VERSION ""

NS_ :

BS_:

BU_: HCM IPMA_ADAS PSCM GWM _delete SCCM PDM DDM GENERIC TSTR

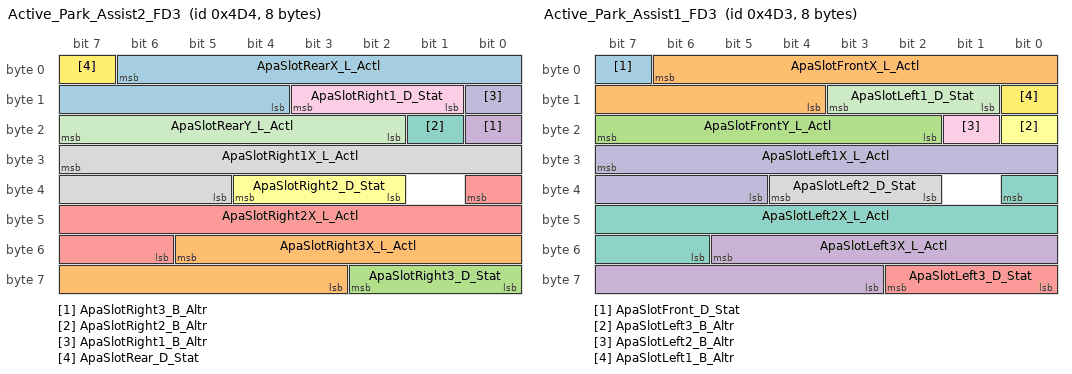
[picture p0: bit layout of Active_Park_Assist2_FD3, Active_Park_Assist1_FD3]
BO_ 1236 Active_Park_Assist2_FD3: 8 IPMA_ADAS
 SG_ ApaSlotRearX_L_Actl : 6|11@0+ (0.02,-20.96) [-20.96|19.98] "meter" Vector__XXX
 SG_ ApaSlotRight3X_L_Actl : 53|11@0+ (0.02,-20.96) [-20.96|19.98] "meter"  GWM
 SG_ ApaSlotRight3_D_Stat : 58|3@0+ (1,0) [0|7] "SED"  GWM
 SG_ ApaSlotRight3_B_Altr : 16|1@0+ (1,0) [0|1] "SED"  GWM
 SG_ ApaSlotRight2X_L_Actl : 32|11@0+ (0.02,-20.96) [-20.96|19.98] "meter"  GWM
 SG_ ApaSlotRight2_D_Stat : 36|3@0+ (1,0) [0|7] "SED"  GWM
 SG_ ApaSlotRight2_B_Altr : 17|1@0+ (1,0) [0|1] "SED"  GWM
 SG_ ApaSlotRight1X_L_Actl : 31|11@0+ (0.02,-20.96) [-20.96|19.98] "meter"  GWM
 SG_ ApaSlotRight1_D_Stat : 11|3@0+ (1,0) [0|7] "SED"  GWM
 SG_ ApaSlotRight1_B_Altr : 8|1@0+ (1,0) [0|1] "SED"  GWM
 SG_ ApaSlotRearY_L_Actl : 23|6@0+ (0.2,-6.4) [-6.4|6.2] "meter" Vector__XXX
 SG_ ApaSlotRear_D_Stat : 7|1@0+ (1,0) [0|1] "SED" Vector__XXX

BO_ 1235 Active_Park_Assist1_FD3: 8 IPMA_ADAS
 SG_ ApaSlotFront_D_Stat : 7|1@0+ (1,0) [0|1] "SED" Vector__XXX
 SG_ ApaSlotFrontX_L_Actl : 6|11@0+ (0.02,-20.96) [-20.96|19.98] "meter" Vector__XXX
 SG_ ApaSlotFrontY_L_Actl : 23|6@0+ (0.2,-6.4) [-6.4|6.2] "meter" Vector__XXX
 SG_ ApaSlotLeft3X_L_Actl : 53|11@0+ (0.02,-20.96) [-20.96|19.98] "meter"  GWM
 SG_ ApaSlotLeft3_D_Stat : 58|3@0+ (1,0) [0|7] "SED"  GWM
 SG_ ApaSlotLeft3_B_Altr : 16|1@0+ (1,0) [0|1] "SED"  GWM
 SG_ ApaSlotLeft2X_L_Actl : 32|11@0+ (0.02,-20.96) [-20.96|19.98] "meter"  GWM
 SG_ ApaSlotLeft2_D_Stat : 36|3@0+ (1,0) [0|7] "SED"  GWM
 SG_ ApaSlotLeft2_B_Altr : 17|1@0+ (1,0) [0|1] "SED"  GWM
 SG_ ApaSlotLeft1X_L_Actl : 31|11@0+ (0.02,-20.96) [-20.96|19.98] "meter"  GWM
 SG_ ApaSlotLeft1_D_Stat : 11|3@0+ (1,0) [0|7] "SED"  GWM
 SG_ ApaSlotLeft1_B_Altr : 8|1@0+ (1,0) [0|1] "SED"  GWM

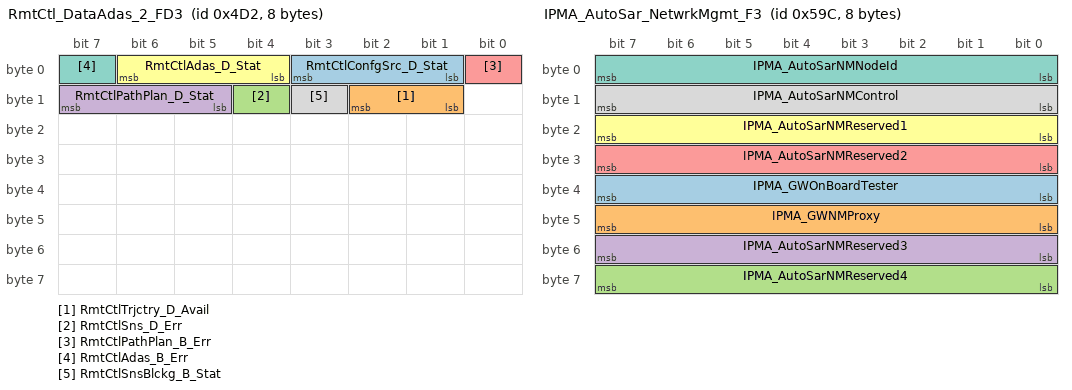
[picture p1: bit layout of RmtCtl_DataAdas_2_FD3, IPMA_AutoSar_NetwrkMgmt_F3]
BO_ 1234 RmtCtl_DataAdas_2_FD3: 8 IPMA_ADAS
 SG_ RmtCtlConfgSrc_D_Stat : 3|3@0+ (1,0) [0|7] "SED"  GWM
 SG_ RmtCtlTrjctry_D_Avail : 10|2@0+ (1,0) [0|3] "SED"  GWM
 SG_ RmtCtlSns_D_Err : 12|1@0+ (1,0) [0|1] "SED"  GWM
 SG_ RmtCtlPathPlan_D_Stat : 15|3@0+ (1,0) [0|7] "SED"  GWM
 SG_ RmtCtlPathPlan_B_Err : 0|1@0+ (1,0) [0|1] "SED"  GWM
 SG_ RmtCtlAdas_D_Stat : 6|3@0+ (1,0) [0|7] "SED"  GWM
 SG_ RmtCtlAdas_B_Err : 7|1@0+ (1,0) [0|1] "SED"  GWM
 SG_ RmtCtlSnsBlckg_B_Stat : 11|1@0+ (1,0) [0|1] "SED"  GWM

BO_ 1436 IPMA_AutoSar_NetwrkMgmt_F3: 8 IPMA_ADAS
 SG_ IPMA_GWOnBoardTester : 39|8@0+ (1,0) [0|255] "unitless"  GENERIC
 SG_ IPMA_GWNMProxy : 47|8@0+ (1,0) [0|255] "unitless"  GENERIC
 SG_ IPMA_AutoSarNMReserved4 : 63|8@0+ (1,0) [0|255] "unitless"  GENERIC
 SG_ IPMA_AutoSarNMReserved3 : 55|8@0+ (1,0) [0|255] "unitless"  GENERIC
 SG_ IPMA_AutoSarNMReserved2 : 31|8@0+ (1,0) [0|255] "unitless"  GENERIC
 SG_ IPMA_AutoSarNMReserved1 : 23|8@0+ (1,0) [0|255] "unitless"  GENERIC
 SG_ IPMA_AutoSarNMNodeId : 7|8@0+ (1,0) [0|255] "unitless"  GENERIC
 SG_ IPMA_AutoSarNMControl : 15|8@0+ (1,0) [0|255] "unitless"  GENERIC

BO_ 1233 RmtCtl_DataAdas_1_FD3: 8 IPMA_ADAS
 SG_ FreeDrvRear_D_Avail : 27|2@0+ (1,0) [0|3] "SED"  GWM
 SG_ FreeDrvFwd_D_Avail : 7|2@0+ (1,0) [0|3] "SED"  GWM
 SG_ RmtCtlTrgDist_D_Stat : 63|8@0+ (0.1,0) [0|25.5] "meter"  GWM
 SG_ RmtCtlSnsRrCrnr_D_Stat : 55|2@0+ (1,0) [0|3] "SED"  GWM
 SG_ RmtCtlSnsRlCrnr_D_Stat : 49|2@0+ (1,0) [0|3] "SED"  GWM
 SG_ RmtCtlSnsRear_D_Stat : 51|2@0+ (1,0) [0|3] "SED"  GWM
 SG_ RmtCtlSnsFront_D_Stat : 53|2@0+ (1,0) [0|3] "SED"  GWM
 SG_ RmtCtlSnsFrCrnr_D_Stat : 41|2@0+ (1,0) [0|3] "SED"  GWM
 SG_ RmtCtlSnsFlCrnr_D_Stat : 43|2@0+ (1,0) [0|3] "SED"  GWM
 SG_ RmtCtlSideSnsR4_D_Stat : 45|2@0+ (1,0) [0|3] "SED"  GWM
 SG_ RmtCtlSideSnsR3_D_Stat : 47|2@0+ (1,0) [0|3] "SED"  GWM
 SG_ RmtCtlSideSnsR2_D_Stat : 33|2@0+ (1,0) [0|3] "SED"  GWM
 SG_ RmtCtlSideSnsR1_D_Stat : 35|2@0+ (1,0) [0|3] "SED"  GWM
 SG_ RmtCtlSideSnsL4_D_Stat : 37|2@0+ (1,0) [0|3] "SED"  GWM
 SG_ RmtCtlSideSnsL3_D_Stat : 39|2@0+ (1,0) [0|3] "SED"  GWM
 SG_ RmtCtlSideSnsL2_D_Stat : 25|2@0+ (1,0) [0|3] "SED"  GWM
 SG_ RmtCtlSideSnsL1_D_Stat : 17|2@0+ (1,0) [0|3] "SED"  GWM
 SG_ RmtCtlRightOrnt_D_Avail : 20|3@0+ (1,0) [0|7] "SED"  GWM
 SG_ RmtCtlRight_D_Avail : 31|2@0+ (1,0) [0|3] "SED"  GWM
 SG_ RmtCtlRear_D_Avail : 29|2@0+ (1,0) [0|3] "SED"  GWM
 SG_ RmtCtlPrkMde_D_Stat : 9|2@0+ (1,0) [0|3] "SED"  GWM
 SG_ RmtCtlPrkInSlot_D_Stat : 23|3@0+ (1,0) [0|7] "SED"  GWM
 SG_ RmtCtlObstcl_B_Stat : 10|1@0+ (1,0) [0|1] "SED"  GWM
 SG_ RmtCtlNxtMoveDir_D_Stat : 12|2@0+ (1,0) [0|3] "SED"  GWM
 SG_ RmtCtlMoveDir_D_Stat : 1|2@0+ (1,0) [0|3] "SED"  GWM
 SG_ RmtCtlLeftOrnt_D_Avail : 15|3@0+ (1,0) [0|7] "SED"  GWM
 SG_ RmtCtlLeft_D_Avail : 3|2@0+ (1,0) [0|3] "SED"  GWM
 SG_ RmtCtlFront_D_Avail : 5|2@0+ (1,0) [0|3] "SED"  GWM

BO_ 817 Locking_Systems_2_FD3: 16 GWM
 SG_ ChildLckMde_B_Stat : 56|1@0+ (1,0) [0|1] "SED"  GENERIC
 SG_ VehLckInd_D_Rq : 58|2@0+ (1,0) [0|3] "SED"  PDM,DDM
 SG_ DrTgateOpen_B_Rq : 59|1@0+ (1,0) [0|1] "SED"  GENERIC
 SG_ DrTgateExtSwMde_B_Stat : 32|1@0+ (1,0) [0|1] "SED"  GENERIC
 SG_ Remote_Device_Feedback : 50|3@0+ (1,0) [0|7] "SED"  GENERIC
 SG_ Veh_Lock_Requestor : 55|5@0+ (1,0) [0|31] "SED"  PDM,DDM
 SG_ R_Pwr_Sliding_Dr_Rqst : 36|1@0+ (1,0) [0|1] "SED"  GENERIC
 SG_ Power_Liftgate_Rqst : 0|1@0+ (1,0) [0|1] "SED"  GENERIC
 SG_ Veh_Lock_EvNum : 47|8@0+ (1,0) [0|255] "unitless"  PDM,DDM
 SG_ Power_Decklid_Rqst : 1|1@0+ (1,0) [0|1] "SED"  GENERIC
 SG_ L_Pwr_Sliding_Dr_Rqst : 3|1@0+ (1,0) [0|1] "SED"  GENERIC
 SG_ Keyfob_Pad_Msg_Count : 15|8@0+ (1,0) [0|255] "Counts"  GENERIC
 SG_ Veh_Lock_Sub_Id : 63|4@0+ (1,0) [0|15] "SED"  PDM,DDM
 SG_ Veh_Lock_Status : 34|2@0+ (1,0) [0|3] "SED"  PDM,DDM,IPMA_ADAS
 SG_ WindowLockout_B_Stat : 35|1@0+ (1,0) [0|1] "SED"  DDM
 SG_ RollCodeUnlock : 23|16@0+ (1,0) [0|65535] "unitless"  PDM,DDM
 SG_ Lockmsgtxt_D_Rq : 39|3@0+ (1,0) [0|7] "SED"  GENERIC
 SG_ FobComm_D_Stat : 5|2@0+ (1,0) [0|3] "SED"  GENERIC
 SG_ LockInhibit : 2|1@0+ (1,0) [0|1] "SED"  GENERIC

BO_ 2612194520 PARSEDPushFcGWM_ECGtoCMR: 8 GWM
 SG_ PARSEDPushFcGWM_ECGtoCMR : 7|29@0+ (1,0) [0|536870911] "unitless" Vector__XXX

BO_ 2611145944 PARSEDPhyGWM_ECGtoCMR: 64 GWM
 SG_ PARSEDPhysGWM_ECGtoCMR : 7|29@0+ (1,0) [0|536870911] "unitless" Vector__XXX

BO_ 954 Body_Info_10_FD3: 16 GWM
 SG_ CrtsyLghtRear_D_Stat : 63|2@0+ (1,0) [0|3] "SED"  _delete
 SG_ LoadShedRelayMde_D_Stat : 53|2@0+ (1,0) [0|3] "SED"  _delete
 SG_ CargoLght_D_Stat : 55|2@0+ (1,0) [0|3] "SED"  _delete
 SG_ KeylessIdl_B_Stat : 41|1@0+ (1,0) [0|1] "SED"  _delete
 SG_ TlghtTestLght_D_Stat : 44|3@0+ (1,0) [0|7] "SED"  _delete
 SG_ TlghtTestPrecnd_D_Stat : 47|3@0+ (1,0) [0|7] "SED"  _delete
 SG_ TlghtTest_D_Stat : 33|2@0+ (1,0) [0|3] "SED"  _delete
 SG_ LghtAmbDrvMde_B_Stat : 34|1@0+ (1,0) [0|1] "SED"  _delete
 SG_ TrukBedLght_B_Stat : 24|1@0+ (1,0) [0|1] "SED"  _delete
 SG_ TrlrHitchLamp_D_Stat : 25|1@0+ (1,0) [0|1] "SED"  _delete
 SG_ LicPlateLght_B_Stat : 26|1@0+ (1,0) [0|1] "SED"  _delete
 SG_ ExtLghtRight_D_Stat : 21|2@0+ (1,0) [0|3] "SED"  _delete
 SG_ ExtLghtRear_D_Stat : 23|2@0+ (1,0) [0|3] "SED"  _delete
 SG_ ExtLghtLeft_D_Stat : 9|2@0+ (1,0) [0|3] "SED"  _delete
 SG_ ExtLghtFront_D_Stat : 11|2@0+ (1,0) [0|3] "SED"  _delete
 SG_ ExtLghtAlrt_B_Rq : 12|1@0+ (1,0) [0|1] "SED"  _delete
 SG_ ExtLght_D_Falt : 1|2@0+ (1,0) [0|3] "SED"  _delete
 SG_ TrlrHitchLamp_D2_Stat : 57|2@0+ (1,0) [0|3] "SED" Vector__XXX
 SG_ ChildLckMaint_D_Stat : 59|2@0+ (1,0) [0|3] "SED"  IPMA_ADAS
 SG_ ExtLghtFront_D_RqBody : 61|2@0+ (1,0) [0|3] "SED"  HCM
 SG_ LoadShedRelay_B_Rq : 40|1@0+ (1,0) [0|1] "SED" Vector__XXX
 SG_ VehWlcmFrwlMde_D_Stat : 29|3@0+ (1,0) [0|7] "SED"  PDM,DDM,HCM
 SG_ PwRnngBoardPoll_D_Stat : 36|2@0+ (1,0) [0|3] "SED"  PDM
 SG_ GenericSwtch3_No_Actl : 15|3@0+ (1,0) [0|7] "unitless"  HCM
 SG_ GenericSwtch2_No_Actl : 4|3@0+ (1,0) [0|7] "unitless"  HCM
 SG_ GenericSwtch1_No_Actl : 7|3@0+ (1,0) [0|7] "unitless"  HCM
 SG_ PudSptLghtRight_D_Rq : 17|2@0+ (1,0) [0|3] "SED"  PDM,DDM
 SG_ PudSptLghtLeft_D_Rq : 19|2@0+ (1,0) [0|3] "SED"  PDM,DDM
 SG_ PoliceDmngLvl_D_Stat : 39|3@0+ (1,0) [0|7] "SED"  PDM,DDM
 SG_ VehWlcmFrwl_D_Stat : 31|2@0+ (1,0) [0|3] "SED"  PDM,DDM,HCM
 SG_ PosLghtFr_D_Stat : 49|2@0+ (1,0) [0|3] "SED"  HCM
 SG_ PosLghtFl_D_Stat : 51|2@0+ (1,0) [0|3] "SED"  HCM

BO_ 1844 TesterPhysicalReqHCM: 64 TSTR
 SG_ TesterPhysicalReqHCM : 7|64@0+ (1,0) [0|1.84467E+019] "unitless"  HCM

BO_ 1852 TesterPhysicalResHCM: 64 HCM
 SG_ TesterPhysicalResHCM : 7|64@0+ (1,0) [0|1.84467E+019] "unitless"  TSTR

BO_ 989 Personality_HCM_Data: 8 HCM
 SG_ FeatNoHcm_No_Actl : 23|16@0+ (1,0) [0|65535] "Number"  GWM
 SG_ FeatConfigHcmActl : 7|16@0+ (1,0) [0|65535] "Undefined"  GWM

BO_ 820 Adaptive_Headlamp_Stat: 16 HCM
 SG_ AhbStatGfhbFdbk_D_Actl : 53|2@0+ (1,0) [0|3] "SED"  SCCM,GWM,IPMA_ADAS
 SG_ TurnLampFrOut_B_Stat : 5|1@0+ (1,0) [0|1] "SED"  GWM
 SG_ TurnLampFlOut_B_Stat : 6|1@0+ (1,0) [0|1] "SED"  GWM
 SG_ HeadLghtDrvSide_B_Stat : 33|1@0+ (1,0) [0|1] "SED"  GWM,IPMA_ADAS
 SG_ HeadLghtHiOn_B_StatHcm : 0|1@0+ (1,0) [0|1] "SED"  GWM
 SG_ Adaptive_Hdlmp_Fault : 7|1@0+ (1,0) [0|1] "SED"  GWM

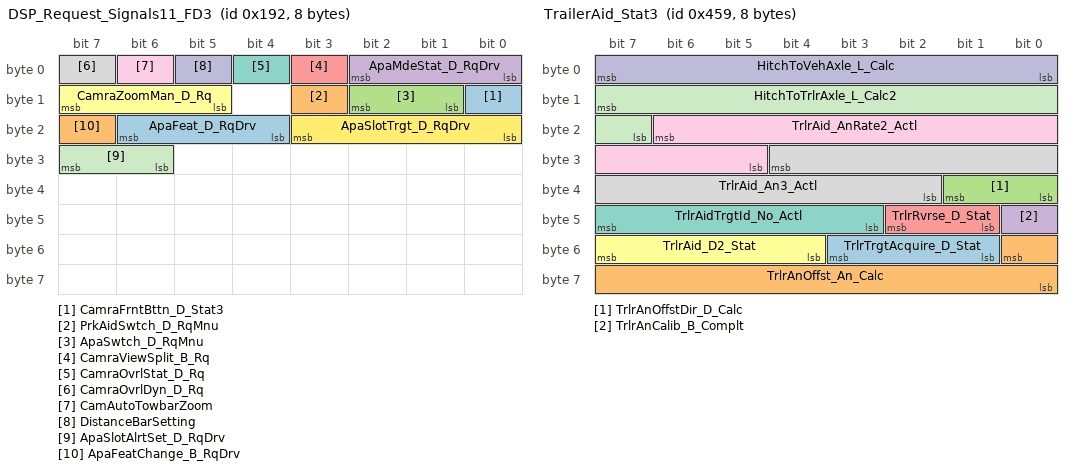
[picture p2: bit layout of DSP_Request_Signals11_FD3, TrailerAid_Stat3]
BO_ 402 DSP_Request_Signals11_FD3: 8 GWM
 SG_ CamraFrntBttn_D_Stat3 : 8|1@0+ (1,0) [0|1] "SED"  IPMA_ADAS
 SG_ PrkAidSwtch_D_RqMnu : 11|1@0+ (1,0) [0|1] "SED"  IPMA_ADAS
 SG_ ApaSwtch_D_RqMnu : 10|2@0+ (1,0) [0|3] "SED"  IPMA_ADAS
 SG_ ApaMdeStat_D_RqDrv : 2|3@0+ (1,0) [0|7] "SED"  IPMA_ADAS
 SG_ CamraViewSplit_B_Rq : 3|1@0+ (1,0) [0|1] "SED" Vector__XXX
 SG_ CamraZoomMan_D_Rq : 15|3@0+ (1,0) [0|7] "SED" Vector__XXX
 SG_ CamraOvrlStat_D_Rq : 4|1@0+ (1,0) [0|1] "SED" Vector__XXX
 SG_ CamraOvrlDyn_D_Rq : 7|1@0+ (1,0) [0|1] "SED" Vector__XXX
 SG_ CamAutoTowbarZoom : 6|1@0+ (1,0) [0|1] "SED" Vector__XXX
 SG_ DistanceBarSetting : 5|1@0+ (1,0) [0|1] "SED" Vector__XXX
 SG_ ApaSlotAlrtSet_D_RqDrv : 31|2@0+ (1,0) [0|3] "SED"  IPMA_ADAS
 SG_ ApaSlotTrgt_D_RqDrv : 19|4@0+ (1,0) [0|15] "SED"  IPMA_ADAS
 SG_ ApaFeat_D_RqDrv : 22|3@0+ (1,0) [0|7] "SED"  IPMA_ADAS
 SG_ ApaFeatChange_B_RqDrv : 23|1@0+ (1,0) [0|1] "SED"  IPMA_ADAS

BO_ 2612170968 PARSEDPushFcGWM_ECGtoPDM: 8 GWM
 SG_ PARSEDPushFcGWM_ECGtoPDM : 7|29@0+ (1,0) [0|536870911] "unitless"  PDM

BO_ 2612166872 PARSEDPushFcGWM_ECGtoDDM: 8 GWM
 SG_ PARSEDPushFcGWM_ECGtoDDM : 7|29@0+ (1,0) [0|536870911] "unitless"  DDM

BO_ 2611122392 PARSEDPhysGWM_ECGtoPDM: 64 GWM
 SG_ PARSEDPhysGWM_ECGtoPDM : 7|29@0+ (1,0) [0|536870911] "unitless"  PDM

BO_ 2611118296 PARSEDPhysGWM_ECGtoDDM: 64 GWM
 SG_ PARSEDPhysGWM_ECGtoDDM : 7|29@0+ (1,0) [0|536870911] "unitless"  DDM

BO_ 2612224164 PARSEDPushPDMtoGWM_ECG: 8 PDM
 SG_ PARSEDPushPDMtoGWM_ECG : 7|29@0+ (1,0) [0|536870911] "unitless"  GWM

BO_ 2612224160 PARSEDPushDDMtoGWM_ECG: 8 DDM
 SG_ PARSEDPushDDMtoGWM_ECG : 7|29@0+ (1,0) [0|536870911] "unitless"  GWM

BO_ 2611175588 PARSEDPhysPDMtoGWM_ECG: 64 PDM
 SG_ PARSEDPhysPDMtoGWM_ECG : 7|29@0+ (1,0) [0|536870911] "unitless"  GWM

BO_ 2611175584 PARSEDPhysDDMtoGWM_ECG: 64 DDM
 SG_ PARSEDPhysDDMtoGWM_ECG : 7|29@0+ (1,0) [0|536870911] "unitless"  GWM

BO_ 2610073816 OTAPhysGWM_ECGtoPDM: 64 GWM
 SG_ OTAPhysGWM_ECGtoPDM : 7|29@0+ (1,0) [0|536870911] "unitless"  PDM

BO_ 2610069720 OTAPhysGWM_ECGtoDDM: 64 GWM
 SG_ OTAPhysGWM_ECGtoDDM : 7|29@0+ (1,0) [0|536870911] "unitless"  DDM

BO_ 2610127012 OTAPhysPDMtoGWM_ECG: 64 PDM
 SG_ OTAPhysPDMtoGWM_ECG : 7|29@0+ (1,0) [0|536870911] "unitless"  GWM

BO_ 2610127008 OTAPhysDDMtoGWM_ECG: 64 DDM
 SG_ OTAPhysDDMtoGWM_ECG : 7|29@0+ (1,0) [0|536870911] "unitless"  GWM

BO_ 1814 TesterPhysicalReqGWM_FD3: 64 TSTR
 SG_ TesterPhysicalReqGWM_F3 : 7|64@0+ (1,0) [0|1.84467E+019] "unitless"  GWM

BO_ 1113 TrailerAid_Stat3: 8 IPMA_ADAS
 SG_ TrlrTrgtAcquire_D_Stat : 51|3@0+ (1,0) [0|7] "SED"  PSCM,GWM
 SG_ TrlrAnOffst_An_Calc : 48|9@0+ (0.1,0) [0|51.1] "degrees"  PSCM,GWM
 SG_ TrlrAnOffstDir_D_Calc : 33|2@0+ (1,0) [0|3] "SED"  PSCM,GWM
 SG_ TrlrAnCalib_B_Complt : 40|1@0+ (1,0) [0|1] "SED"  GWM
 SG_ TrlrRvrse_D_Stat : 42|2@0+ (1,0) [0|3] "SED"  PSCM,GWM
 SG_ TrlrAid_D2_Stat : 55|4@0+ (1,0) [0|15] "SED"  PSCM,GWM
 SG_ TrlrAidTrgtId_No_Actl : 47|5@0+ (1,0) [0|31] "unitless"  PSCM,GWM
 SG_ TrlrAid_An3_Actl : 28|11@0+ (0.125,-90) [-90|165.75] "degrees"  PSCM,GWM
 SG_ TrlrAid_AnRate2_Actl : 22|10@0+ (0.125,-50) [-50|77.75] "degrees/sec"  PSCM,GWM
 SG_ HitchToVehAxle_L_Calc : 7|8@0+ (0.0127,-0.508) [-0.508|2.7178] "meter"  PSCM,GWM
 SG_ HitchToTrlrAxle_L_Calc2 : 15|9@0+ (0.0254,0) [0|12.9794] "meter"  GWM

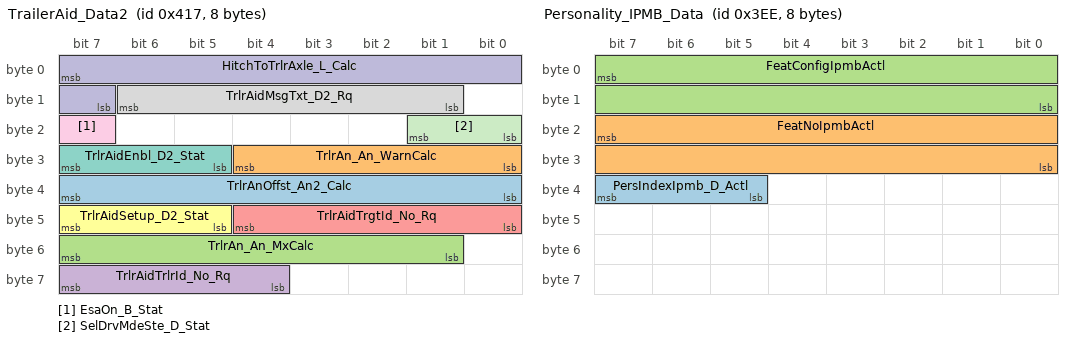
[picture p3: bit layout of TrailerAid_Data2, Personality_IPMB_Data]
BO_ 1047 TrailerAid_Data2: 8 PSCM
 SG_ TrlrAnOffst_An2_Calc : 39|8@0+ (0.5,-64) [-64|63.5] "degrees"  IPMA_ADAS,GWM
 SG_ TrlrAn_An_WarnCalc : 28|5@0+ (1,0) [0|31] "degrees"  IPMA_ADAS,GWM
 SG_ TrlrAn_An_MxCalc : 55|7@0+ (1,0) [0|127] "degrees"  IPMA_ADAS,GWM
 SG_ TrlrAidTrlrId_No_Rq : 63|4@0+ (1,0) [0|15] "unitless"  GWM
 SG_ TrlrAidTrgtId_No_Rq : 44|5@0+ (1,0) [0|31] "unitless"  IPMA_ADAS,GWM
 SG_ TrlrAidSetup_D2_Stat : 47|3@0+ (1,0) [0|7] "SED"  IPMA_ADAS,GWM
 SG_ TrlrAidEnbl_D2_Stat : 31|3@0+ (1,0) [0|7] "SED"  IPMA_ADAS,GWM
 SG_ TrlrAidMsgTxt_D2_Rq : 14|6@0+ (1,0) [0|63] "SED"  IPMA_ADAS,GWM
 SG_ EsaOn_B_Stat : 23|1@0+ (1,0) [0|1] "SED"  GWM
 SG_ HitchToTrlrAxle_L_Calc : 7|9@0+ (0.0254,0) [0|12.9794] "meter"  IPMA_ADAS,GWM
 SG_ SelDrvMdeSte_D_Stat : 17|2@0+ (1,0) [0|3] "SED"  GWM

BO_ 1006 Personality_IPMB_Data: 8 IPMA_ADAS
 SG_ PersIndexIpmb_D_Actl : 39|3@0+ (1,0) [0|7] "SED"  GWM
 SG_ FeatNoIpmbActl : 23|16@0+ (1,0) [0|65535] "Number"  GWM
 SG_ FeatConfigIpmbActl : 7|16@0+ (1,0) [0|65535] "Undefined"  GWM

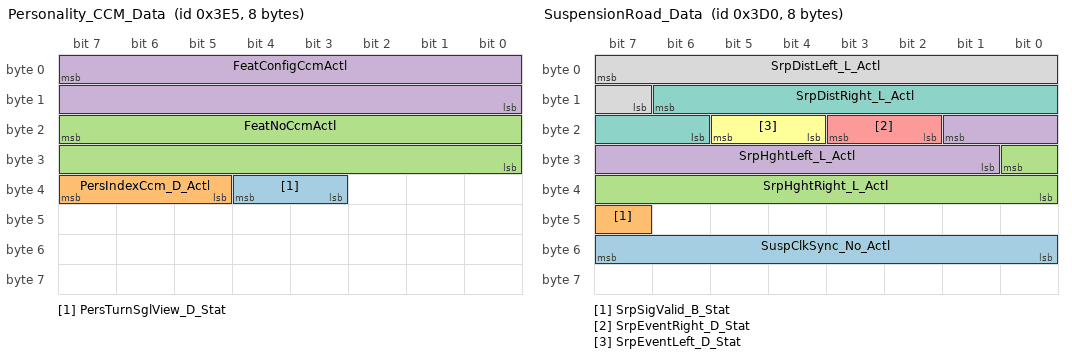
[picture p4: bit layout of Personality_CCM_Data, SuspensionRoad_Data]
BO_ 997 Personality_CCM_Data: 8 IPMA_ADAS
 SG_ PersTurnSglView_D_Stat : 36|2@0+ (1,0) [0|3] "SED"  GWM
 SG_ PersIndexCcm_D_Actl : 39|3@0+ (1,0) [0|7] "SED"  GWM
 SG_ FeatNoCcmActl : 23|16@0+ (1,0) [0|65535] "Number"  GWM
 SG_ FeatConfigCcmActl : 7|16@0+ (1,0) [0|65535] "Undefined"  GWM

BO_ 973 Traffic_RecognitnData: 8 IPMA_ADAS
 SG_ PersCtaSplitView_D_Stat : 12|2@0+ (1,0) [0|3] "SED"  GWM
 SG_ LaSysOffStat_D_Dsply : 58|2@0+ (1,0) [0|3] "SED"  GWM
 SG_ TsrVl2PrmntMsgTxt_D_Rq : 60|2@0+ (1,0) [0|3] "SED"  GWM
 SG_ TsrVl1PrmntMsgTxt_D_Rq : 41|2@0+ (1,0) [0|3] "SED"  GWM
 SG_ TsrVl2RstrcMsgTxt2_D_Rq : 63|3@0+ (1,0) [0|7] "SED"  GWM
 SG_ TsrVl1RstrcMsgTxt2_D_Rq : 51|3@0+ (1,0) [0|7] "SED"  GWM
 SG_ TsrOvtkMsgTxt2_D_Rq : 55|4@0+ (1,0) [0|15] "SED"  GWM
 SG_ WwaWarn_B_Rq : 48|1@0+ (1,0) [0|1] "SED"  GWM
 SG_ TsrVlUnitMsgTxt_D_Rq : 43|2@0+ (1,0) [0|3] "SED"  GWM
 SG_ TsrVLim2MsgTxt_D_Rq : 39|8@0+ (1,0) [0|255] "SED"  GWM
 SG_ TsrVLim1MsgTxt_D_Rq : 31|8@0+ (1,0) [0|255] "SED"  GWM
 SG_ TsrVl2StatMsgTxt_D_Rq : 47|2@0+ (1,0) [0|3] "SED"  GWM
 SG_ TsrVl2RstrcMsgTxt_D_Rq : 17|2@0+ (1,0) [0|3] "SED"  GWM
 SG_ TsrVl1StatMsgTxt_D_Rq : 21|2@0+ (1,0) [0|3] "SED"  GWM
 SG_ TsrVl1RstrcMsgTxt_D_Rq : 23|2@0+ (1,0) [0|3] "SED"  GWM
 SG_ TsrStatMsgTxt_D_Rq : 10|3@0+ (1,0) [0|7] "SED"  GWM
 SG_ TsrOvtkStatMsgTxt_D_Rq : 1|2@0+ (1,0) [0|3] "SED"  GWM
 SG_ TsrOvtkMsgTxt_D_Rq : 15|3@0+ (1,0) [0|7] "SED"  GWM
 SG_ TsrOswWarnMsgTxt_D_Rq : 3|2@0+ (1,0) [0|3] "SED"  GWM
 SG_ TsrMsgTxt_D_Rq : 7|4@0+ (1,0) [0|15] "SED"  GWM
 SG_ RoadSignRgltry_D_Dsply : 19|2@0+ (1,0) [0|3] "SED"  GWM

BO_ 976 SuspensionRoad_Data: 8 IPMA_ADAS
 SG_ SuspClkSync_No_Actl : 55|8@0+ (1,0) [0|253] "unitless"  GWM
 SG_ SrpSigValid_B_Stat : 47|1@0+ (1,0) [0|1] "SED"  GWM
 SG_ SrpHghtRight_L_Actl : 24|9@0+ (0.000625,-0.16) [-0.16|0.158125] "meter"  GWM
 SG_ SrpHghtLeft_L_Actl : 17|9@0+ (0.000625,-0.16) [-0.16|0.158125] "meter"  GWM
 SG_ SrpEventRight_D_Stat : 19|2@0+ (1,0) [0|3] "SED"  GWM
 SG_ SrpEventLeft_D_Stat : 21|2@0+ (1,0) [0|3] "SED"  GWM
 SG_ SrpDistRight_L_Actl : 14|9@0+ (0.02,0) [0|10.18] "meter"  GWM
 SG_ SrpDistLeft_L_Actl : 7|9@0+ (0.02,0) [0|10.18] "meter"  GWM

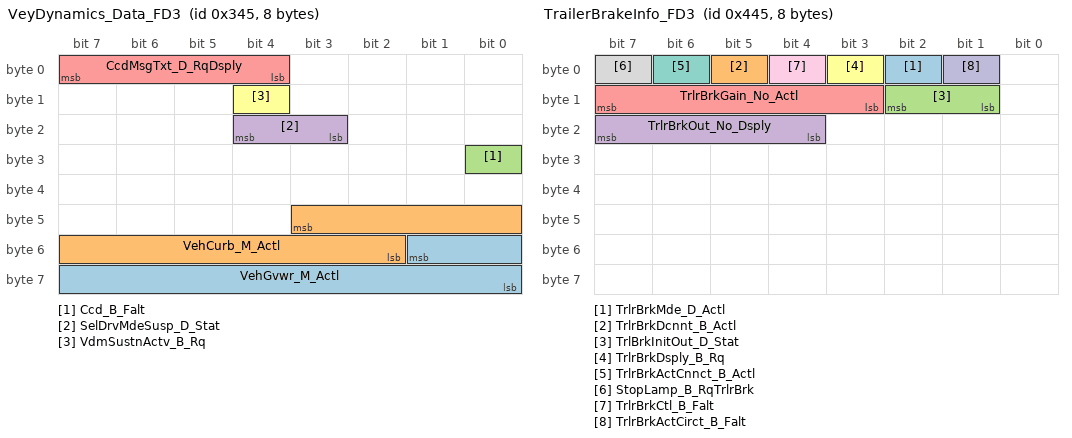
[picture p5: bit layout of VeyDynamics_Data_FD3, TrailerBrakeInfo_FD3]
BO_ 837 VeyDynamics_Data_FD3: 8 GWM
 SG_ VehGvwr_M_Actl : 49|10@0+ (10,0) [0|10210] "kilogram"  _delete
 SG_ VehCurb_M_Actl : 43|10@0+ (5,0) [0|5105] "kilogram"  _delete
 SG_ Ccd_B_Falt : 24|1@0+ (1,0) [0|1] "SED"  _delete
 SG_ SelDrvMdeSusp_D_Stat : 20|2@0+ (1,0) [0|3] "SED"  _delete
 SG_ CcdMsgTxt_D_RqDsply : 7|4@0+ (1,0) [0|15] "SED"  _delete
 SG_ VdmSustnActv_B_Rq : 12|1@0+ (1,0) [0|1] "SED" Vector__XXX

BO_ 982 LateralMotionControl2: 16 IPMA_ADAS
 SG_ LatCtlPathOffst_L_Actl : 33|10@0+ (0.01,-5.12) [-5.12|5.11] "meter"  PSCM,GWM
 SG_ LatCtlPath_An_Actl : 28|11@0+ (0.0005,-0.5) [-0.5|0.5235] "radians"  PSCM,GWM
 SG_ LatCtlCurv_No_Actl : 23|11@0+ (2E-005,-0.02) [-0.02|0.02094] "1/meter"  PSCM,GWM
 SG_ LatCtlRampType_D_Rq : 1|2@0+ (1,0) [0|3] "SED"  PSCM,GWM
 SG_ LatCtlPrecision_D_Rq : 3|2@0+ (1,0) [0|3] "SED"  PSCM,GWM
 SG_ HandsOffCnfm_B_Rq : 7|1@0+ (1,0) [0|1] "SED"  PSCM,GWM
 SG_ LatCtlCrv_NoRate2_Actl : 55|11@0+ (1E-006,-0.001024) [-0.001024|0.001023] "meter^2"  PSCM,GWM
 SG_ LatCtlPath_No_Cnt : 60|4@0+ (1,0) [0|15] "unitless"  PSCM,GWM
 SG_ LatCtlPath_No_Cs : 15|8@0+ (1,0) [0|255] "unitless"  PSCM,GWM
 SG_ LatCtl_D2_Rq : 6|3@0+ (1,0) [0|7] "SED"  PSCM,GWM

BO_ 2611070168 PARSEDPhysGWM_ECGtoHCM: 64 GWM
 SG_ PARSEDPhysGWM_ECGtoHCM : 7|29@0+ (1,0) [0|536870911] "unitless"  HCM

BO_ 2611175537 PARSEDPhysHCMtoGWM_ECG: 64 HCM
 SG_ PARSEDPhysHCMtoGWM_ECG : 7|29@0+ (1,0) [0|536870911] "unitless"  GWM

BO_ 2610021592 OTAPhysGWM_ECGtoHCM: 64 GWM
 SG_ OTAPhysGWM_ECGtoHCM : 7|29@0+ (1,0) [0|536870911] "unitless"  HCM

BO_ 2610126961 OTAPhysHCMtoGWM_ECG: 64 HCM
 SG_ OTAPhysHCMtoGWM_ECG : 7|29@0+ (1,0) [0|536870911] "unitless"  GWM

BO_ 2610975960 PARSEDPhysGWM_ECGtoCCM: 64 GWM
 SG_ PARSEDPhysGWM_ECGtoCCM : 7|29@0+ (1,0) [0|536870911] "unitless"  IPMA_ADAS

BO_ 2611175445 PARSEDPhysCCMtoGWM_ECG: 64 IPMA_ADAS
 SG_ PARSEDPhysCCMtoGWM_ECG : 7|29@0+ (1,0) [0|536870911] "unitless"  GWM

BO_ 2612224021 PARSEDPushCCMtoGWM_ECG: 8 IPMA_ADAS
 SG_ PARSEDPushCCMtoGWM_ECG : 7|29@0+ (1,0) [0|536870911] "unitless"  GWM

BO_ 2611025112 PARSEDPhysGWM_ECGtoSODCMC: 64 GWM
 SG_ PARSEDPhysGWM_ECGtoSODCMC : 7|29@0+ (1,0) [0|536870911] "unitless"  IPMA_ADAS

BO_ 2611175493 PARSEDPhysSODCMCtoGWM_ECG: 64 IPMA_ADAS
 SG_ PARSEDPhysSODCMCtoGWM_ECG : 7|29@0+ (1,0) [0|536870911] "unitless"  GWM

BO_ 2612024536 PARSEDPushFcGWM_ECGtoCCM: 8 GWM
 SG_ PARSEDPushFcGWM_ECGtoCCM : 7|29@0+ (1,0) [0|536870911] "unitless"  IPMA_ADAS

BO_ 1200 ABS_BrkBst_Data_FD3: 16 GWM
 SG_ BrkRearPCorrltn_B_Stat : 35|1@0+ (1,0) [0|1] "SED" Vector__XXX
 SG_ BrkBstrVac_P_Actl : 7|7@0+ (8,0) [0|1008] "millibar" Vector__XXX
 SG_ YawStabilityIndex : 0|9@0+ (1,-256) [-256|255] "%"  IPMA_ADAS,PSCM
 SG_ BrkTot_Tq_RqDrv : 47|13@0+ (4,0) [0|32760] "Nm"  IPMA_ADAS,PSCM
 SG_ BrkTotTqRqDrv_No_Cnt : 39|4@0+ (1,0) [0|15] "unitless" Vector__XXX
 SG_ BrkTotTqRqDrv_No_Cs : 63|8@0+ (1,0) [0|255] "unitless" Vector__XXX
 SG_ BrkHold_D_Stat : 34|3@0+ (1,0) [0|7] "SED"  IPMA_ADAS

BO_ 1093 TrailerBrakeInfo_FD3: 8 GWM
 SG_ TrlrBrkMde_D_Actl : 2|1@0+ (1,0) [0|1] "SED"  _delete
 SG_ TrlrBrkDcnnt_B_Actl : 5|1@0+ (1,0) [0|1] "SED"  _delete
 SG_ TrlBrkInitOut_D_Stat : 10|2@0+ (1,0) [0|3] "SED" Vector__XXX
 SG_ TrlrBrkOut_No_Dsply : 23|4@0+ (1,0) [0|15] "unitless" Vector__XXX
 SG_ TrlrBrkGain_No_Actl : 15|5@0+ (0.5,0) [0|15.5] "unitless" Vector__XXX
 SG_ TrlrBrkDsply_B_Rq : 3|1@0+ (1,0) [0|1] "SED" Vector__XXX
 SG_ TrlrBrkActCnnct_B_Actl : 6|1@0+ (1,0) [0|1] "SED"  PSCM,IPMA_ADAS
 SG_ StopLamp_B_RqTrlrBrk : 7|1@0+ (1,0) [0|1] "SED" Vector__XXX
 SG_ TrlrBrkCtl_B_Falt : 4|1@0+ (1,0) [0|1] "SED"  IPMA_ADAS
 SG_ TrlrBrkActCirct_B_Falt : 1|1@0+ (1,0) [0|1] "SED"  IPMA_ADAS

BO_ 1787 TesterPhysicalResSODCMD: 64 IPMA_ADAS
 SG_ TesterPhysicalResSODCMD : 7|64@0+ (1,0) [0|1.84467E+019] "unitless"  TSTR

BO_ 1779 TesterPhysicalReqSODCMD: 64 TSTR
 SG_ TesterPhysicalReqSODCMD : 7|64@0+ (1,0) [0|1.84467E+019] "unitless"  IPMA_ADAS

BO_ 1786 TesterPhysicalResSODCMC: 64 IPMA_ADAS
 SG_ TesterPhysicalResSODCMC : 7|64@0+ (1,0) [0|1.84467E+019] "unitless"  TSTR

BO_ 935 Side_Detect_R_Stat: 16 IPMA_ADAS
 SG_ CtaAlrtRight2_D_Stat : 30|3@0+ (1,0) [0|7] "SED"  GWM
 SG_ BttRight_D_Stat : 45|3@0+ (1,0) [0|7] "SED"  GWM
 SG_ BttRight_D_RqDrv : 47|2@0+ (1,0) [0|3] "SED"  GWM
 SG_ CtaBrkRightMsgTxt_B_Rq : 42|1@0+ (1,0) [0|1] "SED"  GWM
 SG_ CtaRightBrkEnbl_B_Rq : 31|1@0+ (1,0) [0|1] "SED"  GWM
 SG_ CtaRightBrkDecel_B_Rq : 7|1@0+ (1,0) [0|1] "SED"  GWM
 SG_ Side_Detect_R_Illum : 39|8@0+ (1,0) [0|255] "Percent"  PDM,DDM,GWM
 SG_ CtaSnsRight_D_Stat : 25|2@0+ (1,0) [0|3] "SED"  GWM
 SG_ CtaAlrtRight_D_Stat : 8|1@0+ (1,0) [0|1] "SED"  PDM,DDM,GWM
 SG_ CtaRight_D_Stat : 18|3@0+ (1,0) [0|7] "SED"  GWM
 SG_ SodRight_D_Stat : 15|3@0+ (1,0) [0|7] "SED"  GWM
 SG_ SodSnsRight_D_Stat : 12|2@0+ (1,0) [0|3] "SED"  PDM,DDM,GWM
 SG_ SodAlrtRight_D_Stat : 10|2@0+ (1,0) [0|3] "SED"  PDM,DDM,GWM
 SG_ SodDetctRight_D_Stat : 23|3@0+ (1,0) [0|7] "SED"  GWM
 SG_ SodWarnRight_Prd_Rq : 6|7@0+ (1,0) [0|127] "millisecond"  PDM,DDM,GWM

BO_ 1087 Powertrain_Data_5_FD3: 16 GWM
 SG_ TrlrRngeDsply_B_Stat : 16|1@0+ (1,0) [0|1] "SED" Vector__XXX
 SG_ StopStrtImccTxt_D_Dspl : 63|4@0+ (1,0) [0|15] "SED" Vector__XXX
 SG_ StopStrtImccActv_D_St : 52|3@0+ (1,0) [0|7] "SED" Vector__XXX
 SG_ StopStrtImccTxt_D_Rq : 55|3@0+ (1,0) [0|7] "SED" Vector__XXX
 SG_ EngIdlShutDownT_D_Stat : 47|8@0+ (1,0) [0|255] "SED" Vector__XXX
 SG_ DcacFaltMsgTxt_D2_Rq : 39|6@0+ (1,0) [0|63] "SED" Vector__XXX
 SG_ ClimtCool_D_RqPt : 19|2@0+ (1,0) [0|3] "SED" Vector__XXX
 SG_ StrtInGearMsgTxt_D_Rq : 23|4@0+ (1,0) [0|15] "SED" Vector__XXX
 SG_ IgnOffInhbt_B_Stat : 9|1@0+ (1,0) [0|1] "SED" Vector__XXX
 SG_ BtsiShifInhbt_B_RqPt : 8|1@0+ (1,0) [0|1] "SED" Vector__XXX
 SG_ FapLcInhbt_B_Rq : 1|1@0+ (1,0) [0|1] "SED"  IPMA_ADAS
 SG_ FapLcStopHold_B_Rq : 2|1@0+ (1,0) [0|1] "SED" Vector__XXX
 SG_ FapLcPrchgBrk_B_Rq : 3|1@0+ (1,0) [0|1] "SED" Vector__XXX
 SG_ FapLcObstcl_B_Stat : 4|1@0+ (1,0) [0|1] "SED"  IPMA_ADAS
 SG_ FapLcMaxGrdInhbt_B_Stat : 5|1@0+ (1,0) [0|1] "SED"  IPMA_ADAS
 SG_ FapLcMaxGrdAbrt_B_Stat : 6|1@0+ (1,0) [0|1] "SED"  IPMA_ADAS
 SG_ FapLcActv_B_Stat : 7|1@0+ (1,0) [0|1] "SED"  IPMA_ADAS
 SG_ AdasLcObtclAbrt_B_Stat : 0|1@0+ (1,0) [0|1] "SED"  IPMA_ADAS

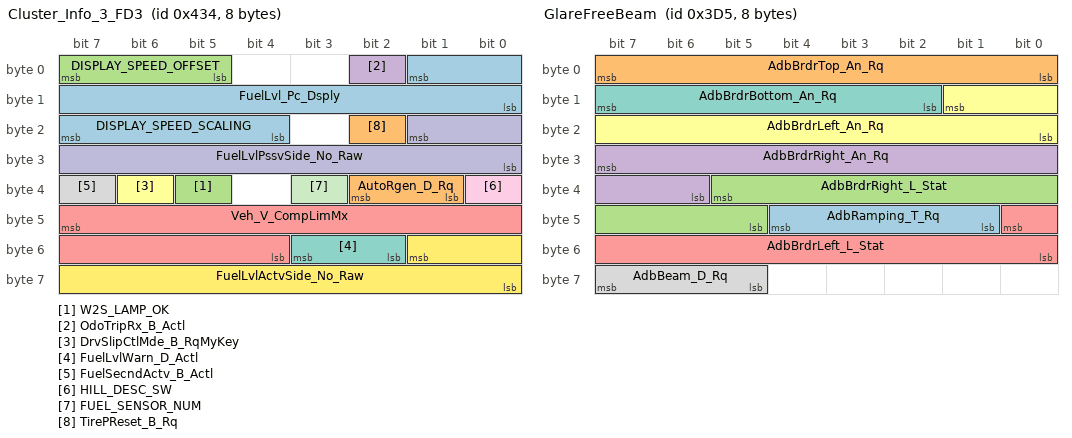
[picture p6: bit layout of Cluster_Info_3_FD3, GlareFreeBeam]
BO_ 1076 Cluster_Info_3_FD3: 8 GWM
 SG_ FuelLvl_Pc_Dsply : 1|10@0+ (0.108696,-5.217408) [-5.217408|105.9786] "Percent"  _delete
 SG_ AutoRgen_D_Rq : 34|2@0+ (1,0) [0|3] "SED" Vector__XXX
 SG_ W2S_LAMP_OK : 37|1@0+ (1,0) [0|1] "SED" Vector__XXX
 SG_ OdoTripRx_B_Actl : 2|1@0+ (1,0) [0|1] "SED" Vector__XXX
 SG_ Veh_V_CompLimMx : 47|12@0+ (0.1,0) [0|409.5] "km/h" Vector__XXX
 SG_ DrvSlipCtlMde_B_RqMyKey : 38|1@0+ (1,0) [0|1] "SED" Vector__XXX
 SG_ FuelLvlWarn_D_Actl : 51|2@0+ (1,0) [0|3] "SED" Vector__XXX
 SG_ FuelSecndActv_B_Actl : 39|1@0+ (1,0) [0|1] "SED" Vector__XXX
 SG_ HILL_DESC_SW : 32|1@0+ (1,0) [0|1] "SED" Vector__XXX
 SG_ FuelLvlPssvSide_No_Raw : 17|10@0+ (1,0) [0|1023] "unitless" Vector__XXX
 SG_ FUEL_SENSOR_NUM : 35|1@0+ (1,0) [0|1] "SED" Vector__XXX
 SG_ FuelLvlActvSide_No_Raw : 49|10@0+ (1,0) [0|1023] "unitless" Vector__XXX
 SG_ DISPLAY_SPEED_SCALING : 23|4@0+ (0.5,100) [100|107.5] "%"  IPMA_ADAS
 SG_ TirePReset_B_Rq : 18|1@0+ (1,0) [0|1] "SED" Vector__XXX
 SG_ DISPLAY_SPEED_OFFSET : 7|3@0+ (0.5,0) [0|3.5] "kph"  IPMA_ADAS

BO_ 2611026136 PARSEDPhysGWM_ECGtoSODCMD: 64 GWM
 SG_ PARSEDPhysGWM_ECGtoSODCMD : 7|29@0+ (1,0) [0|536870911] "unitless"  IPMA_ADAS

BO_ 2611175494 PARSEDPhysSODCMDtoGWM_ECG: 64 IPMA_ADAS
 SG_ PARSEDPhysSODCMDtoGWM_ECG : 7|29@0+ (1,0) [0|536870911] "unitless"  GWM

BO_ 2611054808 PARSEDPhysGWM_ECGtoSODL: 64 GWM
 SG_ PARSEDPhysGWM_ECGtoSODL : 7|29@0+ (1,0) [0|536870911] "unitless"  IPMA_ADAS

BO_ 2611175523 PARSEDPhysSODRtoGWM_ECG: 64 IPMA_ADAS
 SG_ PARSEDPhysSODRtoGWM_ECG : 7|29@0+ (1,0) [0|536870911] "unitless"  GWM

BO_ 2611055832 PARSEDPhysGWM_ECGtoSODR: 64 GWM
 SG_ PARSEDPhysGWM_ECGtoSODR : 7|29@0+ (1,0) [0|536870911] "unitless"  IPMA_ADAS

BO_ 2611175522 PARSEDPhysSODLtoGWM_ECG: 64 IPMA_ADAS
 SG_ PARSEDPhysSODLtoGWM_ECG : 7|29@0+ (1,0) [0|536870911] "unitless"  GWM

BO_ 2609927384 OTAPhysGWM_ECGtoCCM: 64 GWM
 SG_ OTAPhysGWM_ECGtoCCM : 7|29@0+ (1,0) [0|536870911] "unitless"  IPMA_ADAS

BO_ 2610126869 OTAPhysCCMtoGWM_ECG: 64 IPMA_ADAS
 SG_ OTAPhysCCMtoGWM_ECG : 7|29@0+ (1,0) [0|536870911] "unitless"  GWM

BO_ 2609976536 OTAPhysGWM_ECGtoSODCMC: 64 GWM
 SG_ OTAPhysGWM_ECGtoSODCMC : 7|29@0+ (1,0) [0|536870911] "unitless"  IPMA_ADAS

BO_ 2610126917 OTAPhysSODCMCtoGWM_ECG: 64 IPMA_ADAS
 SG_ OTAPhysSODCMCtoGWM_ECG : 7|29@0+ (1,0) [0|536870911] "unitless"  GWM

BO_ 2609977560 OTAPhysGWM_ECGtoSODCMD: 64 GWM
 SG_ OTAPhysGWM_ECGtoSODCMD : 7|29@0+ (1,0) [0|536870911] "unitless"  IPMA_ADAS

BO_ 2610126918 OTAPhysSODCMDtoGWM_ECG: 64 IPMA_ADAS
 SG_ OTAPhysSODCMDtoGWM_ECG : 7|29@0+ (1,0) [0|536870911] "unitless"  GWM

BO_ 2610007256 OTAPhysGWM_ECGtoSODR: 64 GWM
 SG_ OTAPhysGWM_ECGtoSODR : 7|29@0+ (1,0) [0|536870911] "unitless"  IPMA_ADAS

BO_ 2610126947 OTAPhysSODRtoGWM_ECG: 64 IPMA_ADAS
 SG_ OTAPhysSODRtoGWM_ECG : 7|29@0+ (1,0) [0|536870911] "unitless"  GWM

BO_ 1238 IPMA_Data5: 16 IPMA_ADAS
 SG_ TjaCanclMsgTxt_D_Dsply : 31|4@0+ (1,0) [0|15] "SED"  GWM
 SG_ GfhbMnu_D_Rq : 19|2@0+ (1,0) [0|3] "SED"  GWM
 SG_ AhbcMnu_D_Rq : 21|2@0+ (1,0) [0|3] "SED"  GWM
 SG_ TjaLaneBias_D_Stat : 10|3@0+ (1,0) [0|7] "SED"  GWM
 SG_ TjaLaneBiasEnbl_D_Stat : 23|2@0+ (1,0) [0|3] "SED"  GWM
 SG_ IaccVAdjReas_D_Dsply : 15|5@0+ (1,0) [0|31] "SED"  GWM
 SG_ IaccVAdjLim_No_Actl : 7|8@0+ (1,0) [0|255] "unitless"  GWM

BO_ 2612073688 PARSEDPushFcGWMtoSODCMC: 8 GWM
 SG_ PARSEDPushFcECGtoSODCMC : 7|29@0+ (1,0) [0|536870911] "unitless"  IPMA_ADAS

BO_ 1072 Cluster_Info1_FD3: 8 GWM
 SG_ DrvSlipCtlMde_D_Rq : 33|2@0+ (1,0) [0|3] "SED" Vector__XXX
 SG_ EngIdlShutDown_B_RqDrv : 3|1@0+ (1,0) [0|1] "SED" Vector__XXX
 SG_ HsaMde_D_Rq : 54|2@0+ (1,0) [0|3] "SED" Vector__XXX
 SG_ NtrlTowMdeEnbl_B_RqDrv : 1|1@0+ (1,0) [0|1] "SED" Vector__XXX
 SG_ LscmbbStat_B_Actl : 2|1@0+ (1,0) [0|1] "SED" Vector__XXX
 SG_ BulbChkActv_B_Stat : 55|1@0+ (1,0) [0|1] "SED" Vector__XXX
 SG_ ParkDetect_Stat : 52|1@0+ (1,0) [0|1] "SED" Vector__XXX
 SG_ ReducedGuard_D_Rq : 51|2@0+ (1,0) [0|3] "SED" Vector__XXX
 SG_ TrlrBrkMde_D_Rq : 57|1@0+ (1,0) [0|1] "SED" Vector__XXX
 SG_ TRLR_SWAY_CONFIG_CMD : 56|1@0+ (1,0) [0|1] "SED" Vector__XXX
 SG_ TRAILER_BRAKE_CONFIG : 37|1@0+ (1,0) [0|1] "SED" Vector__XXX
 SG_ Power_Liftgate_Mode_Cmd : 39|1@0+ (1,0) [0|1] "SED" Vector__XXX
 SG_ AccEnbl_B_RqDrv : 35|1@0+ (1,0) [0|1] "SED"  IPMA_ADAS
 SG_ OdometerMasterValue : 15|24@0+ (1,0) [0|16777214] "km"  PSCM,IPMA_ADAS
 SG_ EngOilLife_B_RqReset : 43|1@0+ (1,0) [0|1] "SED" Vector__XXX
 SG_ MetricActvTe_B_Actl : 38|1@0+ (1,0) [0|1] "SED" Vector__XXX
 SG_ AccDeny_B_RqIpc : 7|1@0+ (1,0) [0|1] "SED"  IPMA_ADAS
 SG_ ePRNDL_MODE : 0|1@0+ (1,0) [0|1] "SED" Vector__XXX
 SG_ HaDsplyCpblty_B_Stat : 42|1@0+ (1,0) [0|1] "SED"  IPMA_ADAS
 SG_ DrvSlipCtlMde_B_Rq2 : 34|1@0+ (1,0) [0|1] "SED" Vector__XXX
 SG_ MetricActv_B_Actl : 6|1@0+ (1,0) [0|1] "SED"  IPMA_ADAS
 SG_ KeyTypeChngMykey_D_Rq : 41|2@0+ (1,0) [0|3] "SED" Vector__XXX
 SG_ ManRgen_D_Rq : 5|2@0+ (1,0) [0|3] "SED" Vector__XXX

BO_ 981 GlareFreeBeam: 8 IPMA_ADAS
 SG_ AdbRamping_T_Rq : 44|4@0+ (200,0) [0|3000] "millisecond"  GWM
 SG_ AdbBrdrTop_An_Rq : 7|8@0+ (0.04,-9.54) [-9.54|0.58] "degrees"  GWM
 SG_ AdbBrdrRight_L_Stat : 37|9@0+ (2,0) [0|1018] "meter"  GWM
 SG_ AdbBrdrRight_An_Rq : 31|10@0+ (0.04,-20.4) [-20.4|20.44] "degrees"  GWM
 SG_ AdbBrdrLeft_L_Stat : 40|9@0+ (2,0) [0|1018] "meter"  GWM
 SG_ AdbBrdrLeft_An_Rq : 9|10@0+ (0.04,-20.4) [-20.4|20.44] "degrees"  GWM
 SG_ AdbBrdrBottom_An_Rq : 15|6@0+ (0.04,-1.86) [-1.86|0.58] "degrees"  GWM
 SG_ AdbBeam_D_Rq : 63|3@0+ (1,0) [0|7] "SED"  GWM

BO_ 2610126946 OTAPhysSODLtoGWM_ECG: 64 IPMA_ADAS
 SG_ OTAPhysSODLtoGWM_ECG : 7|29@0+ (1,0) [0|536870911] "unitless"  GWM

BO_ 2610006232 OTAPhysGWM_ECGtoSODL: 64 GWM
 SG_ OTAPhysGWM_ECGtoSODL : 7|29@0+ (1,0) [0|536870911] "unitless"  IPMA_ADAS

BO_ 1985 TesterPhysicalReqCMR_DSMC: 64 TSTR
 SG_ TesterPhysicalReqCMR_DSMC : 7|64@0+ (1,0) [0|1.84467E+019] "unitless" Vector__XXX

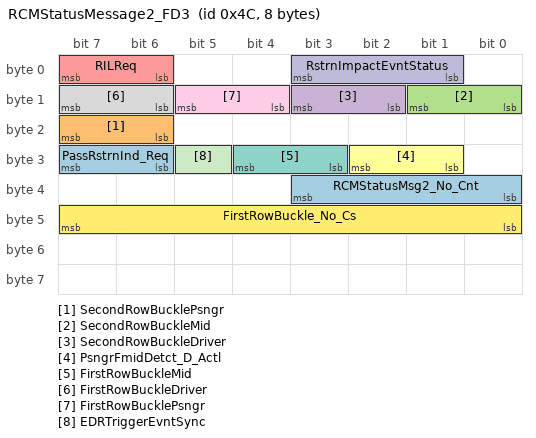
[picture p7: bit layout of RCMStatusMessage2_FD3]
BO_ 76 RCMStatusMessage2_FD3: 8 GWM
 SG_ PassRstrnInd_Req : 31|2@0+ (1,0) [0|3] "SED"  _delete
 SG_ SecondRowBucklePsngr : 23|2@0+ (1,0) [0|3] "SED"  _delete
 SG_ SecondRowBuckleMid : 9|2@0+ (1,0) [0|3] "SED"  _delete
 SG_ SecondRowBuckleDriver : 11|2@0+ (1,0) [0|3] "SED"  _delete
 SG_ RILReq : 7|2@0+ (1,0) [0|3] "SED"  _delete
 SG_ PsngrFmidDetct_D_Actl : 26|2@0+ (1,0) [0|3] "SED" Vector__XXX
 SG_ FirstRowBuckleMid : 28|2@0+ (1,0) [0|3] "SED"  IPMA_ADAS
 SG_ FirstRowBuckleDriver : 15|2@0+ (1,0) [0|3] "SED"  IPMA_ADAS
 SG_ FirstRowBucklePsngr : 13|2@0+ (1,0) [0|3] "SED"  IPMA_ADAS
 SG_ RstrnImpactEvntStatus : 3|3@0+ (1,0) [0|7] "SED"  SCCM,IPMA_ADAS
 SG_ EDRTriggerEvntSync : 29|1@0+ (1,0) [0|1] "SED"  IPMA_ADAS
 SG_ FirstRowBuckle_No_Cs : 47|8@0+ (1,0) [0|255] "unitless"  IPMA_ADAS
 SG_ RCMStatusMsg2_No_Cnt : 35|4@0+ (1,0) [0|15] "unitless"  IPMA_ADAS

BO_ 2609955032 OTAPhysGWM_ECGtoPSCM: 64 GWM
 SG_ OTAPhysGWM_ECGtoPSCM : 7|29@0+ (1,0) [0|536870911] "unitless" Vector__XXX

BO_ 2610126896 OTAPhysPSCMtoGWM_ECG: 64 Vector__XXX
 SG_ OTAPhysPSCMtoGWM_ECG : 7|29@0+ (1,0) [0|536870911] "unitless"  GWM

BO_ 2611003608 PARSEDPhysGWM_ECGtoPSCM: 64 GWM
 SG_ PARSEDPhysGWM_ECGtoPSCM : 7|29@0+ (1,0) [0|536870911] "unitless"  PSCM

BO_ 2611175472 PARSEDPhysPSCMtoGWM_ECG: 64 PSCM
 SG_ PARSEDPhysPSCMtoGWM_ECG : 7|29@0+ (1,0) [0|536870911] "unitless"  GWM

BO_ 2609939672 OTAPhysGWM_ECGtoIPMA: 64 GWM
 SG_ OTAPhysGWM_ECGtoIPMA : 7|29@0+ (1,0) [0|536870911] "unitless"  IPMA_ADAS

BO_ 2610126881 OTAPhysIPMAtoGWM_ECG: 64 IPMA_ADAS
 SG_ OTAPhysIPMAtoGWM_ECG : 7|29@0+ (1,0) [0|536870911] "unitless"  GWM

BO_ 1056 SelectDriveModeData_FD3: 16 GWM
 SG_ SelDrvMdeHmi03_D_Rq : 12|5@0+ (1,0) [0|31] "SED" Vector__XXX
 SG_ AutoEpbButtnOn_B_Stat : 48|1@0+ (1,0) [0|1] "SED" Vector__XXX
 SG_ AutoEpbMsgTxt_D_Rq : 58|3@0+ (1,0) [0|7] "SED" Vector__XXX
 SG_ SelDrvMdePos12_B_Avail : 54|1@0+ (1,0) [0|1] "SED" Vector__XXX
 SG_ SelDrvMdePos11_B_Avail : 55|1@0+ (1,0) [0|1] "SED" Vector__XXX
 SG_ SelDrvMdePos10_B_Avail : 40|1@0+ (1,0) [0|1] "SED" Vector__XXX
 SG_ SelDrvMdePos09_B_Avail : 41|1@0+ (1,0) [0|1] "SED" Vector__XXX
 SG_ SelDrvMdePos08_B_Avail : 42|1@0+ (1,0) [0|1] "SED" Vector__XXX
 SG_ SelDrvMdePos07_B_Avail : 43|1@0+ (1,0) [0|1] "SED" Vector__XXX
 SG_ SelDrvMdePos06_B_Avail : 44|1@0+ (1,0) [0|1] "SED" Vector__XXX
 SG_ SelDrvMdePos05_B_Avail : 45|1@0+ (1,0) [0|1] "SED" Vector__XXX
 SG_ SelDrvMdePos04_B_Avail : 46|1@0+ (1,0) [0|1] "SED" Vector__XXX
 SG_ SelDrvMdePos03_B_Avail : 47|1@0+ (1,0) [0|1] "SED" Vector__XXX
 SG_ SelDrvMdePos02_B_Avail : 32|1@0+ (1,0) [0|1] "SED" Vector__XXX
 SG_ SelDrvMdePos01_B_Avail : 24|1@0+ (1,0) [0|1] "SED" Vector__XXX
 SG_ ActvDrvMde_D2_Stat : 53|5@0+ (1,0) [0|31] "SED"  IPMA_ADAS
 SG_ SelDrvMde_D2_Rq : 63|5@0+ (1,0) [0|31] "SED" Vector__XXX
 SG_ SelDrvMdePt_D_Rq : 31|5@0+ (1,0) [0|31] "SED" Vector__XXX
 SG_ SelDrvMdeMsgTxt_D_Rq : 19|4@0+ (1,0) [0|15] "SED" Vector__XXX
 SG_ SelDrvMde_D_Stat : 26|2@0+ (1,0) [0|3] "SED" Vector__XXX
 SG_ AwdMde_D_RqBrk : 35|3@0+ (1,0) [0|7] "SED" Vector__XXX
 SG_ AutoEpbDsply_D_Stat : 37|2@0+ (1,0) [0|3] "SED" Vector__XXX

BO_ 1150 LocationServices_Data1_FD3: 8 GWM
 SG_ LocationServices_1 : 7|64@0+ (1,0) [0|1.84467440737096E+019] "unitless"  IPMA_ADAS

CM_ SG_ 954 GenericSwtch2_No_Actl "U625 Police Wig Wag feature";
CM_ BO_ 402 "FCDIM,APIM Tx";
CM_ SG_ 982 LatCtlPath_No_Cnt "Signal not transmitted on gas variants.";
CM_ SG_ 982 LatCtlPath_No_Cs "Signal not transmitted on gas variants.";
CM_ SG_ 1200 BrkTot_Tq_RqDrv "DCR 1836 to update Tx from GWM to EP100ms rejected due MPS6 TCM requires BrkTot_Tq_RqDrv at 20ms (bshu1).";
CM_ SG_ 1093 StopLamp_B_RqTrlrBrk "Signal not transmitted on all variants.";
CM_ SG_ 935 Side_Detect_R_Illum "DDMGenSigTimeoutTime=2000";
CM_ SG_ 935 SodRight_D_Stat "IPCGenSigTimeoutTime=1600";
CM_ SG_ 935 SodSnsRight_D_Stat "IPCGenSigTimeoutTime=1600";
CM_ SG_ 935 SodAlrtRight_D_Stat "DDMGenSigTimeoutTime=2000";
CM_ SG_ 1072 MetricActv_B_Actl "0 =Inactive(English), 1=Active(Metric)";
CM_ SG_ 1150 LocationServices_1 "Tx by HS3 APIM";
BA_DEF_ BO_  "VFrameFormat" ENUM  "StandardCAN","ExtendedCAN","reserved","reserved","reserved","reserved","reserved","reserved","reserved","reserved","reserved","reserved","reserved","reserved","StandardCAN_FD","ExtendedCAN_FD";
BA_DEF_ BO_  "FrameRouting" STRING ;
BA_DEF_ BO_  "NetworkInitialization" ENUM  "No","Yes";
BA_DEF_ BO_  "GenMsgStartDelayTime" INT 0 10000;
BA_DEF_ BO_  "GenMsgNrOfRepetition" INT 0 100;
BA_DEF_ BO_  "GenMsgDelayTime" INT 0 1000;
BA_DEF_ BO_  "GenMsgCycleTime" INT 0 100000;
BA_DEF_ BO_  "GenMsgSendType" ENUM  "FixedPeriodic","Event","EnabledPeriodic","NotUsed","NotUsed","EventPeriodic","NotUsed","NotUsed","NoMsgSendType";
BA_DEF_ SG_  "U_P702_MY2024_Tx" ENUM  "No","Yes";
BA_DEF_ SG_  "U_V710_MY2023_Tx" ENUM  "No","Yes";
BA_DEF_ SG_  "U_CDX74X_MY2024_Tx" ENUM  "No","Yes";
BA_DEF_ SG_  "U_P708_MY2023_Tx" ENUM  "No","Yes";
BA_DEF_ SG_  "U_V713AV_MY2022_Tx" ENUM  "No","Yes";
BA_DEF_ SG_  "U_V713N_MY2022_Tx" ENUM  "No","Yes";
BA_DEF_ SG_  "ECGUsedTxSignal" ENUM  "No","Yes";
BA_DEF_ SG_  "U_P702_MY2024_Rx" ENUM  "No","Yes";
BA_DEF_ SG_  "U_V710_MY2023_Rx" ENUM  "No","Yes";
BA_DEF_ SG_  "U_CDX74X_MY2024_Rx" ENUM  "No","Yes";
BA_DEF_ SG_  "U_CDX707_MY2023_Rx" ENUM  "No","Yes";
BA_DEF_ SG_  "U_P708_MY2023_Rx" ENUM  "No","Yes";
BA_DEF_ SG_  "U_V713N_MY2022_Rx" ENUM  "No","Yes";
BA_DEF_ SG_  "ECGUsedRxSignal" ENUM  "No","Yes";
BA_DEF_ SG_  "UsedOnPgmDBC" ENUM  "No","Yes";
BA_DEF_ SG_  "ContentDependant" ENUM  "No","Yes";
BA_DEF_ SG_  "GenSigStartValue" HEX 0 268435455;
BA_DEF_ SG_  "MetaData" ENUM  "No","Yes";
BA_DEF_ SG_  "WakeupSignal" ENUM  "No","Yes";
BA_DEF_ SG_  "GenSigInactiveValue" INT 0 100000;
BA_DEF_ SG_  "GenSigSendType" ENUM  "Cyclic","OnWrite","vector_leerstring","OnChange","vector_leerstring","IfActive","vector_leerstring","NoSigSendType";
BA_DEF_ BO_  "TpTxIndex" INT 0 536870911;
BA_DEF_ BO_  "OvtpPushApplication" ENUM  "FALSE","TRUE";
BA_DEF_ BO_  "SCP_FreshnessValueLength" INT 0 512;
BA_DEF_ BO_  "SCP_DataId" INT 0 17663;
BA_DEF_ BO_  "SCP_FreshnessValueTxLength" INT 0 512;
BA_DEF_ BO_  "SCP_AuthInfoTxLength" INT 0 512;
BA_DEF_ BO_  "SC_Message" ENUM  "No","Yes";
BA_DEF_ BO_  "GenMsgRoutingTimeoutTime" INT 0 5000;
BA_DEF_ BO_  "MessageGateway" ENUM  "No","Yes";
BA_DEF_ BO_  "NmAsrMessage" ENUM  "No","Yes";
BA_DEF_ BO_  "DiagState" ENUM  "No","Yes";
BA_DEF_ BO_  "DiagRequest" ENUM  "No","Yes";
BA_DEF_ BO_  "DiagResponse" ENUM  "No","Yes";
BA_DEF_ BO_  "GenMsgILSupport" ENUM  "No","Yes";
BA_DEF_REL_ BU_SG_REL_  "SC_Verification" ENUM  "No","Yes";
BA_DEF_DEF_  "VFrameFormat" "ExtendedCAN_FD";
BA_DEF_DEF_  "FrameRouting" "";
BA_DEF_DEF_  "NetworkInitialization" "Yes";
BA_DEF_DEF_  "GenMsgStartDelayTime" 0;
BA_DEF_DEF_  "GenMsgNrOfRepetition" 1;
BA_DEF_DEF_  "GenMsgDelayTime" 20;
BA_DEF_DEF_  "GenMsgCycleTime" 0;
BA_DEF_DEF_  "GenMsgSendType" "NoMsgSendType";
BA_DEF_DEF_  "U_P702_MY2024_Tx" "No";
BA_DEF_DEF_  "U_V710_MY2023_Tx" "No";
BA_DEF_DEF_  "U_CDX74X_MY2024_Tx" "No";
BA_DEF_DEF_  "U_P708_MY2023_Tx" "No";
BA_DEF_DEF_  "U_V713AV_MY2022_Tx" "No";
BA_DEF_DEF_  "U_V713N_MY2022_Tx" "No";
BA_DEF_DEF_  "ECGUsedTxSignal" "No";
BA_DEF_DEF_  "U_P702_MY2024_Rx" "No";
BA_DEF_DEF_  "U_V710_MY2023_Rx" "No";
BA_DEF_DEF_  "U_CDX74X_MY2024_Rx" "No";
BA_DEF_DEF_  "U_CDX707_MY2023_Rx" "No";
BA_DEF_DEF_  "U_P708_MY2023_Rx" "No";
BA_DEF_DEF_  "U_V713N_MY2022_Rx" "No";
BA_DEF_DEF_  "ECGUsedRxSignal" "No";
BA_DEF_DEF_  "UsedOnPgmDBC" "Yes";
BA_DEF_DEF_  "ContentDependant" "No";
BA_DEF_DEF_  "GenSigStartValue" 0;
BA_DEF_DEF_  "MetaData" "No";
BA_DEF_DEF_  "WakeupSignal" "No";
BA_DEF_DEF_  "GenSigInactiveValue" 0;
BA_DEF_DEF_  "GenSigSendType" "NoSigSendType";
BA_DEF_DEF_  "TpTxIndex" 0;
BA_DEF_DEF_  "OvtpPushApplication" "FALSE";
BA_DEF_DEF_  "SCP_FreshnessValueLength" 64;
BA_DEF_DEF_  "SCP_DataId" 0;
BA_DEF_DEF_  "SCP_FreshnessValueTxLength" 11;
BA_DEF_DEF_  "SCP_AuthInfoTxLength" 53;
BA_DEF_DEF_  "SC_Message" "No";
BA_DEF_DEF_  "GenMsgRoutingTimeoutTime" 0;
BA_DEF_DEF_  "MessageGateway" "No";
BA_DEF_DEF_  "NmAsrMessage" "No";
BA_DEF_DEF_  "DiagState" "No";
BA_DEF_DEF_  "DiagRequest" "No";
BA_DEF_DEF_  "DiagResponse" "No";
BA_DEF_DEF_  "GenMsgILSupport" "Yes";
BA_DEF_DEF_REL_ "SC_Verification" "No";
BA_ "GenMsgSendType" BO_ 1236 5;
BA_ "GenMsgCycleTime" BO_ 1236 1000;
BA_ "VFrameFormat" BO_ 1236 14;
BA_ "GenMsgSendType" BO_ 1235 5;
BA_ "GenMsgCycleTime" BO_ 1235 1000;
BA_ "VFrameFormat" BO_ 1235 14;
BA_ "GenMsgSendType" BO_ 1234 5;
BA_ "GenMsgCycleTime" BO_ 1234 200;
BA_ "VFrameFormat" BO_ 1234 14;
BA_ "GenMsgILSupport" BO_ 1436 0;
BA_ "NmAsrMessage" BO_ 1436 1;
BA_ "GenMsgSendType" BO_ 1436 0;
BA_ "GenMsgCycleTime" BO_ 1436 1000;
BA_ "NetworkInitialization" BO_ 1436 0;
BA_ "VFrameFormat" BO_ 1436 14;
BA_ "GenMsgSendType" BO_ 1233 5;
BA_ "GenMsgCycleTime" BO_ 1233 200;
BA_ "VFrameFormat" BO_ 1233 14;
BA_ "FrameRouting" BO_ 817 "FD1_CAN,0x331;";
BA_ "SCP_DataId" BO_ 817 9009;
BA_ "SC_Message" BO_ 817 1;
BA_ "VFrameFormat" BO_ 817 14;
BA_ "OvtpPushApplication" BO_ 2612194520 1;
BA_ "TpTxIndex" BO_ 2612194520 464710872;
BA_ "GenMsgSendType" BO_ 2612194520 1;
BA_ "GenMsgDelayTime" BO_ 2612194520 0;
BA_ "NetworkInitialization" BO_ 2612194520 0;
BA_ "TpTxIndex" BO_ 2611145944 463662296;
BA_ "GenMsgSendType" BO_ 2611145944 1;
BA_ "GenMsgDelayTime" BO_ 2611145944 0;
BA_ "NetworkInitialization" BO_ 2611145944 0;
BA_ "FrameRouting" BO_ 954 "FD1_CAN,0x3BA;";
BA_ "SCP_DataId" BO_ 954 17338;
BA_ "SC_Message" BO_ 954 1;
BA_ "VFrameFormat" BO_ 954 14;
BA_ "GenMsgILSupport" BO_ 1844 0;
BA_ "DiagRequest" BO_ 1844 1;
BA_ "GenMsgSendType" BO_ 1844 1;
BA_ "GenMsgDelayTime" BO_ 1844 0;
BA_ "NetworkInitialization" BO_ 1844 0;
BA_ "VFrameFormat" BO_ 1844 14;
BA_ "GenMsgILSupport" BO_ 1852 0;
BA_ "DiagResponse" BO_ 1852 1;
BA_ "GenMsgSendType" BO_ 1852 1;
BA_ "GenMsgDelayTime" BO_ 1852 0;
BA_ "NetworkInitialization" BO_ 1852 0;
BA_ "VFrameFormat" BO_ 1852 14;
BA_ "GenMsgSendType" BO_ 989 5;
BA_ "GenMsgCycleTime" BO_ 989 1000;
BA_ "VFrameFormat" BO_ 989 14;
BA_ "GenMsgSendType" BO_ 820 5;
BA_ "GenMsgCycleTime" BO_ 820 1000;
BA_ "SCP_DataId" BO_ 820 13108;
BA_ "SC_Message" BO_ 820 1;
BA_ "VFrameFormat" BO_ 820 14;
BA_ "FrameRouting" BO_ 402 "HS3_CAN,0x192;";
BA_ "VFrameFormat" BO_ 402 14;
BA_ "OvtpPushApplication" BO_ 2612170968 1;
BA_ "TpTxIndex" BO_ 2612170968 464687320;
BA_ "GenMsgSendType" BO_ 2612170968 1;
BA_ "GenMsgDelayTime" BO_ 2612170968 0;
BA_ "NetworkInitialization" BO_ 2612170968 0;
BA_ "OvtpPushApplication" BO_ 2612166872 1;
BA_ "TpTxIndex" BO_ 2612166872 464683224;
BA_ "GenMsgSendType" BO_ 2612166872 1;
BA_ "GenMsgDelayTime" BO_ 2612166872 0;
BA_ "NetworkInitialization" BO_ 2612166872 0;
BA_ "TpTxIndex" BO_ 2611122392 463638744;
BA_ "GenMsgSendType" BO_ 2611122392 1;
BA_ "GenMsgDelayTime" BO_ 2611122392 0;
BA_ "NetworkInitialization" BO_ 2611122392 0;
BA_ "TpTxIndex" BO_ 2611118296 463634648;
BA_ "GenMsgSendType" BO_ 2611118296 1;
BA_ "GenMsgDelayTime" BO_ 2611118296 0;
BA_ "NetworkInitialization" BO_ 2611118296 0;
BA_ "OvtpPushApplication" BO_ 2612224164 1;
BA_ "TpTxIndex" BO_ 2612224164 464687320;
BA_ "GenMsgSendType" BO_ 2612224164 1;
BA_ "GenMsgDelayTime" BO_ 2612224164 0;
BA_ "NetworkInitialization" BO_ 2612224164 0;
BA_ "OvtpPushApplication" BO_ 2612224160 1;
BA_ "TpTxIndex" BO_ 2612224160 464683224;
BA_ "GenMsgSendType" BO_ 2612224160 1;
BA_ "GenMsgDelayTime" BO_ 2612224160 0;
BA_ "NetworkInitialization" BO_ 2612224160 0;
BA_ "TpTxIndex" BO_ 2611175588 463638744;
BA_ "GenMsgSendType" BO_ 2611175588 1;
BA_ "GenMsgDelayTime" BO_ 2611175588 0;
BA_ "NetworkInitialization" BO_ 2611175588 0;
BA_ "TpTxIndex" BO_ 2611175584 463634648;
BA_ "GenMsgSendType" BO_ 2611175584 1;
BA_ "GenMsgDelayTime" BO_ 2611175584 0;
BA_ "NetworkInitialization" BO_ 2611175584 0;
BA_ "TpTxIndex" BO_ 2610073816 462590168;
BA_ "GenMsgSendType" BO_ 2610073816 1;
BA_ "GenMsgDelayTime" BO_ 2610073816 0;
BA_ "NetworkInitialization" BO_ 2610073816 0;
BA_ "TpTxIndex" BO_ 2610069720 462586072;
BA_ "GenMsgSendType" BO_ 2610069720 1;
BA_ "GenMsgDelayTime" BO_ 2610069720 0;
BA_ "NetworkInitialization" BO_ 2610069720 0;
BA_ "TpTxIndex" BO_ 2610127012 462590168;
BA_ "GenMsgSendType" BO_ 2610127012 1;
BA_ "GenMsgDelayTime" BO_ 2610127012 0;
BA_ "NetworkInitialization" BO_ 2610127012 0;
BA_ "TpTxIndex" BO_ 2610127008 462586072;
BA_ "GenMsgSendType" BO_ 2610127008 1;
BA_ "GenMsgDelayTime" BO_ 2610127008 0;
BA_ "NetworkInitialization" BO_ 2610127008 0;
BA_ "GenMsgILSupport" BO_ 1814 0;
BA_ "DiagRequest" BO_ 1814 1;
BA_ "GenMsgSendType" BO_ 1814 1;
BA_ "GenMsgDelayTime" BO_ 1814 0;
BA_ "NetworkInitialization" BO_ 1814 0;
BA_ "VFrameFormat" BO_ 1814 14;
BA_ "GenMsgSendType" BO_ 1113 0;
BA_ "GenMsgCycleTime" BO_ 1113 50;
BA_ "VFrameFormat" BO_ 1113 14;
BA_ "GenMsgSendType" BO_ 1047 5;
BA_ "GenMsgCycleTime" BO_ 1047 1000;
BA_ "VFrameFormat" BO_ 1047 14;
BA_ "GenMsgSendType" BO_ 1006 5;
BA_ "GenMsgCycleTime" BO_ 1006 1000;
BA_ "VFrameFormat" BO_ 1006 14;
BA_ "GenMsgSendType" BO_ 997 5;
BA_ "GenMsgCycleTime" BO_ 997 1000;
BA_ "VFrameFormat" BO_ 997 14;
BA_ "GenMsgSendType" BO_ 973 5;
BA_ "GenMsgCycleTime" BO_ 973 1000;
BA_ "VFrameFormat" BO_ 973 14;
BA_ "GenMsgSendType" BO_ 976 0;
BA_ "GenMsgCycleTime" BO_ 976 20;
BA_ "GenMsgDelayTime" BO_ 976 10;
BA_ "VFrameFormat" BO_ 976 14;
BA_ "FrameRouting" BO_ 837 "FD1_CAN,0x345;";
BA_ "VFrameFormat" BO_ 837 14;
BA_ "GenMsgSendType" BO_ 982 0;
BA_ "GenMsgCycleTime" BO_ 982 50;
BA_ "SCP_DataId" BO_ 982 5078;
BA_ "SC_Message" BO_ 982 1;
BA_ "VFrameFormat" BO_ 982 14;
BA_ "TpTxIndex" BO_ 2611070168 463586520;
BA_ "GenMsgSendType" BO_ 2611070168 1;
BA_ "GenMsgDelayTime" BO_ 2611070168 0;
BA_ "NetworkInitialization" BO_ 2611070168 0;
BA_ "TpTxIndex" BO_ 2611175537 463586520;
BA_ "GenMsgSendType" BO_ 2611175537 1;
BA_ "GenMsgDelayTime" BO_ 2611175537 0;
BA_ "NetworkInitialization" BO_ 2611175537 0;
BA_ "TpTxIndex" BO_ 2610021592 462537944;
BA_ "GenMsgSendType" BO_ 2610021592 1;
BA_ "GenMsgDelayTime" BO_ 2610021592 0;
BA_ "NetworkInitialization" BO_ 2610021592 0;
BA_ "TpTxIndex" BO_ 2610126961 462537944;
BA_ "GenMsgSendType" BO_ 2610126961 1;
BA_ "GenMsgDelayTime" BO_ 2610126961 0;
BA_ "NetworkInitialization" BO_ 2610126961 0;
BA_ "TpTxIndex" BO_ 2610975960 463492312;
BA_ "GenMsgSendType" BO_ 2610975960 1;
BA_ "GenMsgDelayTime" BO_ 2610975960 0;
BA_ "NetworkInitialization" BO_ 2610975960 0;
BA_ "TpTxIndex" BO_ 2611175445 463492312;
BA_ "GenMsgSendType" BO_ 2611175445 1;
BA_ "GenMsgDelayTime" BO_ 2611175445 0;
BA_ "NetworkInitialization" BO_ 2611175445 0;
BA_ "OvtpPushApplication" BO_ 2612224021 1;
BA_ "TpTxIndex" BO_ 2612224021 464540888;
BA_ "GenMsgSendType" BO_ 2612224021 1;
BA_ "GenMsgDelayTime" BO_ 2612224021 0;
BA_ "NetworkInitialization" BO_ 2612224021 0;
BA_ "TpTxIndex" BO_ 2611025112 463541464;
BA_ "GenMsgSendType" BO_ 2611025112 1;
BA_ "GenMsgDelayTime" BO_ 2611025112 0;
BA_ "NetworkInitialization" BO_ 2611025112 0;
BA_ "TpTxIndex" BO_ 2611175493 463541464;
BA_ "GenMsgSendType" BO_ 2611175493 1;
BA_ "GenMsgDelayTime" BO_ 2611175493 0;
BA_ "NetworkInitialization" BO_ 2611175493 0;
BA_ "OvtpPushApplication" BO_ 2612024536 1;
BA_ "TpTxIndex" BO_ 2612024536 464540888;
BA_ "GenMsgSendType" BO_ 2612024536 1;
BA_ "GenMsgDelayTime" BO_ 2612024536 0;
BA_ "NetworkInitialization" BO_ 2612024536 0;
BA_ "GenMsgDelayTime" BO_ 1200 10;
BA_ "FrameRouting" BO_ 1200 "FD1_CAN,0x4B0;";
BA_ "SCP_DataId" BO_ 1200 5296;
BA_ "SC_Message" BO_ 1200 1;
BA_ "VFrameFormat" BO_ 1200 14;
BA_ "FrameRouting" BO_ 1093 "HS3_CAN,0x445;";
BA_ "VFrameFormat" BO_ 1093 14;
BA_ "GenMsgILSupport" BO_ 1787 0;
BA_ "DiagResponse" BO_ 1787 1;
BA_ "GenMsgSendType" BO_ 1787 1;
BA_ "GenMsgDelayTime" BO_ 1787 0;
BA_ "NetworkInitialization" BO_ 1787 0;
BA_ "VFrameFormat" BO_ 1787 14;
BA_ "GenMsgILSupport" BO_ 1779 0;
BA_ "DiagRequest" BO_ 1779 1;
BA_ "GenMsgSendType" BO_ 1779 1;
BA_ "GenMsgDelayTime" BO_ 1779 0;
BA_ "NetworkInitialization" BO_ 1779 0;
BA_ "VFrameFormat" BO_ 1779 14;
BA_ "GenMsgILSupport" BO_ 1786 0;
BA_ "DiagResponse" BO_ 1786 1;
BA_ "GenMsgSendType" BO_ 1786 1;
BA_ "GenMsgDelayTime" BO_ 1786 0;
BA_ "NetworkInitialization" BO_ 1786 0;
BA_ "VFrameFormat" BO_ 1786 14;
BA_ "GenMsgSendType" BO_ 935 5;
BA_ "GenMsgCycleTime" BO_ 935 200;
BA_ "SCP_DataId" BO_ 935 5031;
BA_ "SC_Message" BO_ 935 1;
BA_ "VFrameFormat" BO_ 935 14;
BA_ "FrameRouting" BO_ 1087 "FD1_CAN,0x43F;";
BA_ "SCP_DataId" BO_ 1087 5183;
BA_ "SC_Message" BO_ 1087 1;
BA_ "VFrameFormat" BO_ 1087 14;
BA_ "FrameRouting" BO_ 1076 "HS3_CAN,0x434;";
BA_ "VFrameFormat" BO_ 1076 14;
BA_ "TpTxIndex" BO_ 2611026136 463542488;
BA_ "GenMsgSendType" BO_ 2611026136 1;
BA_ "GenMsgDelayTime" BO_ 2611026136 0;
BA_ "NetworkInitialization" BO_ 2611026136 0;
BA_ "TpTxIndex" BO_ 2611175494 463542488;
BA_ "GenMsgSendType" BO_ 2611175494 1;
BA_ "GenMsgDelayTime" BO_ 2611175494 0;
BA_ "NetworkInitialization" BO_ 2611175494 0;
BA_ "TpTxIndex" BO_ 2611054808 463571160;
BA_ "GenMsgSendType" BO_ 2611054808 1;
BA_ "GenMsgDelayTime" BO_ 2611054808 0;
BA_ "NetworkInitialization" BO_ 2611054808 0;
BA_ "TpTxIndex" BO_ 2611175523 463572184;
BA_ "GenMsgSendType" BO_ 2611175523 1;
BA_ "GenMsgDelayTime" BO_ 2611175523 0;
BA_ "NetworkInitialization" BO_ 2611175523 0;
BA_ "TpTxIndex" BO_ 2611055832 463572184;
BA_ "GenMsgSendType" BO_ 2611055832 1;
BA_ "GenMsgDelayTime" BO_ 2611055832 0;
BA_ "NetworkInitialization" BO_ 2611055832 0;
BA_ "TpTxIndex" BO_ 2611175522 463571160;
BA_ "GenMsgSendType" BO_ 2611175522 1;
BA_ "GenMsgDelayTime" BO_ 2611175522 0;
BA_ "NetworkInitialization" BO_ 2611175522 0;
BA_ "TpTxIndex" BO_ 2609927384 462443736;
BA_ "GenMsgSendType" BO_ 2609927384 1;
BA_ "GenMsgDelayTime" BO_ 2609927384 0;
BA_ "NetworkInitialization" BO_ 2609927384 0;
BA_ "TpTxIndex" BO_ 2610126869 462443736;
BA_ "GenMsgSendType" BO_ 2610126869 1;
BA_ "GenMsgDelayTime" BO_ 2610126869 0;
BA_ "NetworkInitialization" BO_ 2610126869 0;
BA_ "TpTxIndex" BO_ 2609976536 462492888;
BA_ "GenMsgSendType" BO_ 2609976536 1;
BA_ "GenMsgDelayTime" BO_ 2609976536 0;
BA_ "NetworkInitialization" BO_ 2609976536 0;
BA_ "TpTxIndex" BO_ 2610126917 462492888;
BA_ "GenMsgSendType" BO_ 2610126917 1;
BA_ "GenMsgDelayTime" BO_ 2610126917 0;
BA_ "NetworkInitialization" BO_ 2610126917 0;
BA_ "TpTxIndex" BO_ 2609977560 462493912;
BA_ "GenMsgSendType" BO_ 2609977560 1;
BA_ "GenMsgDelayTime" BO_ 2609977560 0;
BA_ "NetworkInitialization" BO_ 2609977560 0;
BA_ "TpTxIndex" BO_ 2610126918 462493912;
BA_ "GenMsgSendType" BO_ 2610126918 1;
BA_ "GenMsgDelayTime" BO_ 2610126918 0;
BA_ "NetworkInitialization" BO_ 2610126918 0;
BA_ "TpTxIndex" BO_ 2610007256 462523608;
BA_ "GenMsgSendType" BO_ 2610007256 1;
BA_ "GenMsgDelayTime" BO_ 2610007256 0;
BA_ "NetworkInitialization" BO_ 2610007256 0;
BA_ "TpTxIndex" BO_ 2610126947 462523608;
BA_ "GenMsgSendType" BO_ 2610126947 1;
BA_ "GenMsgDelayTime" BO_ 2610126947 0;
BA_ "NetworkInitialization" BO_ 2610126947 0;
BA_ "GenMsgSendType" BO_ 1238 5;
BA_ "GenMsgCycleTime" BO_ 1238 1000;
BA_ "SCP_DataId" BO_ 1238 13526;
BA_ "SC_Message" BO_ 1238 1;
BA_ "VFrameFormat" BO_ 1238 14;
BA_ "OvtpPushApplication" BO_ 2612073688 1;
BA_ "TpTxIndex" BO_ 2612073688 464590040;
BA_ "GenMsgSendType" BO_ 2612073688 1;
BA_ "GenMsgDelayTime" BO_ 2612073688 0;
BA_ "NetworkInitialization" BO_ 2612073688 0;
BA_ "FrameRouting" BO_ 1072 "HS3_CAN,0x430;";
BA_ "VFrameFormat" BO_ 1072 14;
BA_ "GenMsgSendType" BO_ 981 0;
BA_ "GenMsgCycleTime" BO_ 981 20;
BA_ "GenMsgDelayTime" BO_ 981 10;
BA_ "VFrameFormat" BO_ 981 14;
BA_ "TpTxIndex" BO_ 2610126946 462522584;
BA_ "GenMsgSendType" BO_ 2610126946 1;
BA_ "GenMsgDelayTime" BO_ 2610126946 0;
BA_ "NetworkInitialization" BO_ 2610126946 0;
BA_ "TpTxIndex" BO_ 2610006232 462522584;
BA_ "GenMsgSendType" BO_ 2610006232 1;
BA_ "GenMsgDelayTime" BO_ 2610006232 0;
BA_ "NetworkInitialization" BO_ 2610006232 0;
BA_ "GenMsgILSupport" BO_ 1985 0;
BA_ "DiagRequest" BO_ 1985 1;
BA_ "GenMsgSendType" BO_ 1985 1;
BA_ "GenMsgDelayTime" BO_ 1985 0;
BA_ "NetworkInitialization" BO_ 1985 0;
BA_ "VFrameFormat" BO_ 1985 14;
BA_ "FrameRouting" BO_ 76 "HS2_CAN,0x4C;";
BA_ "VFrameFormat" BO_ 76 14;
BA_ "TpTxIndex" BO_ 2609955032 462471384;
BA_ "GenMsgSendType" BO_ 2609955032 1;
BA_ "GenMsgDelayTime" BO_ 2609955032 0;
BA_ "NetworkInitialization" BO_ 2609955032 0;
BA_ "TpTxIndex" BO_ 2610126896 462471384;
BA_ "GenMsgSendType" BO_ 2610126896 1;
BA_ "GenMsgDelayTime" BO_ 2610126896 0;
BA_ "NetworkInitialization" BO_ 2610126896 0;
BA_ "TpTxIndex" BO_ 2611003608 463519960;
BA_ "GenMsgSendType" BO_ 2611003608 1;
BA_ "GenMsgDelayTime" BO_ 2611003608 0;
BA_ "NetworkInitialization" BO_ 2611003608 0;
BA_ "TpTxIndex" BO_ 2611175472 463519960;
BA_ "GenMsgSendType" BO_ 2611175472 1;
BA_ "GenMsgDelayTime" BO_ 2611175472 0;
BA_ "NetworkInitialization" BO_ 2611175472 0;
BA_ "TpTxIndex" BO_ 2609939672 462456024;
BA_ "GenMsgSendType" BO_ 2609939672 1;
BA_ "GenMsgDelayTime" BO_ 2609939672 0;
BA_ "NetworkInitialization" BO_ 2609939672 0;
BA_ "TpTxIndex" BO_ 2610126881 462456024;
BA_ "GenMsgSendType" BO_ 2610126881 1;
BA_ "GenMsgDelayTime" BO_ 2610126881 0;
BA_ "NetworkInitialization" BO_ 2610126881 0;
BA_ "FrameRouting" BO_ 1056 "FD1_CAN,0x420;";
BA_ "SCP_DataId" BO_ 1056 5152;
BA_ "SC_Message" BO_ 1056 1;
BA_ "VFrameFormat" BO_ 1056 14;
BA_ "FrameRouting" BO_ 1150 "HS3_CAN,0x45E;";
BA_ "VFrameFormat" BO_ 1150 14;
BA_ "U_P708_MY2023_Tx" SG_ 1236 ApaSlotRearX_L_Actl 1;
BA_ "U_V710_MY2023_Tx" SG_ 1236 ApaSlotRearX_L_Actl 1;
BA_ "U_P702_MY2024_Tx" SG_ 1236 ApaSlotRearX_L_Actl 1;
BA_ "GenSigSendType" SG_ 1236 ApaSlotRight3X_L_Actl 3;
BA_ "U_P708_MY2023_Tx" SG_ 1236 ApaSlotRight3X_L_Actl 1;
BA_ "U_V710_MY2023_Tx" SG_ 1236 ApaSlotRight3X_L_Actl 1;
BA_ "U_P702_MY2024_Tx" SG_ 1236 ApaSlotRight3X_L_Actl 1;
BA_ "GenSigSendType" SG_ 1236 ApaSlotRight3_D_Stat 3;
BA_ "U_P708_MY2023_Tx" SG_ 1236 ApaSlotRight3_D_Stat 1;
BA_ "U_V710_MY2023_Tx" SG_ 1236 ApaSlotRight3_D_Stat 1;
BA_ "U_P702_MY2024_Tx" SG_ 1236 ApaSlotRight3_D_Stat 1;
BA_ "GenSigSendType" SG_ 1236 ApaSlotRight3_B_Altr 3;
BA_ "U_P708_MY2023_Tx" SG_ 1236 ApaSlotRight3_B_Altr 1;
BA_ "U_V710_MY2023_Tx" SG_ 1236 ApaSlotRight3_B_Altr 1;
BA_ "U_P702_MY2024_Tx" SG_ 1236 ApaSlotRight3_B_Altr 1;
BA_ "GenSigSendType" SG_ 1236 ApaSlotRight2X_L_Actl 3;
BA_ "U_P708_MY2023_Tx" SG_ 1236 ApaSlotRight2X_L_Actl 1;
BA_ "U_V710_MY2023_Tx" SG_ 1236 ApaSlotRight2X_L_Actl 1;
BA_ "U_P702_MY2024_Tx" SG_ 1236 ApaSlotRight2X_L_Actl 1;
BA_ "GenSigSendType" SG_ 1236 ApaSlotRight2_D_Stat 3;
BA_ "U_P708_MY2023_Tx" SG_ 1236 ApaSlotRight2_D_Stat 1;
BA_ "U_V710_MY2023_Tx" SG_ 1236 ApaSlotRight2_D_Stat 1;
BA_ "U_P702_MY2024_Tx" SG_ 1236 ApaSlotRight2_D_Stat 1;
BA_ "GenSigSendType" SG_ 1236 ApaSlotRight2_B_Altr 3;
BA_ "U_P708_MY2023_Tx" SG_ 1236 ApaSlotRight2_B_Altr 1;
BA_ "U_V710_MY2023_Tx" SG_ 1236 ApaSlotRight2_B_Altr 1;
BA_ "U_P702_MY2024_Tx" SG_ 1236 ApaSlotRight2_B_Altr 1;
BA_ "GenSigSendType" SG_ 1236 ApaSlotRight1X_L_Actl 3;
BA_ "U_P708_MY2023_Tx" SG_ 1236 ApaSlotRight1X_L_Actl 1;
BA_ "U_V710_MY2023_Tx" SG_ 1236 ApaSlotRight1X_L_Actl 1;
BA_ "U_P702_MY2024_Tx" SG_ 1236 ApaSlotRight1X_L_Actl 1;
BA_ "GenSigSendType" SG_ 1236 ApaSlotRight1_D_Stat 3;
BA_ "U_P708_MY2023_Tx" SG_ 1236 ApaSlotRight1_D_Stat 1;
BA_ "U_V710_MY2023_Tx" SG_ 1236 ApaSlotRight1_D_Stat 1;
BA_ "U_P702_MY2024_Tx" SG_ 1236 ApaSlotRight1_D_Stat 1;
BA_ "GenSigSendType" SG_ 1236 ApaSlotRight1_B_Altr 3;
BA_ "U_P708_MY2023_Tx" SG_ 1236 ApaSlotRight1_B_Altr 1;
BA_ "U_V710_MY2023_Tx" SG_ 1236 ApaSlotRight1_B_Altr 1;
BA_ "U_P702_MY2024_Tx" SG_ 1236 ApaSlotRight1_B_Altr 1;
BA_ "GenSigStartValue" SG_ 1236 ApaSlotRearY_L_Actl 32;
BA_ "U_P708_MY2023_Tx" SG_ 1236 ApaSlotRearY_L_Actl 1;
BA_ "U_V710_MY2023_Tx" SG_ 1236 ApaSlotRearY_L_Actl 1;
BA_ "U_P702_MY2024_Tx" SG_ 1236 ApaSlotRearY_L_Actl 1;
BA_ "U_P708_MY2023_Tx" SG_ 1236 ApaSlotRear_D_Stat 1;
BA_ "U_V710_MY2023_Tx" SG_ 1236 ApaSlotRear_D_Stat 1;
BA_ "U_P702_MY2024_Tx" SG_ 1236 ApaSlotRear_D_Stat 1;
BA_ "GenSigSendType" SG_ 1235 ApaSlotFront_D_Stat 3;
BA_ "U_P708_MY2023_Tx" SG_ 1235 ApaSlotFront_D_Stat 1;
BA_ "U_V710_MY2023_Tx" SG_ 1235 ApaSlotFront_D_Stat 1;
BA_ "U_P702_MY2024_Tx" SG_ 1235 ApaSlotFront_D_Stat 1;
BA_ "U_P708_MY2023_Tx" SG_ 1235 ApaSlotFrontX_L_Actl 1;
BA_ "U_V710_MY2023_Tx" SG_ 1235 ApaSlotFrontX_L_Actl 1;
BA_ "U_P702_MY2024_Tx" SG_ 1235 ApaSlotFrontX_L_Actl 1;
BA_ "GenSigStartValue" SG_ 1235 ApaSlotFrontY_L_Actl 32;
BA_ "U_P708_MY2023_Tx" SG_ 1235 ApaSlotFrontY_L_Actl 1;
BA_ "U_V710_MY2023_Tx" SG_ 1235 ApaSlotFrontY_L_Actl 1;
BA_ "U_P702_MY2024_Tx" SG_ 1235 ApaSlotFrontY_L_Actl 1;
BA_ "GenSigSendType" SG_ 1235 ApaSlotLeft3X_L_Actl 3;
BA_ "U_P708_MY2023_Tx" SG_ 1235 ApaSlotLeft3X_L_Actl 1;
BA_ "U_V710_MY2023_Tx" SG_ 1235 ApaSlotLeft3X_L_Actl 1;
BA_ "U_P702_MY2024_Tx" SG_ 1235 ApaSlotLeft3X_L_Actl 1;
BA_ "GenSigSendType" SG_ 1235 ApaSlotLeft3_D_Stat 3;
BA_ "U_P708_MY2023_Tx" SG_ 1235 ApaSlotLeft3_D_Stat 1;
BA_ "U_V710_MY2023_Tx" SG_ 1235 ApaSlotLeft3_D_Stat 1;
BA_ "U_P702_MY2024_Tx" SG_ 1235 ApaSlotLeft3_D_Stat 1;
BA_ "GenSigSendType" SG_ 1235 ApaSlotLeft3_B_Altr 3;
BA_ "U_P708_MY2023_Tx" SG_ 1235 ApaSlotLeft3_B_Altr 1;
BA_ "U_V710_MY2023_Tx" SG_ 1235 ApaSlotLeft3_B_Altr 1;
BA_ "U_P702_MY2024_Tx" SG_ 1235 ApaSlotLeft3_B_Altr 1;
BA_ "GenSigSendType" SG_ 1235 ApaSlotLeft2X_L_Actl 3;
BA_ "U_P708_MY2023_Tx" SG_ 1235 ApaSlotLeft2X_L_Actl 1;
BA_ "U_V710_MY2023_Tx" SG_ 1235 ApaSlotLeft2X_L_Actl 1;
BA_ "U_P702_MY2024_Tx" SG_ 1235 ApaSlotLeft2X_L_Actl 1;
BA_ "GenSigSendType" SG_ 1235 ApaSlotLeft2_D_Stat 3;
BA_ "U_P708_MY2023_Tx" SG_ 1235 ApaSlotLeft2_D_Stat 1;
BA_ "U_V710_MY2023_Tx" SG_ 1235 ApaSlotLeft2_D_Stat 1;
BA_ "U_P702_MY2024_Tx" SG_ 1235 ApaSlotLeft2_D_Stat 1;
BA_ "GenSigSendType" SG_ 1235 ApaSlotLeft2_B_Altr 3;
BA_ "U_P708_MY2023_Tx" SG_ 1235 ApaSlotLeft2_B_Altr 1;
BA_ "U_V710_MY2023_Tx" SG_ 1235 ApaSlotLeft2_B_Altr 1;
BA_ "U_P702_MY2024_Tx" SG_ 1235 ApaSlotLeft2_B_Altr 1;
BA_ "GenSigSendType" SG_ 1235 ApaSlotLeft1X_L_Actl 3;
BA_ "U_P708_MY2023_Tx" SG_ 1235 ApaSlotLeft1X_L_Actl 1;
BA_ "U_V710_MY2023_Tx" SG_ 1235 ApaSlotLeft1X_L_Actl 1;
BA_ "U_P702_MY2024_Tx" SG_ 1235 ApaSlotLeft1X_L_Actl 1;
BA_ "GenSigSendType" SG_ 1235 ApaSlotLeft1_D_Stat 3;
BA_ "U_P708_MY2023_Tx" SG_ 1235 ApaSlotLeft1_D_Stat 1;
BA_ "U_V710_MY2023_Tx" SG_ 1235 ApaSlotLeft1_D_Stat 1;
BA_ "U_P702_MY2024_Tx" SG_ 1235 ApaSlotLeft1_D_Stat 1;
BA_ "GenSigSendType" SG_ 1235 ApaSlotLeft1_B_Altr 3;
BA_ "U_P708_MY2023_Tx" SG_ 1235 ApaSlotLeft1_B_Altr 1;
BA_ "U_V710_MY2023_Tx" SG_ 1235 ApaSlotLeft1_B_Altr 1;
BA_ "U_P702_MY2024_Tx" SG_ 1235 ApaSlotLeft1_B_Altr 1;
BA_ "GenSigStartValue" SG_ 1234 RmtCtlConfgSrc_D_Stat 1;
BA_ "GenSigSendType" SG_ 1234 RmtCtlConfgSrc_D_Stat 3;
BA_ "U_P708_MY2023_Tx" SG_ 1234 RmtCtlConfgSrc_D_Stat 1;
BA_ "U_V710_MY2023_Tx" SG_ 1234 RmtCtlConfgSrc_D_Stat 1;
BA_ "U_P702_MY2024_Tx" SG_ 1234 RmtCtlConfgSrc_D_Stat 1;
BA_ "GenSigSendType" SG_ 1234 RmtCtlTrjctry_D_Avail 3;
BA_ "U_P708_MY2023_Tx" SG_ 1234 RmtCtlTrjctry_D_Avail 1;
BA_ "U_V710_MY2023_Tx" SG_ 1234 RmtCtlTrjctry_D_Avail 1;
BA_ "U_P702_MY2024_Tx" SG_ 1234 RmtCtlTrjctry_D_Avail 1;
BA_ "GenSigSendType" SG_ 1234 RmtCtlSns_D_Err 3;
BA_ "U_P708_MY2023_Tx" SG_ 1234 RmtCtlSns_D_Err 1;
BA_ "U_V710_MY2023_Tx" SG_ 1234 RmtCtlSns_D_Err 1;
BA_ "U_P702_MY2024_Tx" SG_ 1234 RmtCtlSns_D_Err 1;
BA_ "GenSigSendType" SG_ 1234 RmtCtlPathPlan_D_Stat 3;
BA_ "U_P708_MY2023_Tx" SG_ 1234 RmtCtlPathPlan_D_Stat 1;
BA_ "U_V710_MY2023_Tx" SG_ 1234 RmtCtlPathPlan_D_Stat 1;
BA_ "U_P702_MY2024_Tx" SG_ 1234 RmtCtlPathPlan_D_Stat 1;
BA_ "GenSigSendType" SG_ 1234 RmtCtlPathPlan_B_Err 3;
BA_ "U_P708_MY2023_Tx" SG_ 1234 RmtCtlPathPlan_B_Err 1;
BA_ "U_V710_MY2023_Tx" SG_ 1234 RmtCtlPathPlan_B_Err 1;
BA_ "U_P702_MY2024_Tx" SG_ 1234 RmtCtlPathPlan_B_Err 1;
BA_ "GenSigSendType" SG_ 1234 RmtCtlAdas_D_Stat 3;
BA_ "U_P708_MY2023_Tx" SG_ 1234 RmtCtlAdas_D_Stat 1;
BA_ "U_V710_MY2023_Tx" SG_ 1234 RmtCtlAdas_D_Stat 1;
BA_ "U_P702_MY2024_Tx" SG_ 1234 RmtCtlAdas_D_Stat 1;
BA_ "GenSigSendType" SG_ 1234 RmtCtlAdas_B_Err 3;
BA_ "U_P708_MY2023_Tx" SG_ 1234 RmtCtlAdas_B_Err 1;
BA_ "U_V710_MY2023_Tx" SG_ 1234 RmtCtlAdas_B_Err 1;
BA_ "U_P702_MY2024_Tx" SG_ 1234 RmtCtlAdas_B_Err 1;
BA_ "GenSigSendType" SG_ 1234 RmtCtlSnsBlckg_B_Stat 3;
BA_ "U_P708_MY2023_Tx" SG_ 1234 RmtCtlSnsBlckg_B_Stat 1;
BA_ "U_V710_MY2023_Tx" SG_ 1234 RmtCtlSnsBlckg_B_Stat 1;
BA_ "U_P702_MY2024_Tx" SG_ 1234 RmtCtlSnsBlckg_B_Stat 1;
BA_ "GenSigStartValue" SG_ 1436 IPMA_GWOnBoardTester 255;
BA_ "U_P708_MY2023_Tx" SG_ 1436 IPMA_GWOnBoardTester 1;
BA_ "U_V710_MY2023_Tx" SG_ 1436 IPMA_GWOnBoardTester 1;
BA_ "U_P702_MY2024_Tx" SG_ 1436 IPMA_GWOnBoardTester 1;
BA_ "GenSigStartValue" SG_ 1436 IPMA_GWNMProxy 255;
BA_ "U_P708_MY2023_Tx" SG_ 1436 IPMA_GWNMProxy 1;
BA_ "U_V710_MY2023_Tx" SG_ 1436 IPMA_GWNMProxy 1;
BA_ "U_P702_MY2024_Tx" SG_ 1436 IPMA_GWNMProxy 1;
BA_ "GenSigStartValue" SG_ 1436 IPMA_AutoSarNMReserved4 255;
BA_ "U_P708_MY2023_Tx" SG_ 1436 IPMA_AutoSarNMReserved4 1;
BA_ "U_V710_MY2023_Tx" SG_ 1436 IPMA_AutoSarNMReserved4 1;
BA_ "U_P702_MY2024_Tx" SG_ 1436 IPMA_AutoSarNMReserved4 1;
BA_ "GenSigStartValue" SG_ 1436 IPMA_AutoSarNMReserved3 255;
BA_ "U_P708_MY2023_Tx" SG_ 1436 IPMA_AutoSarNMReserved3 1;
BA_ "U_V710_MY2023_Tx" SG_ 1436 IPMA_AutoSarNMReserved3 1;
BA_ "U_P702_MY2024_Tx" SG_ 1436 IPMA_AutoSarNMReserved3 1;
BA_ "GenSigStartValue" SG_ 1436 IPMA_AutoSarNMReserved2 255;
BA_ "U_P708_MY2023_Tx" SG_ 1436 IPMA_AutoSarNMReserved2 1;
BA_ "U_V710_MY2023_Tx" SG_ 1436 IPMA_AutoSarNMReserved2 1;
BA_ "U_P702_MY2024_Tx" SG_ 1436 IPMA_AutoSarNMReserved2 1;
BA_ "GenSigStartValue" SG_ 1436 IPMA_AutoSarNMReserved1 255;
BA_ "U_P708_MY2023_Tx" SG_ 1436 IPMA_AutoSarNMReserved1 1;
BA_ "U_V710_MY2023_Tx" SG_ 1436 IPMA_AutoSarNMReserved1 1;
BA_ "U_P702_MY2024_Tx" SG_ 1436 IPMA_AutoSarNMReserved1 1;
BA_ "GenSigStartValue" SG_ 1436 IPMA_AutoSarNMNodeId 156;
BA_ "U_P708_MY2023_Tx" SG_ 1436 IPMA_AutoSarNMNodeId 1;
BA_ "U_V710_MY2023_Tx" SG_ 1436 IPMA_AutoSarNMNodeId 1;
BA_ "U_P702_MY2024_Tx" SG_ 1436 IPMA_AutoSarNMNodeId 1;
BA_ "U_P708_MY2023_Tx" SG_ 1436 IPMA_AutoSarNMControl 1;
BA_ "U_V710_MY2023_Tx" SG_ 1436 IPMA_AutoSarNMControl 1;
BA_ "U_P702_MY2024_Tx" SG_ 1436 IPMA_AutoSarNMControl 1;
BA_ "GenSigSendType" SG_ 1233 FreeDrvRear_D_Avail 3;
BA_ "U_P708_MY2023_Tx" SG_ 1233 FreeDrvRear_D_Avail 1;
BA_ "U_V710_MY2023_Tx" SG_ 1233 FreeDrvRear_D_Avail 1;
BA_ "U_P702_MY2024_Tx" SG_ 1233 FreeDrvRear_D_Avail 1;
BA_ "GenSigSendType" SG_ 1233 FreeDrvFwd_D_Avail 3;
BA_ "U_P708_MY2023_Tx" SG_ 1233 FreeDrvFwd_D_Avail 1;
BA_ "U_V710_MY2023_Tx" SG_ 1233 FreeDrvFwd_D_Avail 1;
BA_ "U_P702_MY2024_Tx" SG_ 1233 FreeDrvFwd_D_Avail 1;
BA_ "GenSigSendType" SG_ 1233 RmtCtlTrgDist_D_Stat 3;
BA_ "U_P708_MY2023_Tx" SG_ 1233 RmtCtlTrgDist_D_Stat 1;
BA_ "U_V710_MY2023_Tx" SG_ 1233 RmtCtlTrgDist_D_Stat 1;
BA_ "U_P702_MY2024_Tx" SG_ 1233 RmtCtlTrgDist_D_Stat 1;
BA_ "GenSigSendType" SG_ 1233 RmtCtlSnsRrCrnr_D_Stat 3;
BA_ "U_P708_MY2023_Tx" SG_ 1233 RmtCtlSnsRrCrnr_D_Stat 1;
BA_ "U_V710_MY2023_Tx" SG_ 1233 RmtCtlSnsRrCrnr_D_Stat 1;
BA_ "U_P702_MY2024_Tx" SG_ 1233 RmtCtlSnsRrCrnr_D_Stat 1;
BA_ "GenSigSendType" SG_ 1233 RmtCtlSnsRlCrnr_D_Stat 3;
BA_ "U_P708_MY2023_Tx" SG_ 1233 RmtCtlSnsRlCrnr_D_Stat 1;
BA_ "U_V710_MY2023_Tx" SG_ 1233 RmtCtlSnsRlCrnr_D_Stat 1;
BA_ "U_P702_MY2024_Tx" SG_ 1233 RmtCtlSnsRlCrnr_D_Stat 1;
BA_ "GenSigSendType" SG_ 1233 RmtCtlSnsRear_D_Stat 3;
BA_ "U_P708_MY2023_Tx" SG_ 1233 RmtCtlSnsRear_D_Stat 1;
BA_ "U_V710_MY2023_Tx" SG_ 1233 RmtCtlSnsRear_D_Stat 1;
BA_ "U_P702_MY2024_Tx" SG_ 1233 RmtCtlSnsRear_D_Stat 1;
BA_ "GenSigSendType" SG_ 1233 RmtCtlSnsFront_D_Stat 3;
BA_ "U_P708_MY2023_Tx" SG_ 1233 RmtCtlSnsFront_D_Stat 1;
BA_ "U_V710_MY2023_Tx" SG_ 1233 RmtCtlSnsFront_D_Stat 1;
BA_ "U_P702_MY2024_Tx" SG_ 1233 RmtCtlSnsFront_D_Stat 1;
BA_ "GenSigSendType" SG_ 1233 RmtCtlSnsFrCrnr_D_Stat 3;
BA_ "U_P708_MY2023_Tx" SG_ 1233 RmtCtlSnsFrCrnr_D_Stat 1;
BA_ "U_V710_MY2023_Tx" SG_ 1233 RmtCtlSnsFrCrnr_D_Stat 1;
BA_ "U_P702_MY2024_Tx" SG_ 1233 RmtCtlSnsFrCrnr_D_Stat 1;
BA_ "GenSigSendType" SG_ 1233 RmtCtlSnsFlCrnr_D_Stat 3;
BA_ "U_P708_MY2023_Tx" SG_ 1233 RmtCtlSnsFlCrnr_D_Stat 1;
BA_ "U_V710_MY2023_Tx" SG_ 1233 RmtCtlSnsFlCrnr_D_Stat 1;
BA_ "U_P702_MY2024_Tx" SG_ 1233 RmtCtlSnsFlCrnr_D_Stat 1;
BA_ "GenSigSendType" SG_ 1233 RmtCtlSideSnsR4_D_Stat 3;
BA_ "U_P708_MY2023_Tx" SG_ 1233 RmtCtlSideSnsR4_D_Stat 1;
BA_ "U_V710_MY2023_Tx" SG_ 1233 RmtCtlSideSnsR4_D_Stat 1;
BA_ "U_P702_MY2024_Tx" SG_ 1233 RmtCtlSideSnsR4_D_Stat 1;
BA_ "GenSigSendType" SG_ 1233 RmtCtlSideSnsR3_D_Stat 3;
BA_ "U_P708_MY2023_Tx" SG_ 1233 RmtCtlSideSnsR3_D_Stat 1;
BA_ "U_V710_MY2023_Tx" SG_ 1233 RmtCtlSideSnsR3_D_Stat 1;
BA_ "U_P702_MY2024_Tx" SG_ 1233 RmtCtlSideSnsR3_D_Stat 1;
BA_ "GenSigSendType" SG_ 1233 RmtCtlSideSnsR2_D_Stat 3;
BA_ "U_P708_MY2023_Tx" SG_ 1233 RmtCtlSideSnsR2_D_Stat 1;
BA_ "U_V710_MY2023_Tx" SG_ 1233 RmtCtlSideSnsR2_D_Stat 1;
BA_ "U_P702_MY2024_Tx" SG_ 1233 RmtCtlSideSnsR2_D_Stat 1;
BA_ "GenSigSendType" SG_ 1233 RmtCtlSideSnsR1_D_Stat 3;
BA_ "U_P708_MY2023_Tx" SG_ 1233 RmtCtlSideSnsR1_D_Stat 1;
BA_ "U_V710_MY2023_Tx" SG_ 1233 RmtCtlSideSnsR1_D_Stat 1;
BA_ "U_P702_MY2024_Tx" SG_ 1233 RmtCtlSideSnsR1_D_Stat 1;
BA_ "GenSigSendType" SG_ 1233 RmtCtlSideSnsL4_D_Stat 3;
BA_ "U_P708_MY2023_Tx" SG_ 1233 RmtCtlSideSnsL4_D_Stat 1;
BA_ "U_V710_MY2023_Tx" SG_ 1233 RmtCtlSideSnsL4_D_Stat 1;
BA_ "U_P702_MY2024_Tx" SG_ 1233 RmtCtlSideSnsL4_D_Stat 1;
BA_ "GenSigSendType" SG_ 1233 RmtCtlSideSnsL3_D_Stat 3;
BA_ "U_P708_MY2023_Tx" SG_ 1233 RmtCtlSideSnsL3_D_Stat 1;
BA_ "U_V710_MY2023_Tx" SG_ 1233 RmtCtlSideSnsL3_D_Stat 1;
BA_ "U_P702_MY2024_Tx" SG_ 1233 RmtCtlSideSnsL3_D_Stat 1;
BA_ "GenSigSendType" SG_ 1233 RmtCtlSideSnsL2_D_Stat 3;
BA_ "U_P708_MY2023_Tx" SG_ 1233 RmtCtlSideSnsL2_D_Stat 1;
BA_ "U_V710_MY2023_Tx" SG_ 1233 RmtCtlSideSnsL2_D_Stat 1;
BA_ "U_P702_MY2024_Tx" SG_ 1233 RmtCtlSideSnsL2_D_Stat 1;
BA_ "GenSigSendType" SG_ 1233 RmtCtlSideSnsL1_D_Stat 3;
BA_ "U_P708_MY2023_Tx" SG_ 1233 RmtCtlSideSnsL1_D_Stat 1;
BA_ "U_V710_MY2023_Tx" SG_ 1233 RmtCtlSideSnsL1_D_Stat 1;
BA_ "U_P702_MY2024_Tx" SG_ 1233 RmtCtlSideSnsL1_D_Stat 1;
BA_ "GenSigSendType" SG_ 1233 RmtCtlRightOrnt_D_Avail 3;
BA_ "U_P708_MY2023_Tx" SG_ 1233 RmtCtlRightOrnt_D_Avail 1;
BA_ "U_V710_MY2023_Tx" SG_ 1233 RmtCtlRightOrnt_D_Avail 1;
BA_ "U_P702_MY2024_Tx" SG_ 1233 RmtCtlRightOrnt_D_Avail 1;
BA_ "GenSigSendType" SG_ 1233 RmtCtlRight_D_Avail 3;
BA_ "U_P708_MY2023_Tx" SG_ 1233 RmtCtlRight_D_Avail 1;
BA_ "U_V710_MY2023_Tx" SG_ 1233 RmtCtlRight_D_Avail 1;
BA_ "U_P702_MY2024_Tx" SG_ 1233 RmtCtlRight_D_Avail 1;
BA_ "GenSigSendType" SG_ 1233 RmtCtlRear_D_Avail 3;
BA_ "U_P708_MY2023_Tx" SG_ 1233 RmtCtlRear_D_Avail 1;
BA_ "U_V710_MY2023_Tx" SG_ 1233 RmtCtlRear_D_Avail 1;
BA_ "U_P702_MY2024_Tx" SG_ 1233 RmtCtlRear_D_Avail 1;
BA_ "GenSigSendType" SG_ 1233 RmtCtlPrkMde_D_Stat 3;
BA_ "U_P708_MY2023_Tx" SG_ 1233 RmtCtlPrkMde_D_Stat 1;
BA_ "U_V710_MY2023_Tx" SG_ 1233 RmtCtlPrkMde_D_Stat 1;
BA_ "U_P702_MY2024_Tx" SG_ 1233 RmtCtlPrkMde_D_Stat 1;
BA_ "GenSigSendType" SG_ 1233 RmtCtlPrkInSlot_D_Stat 3;
BA_ "U_P708_MY2023_Tx" SG_ 1233 RmtCtlPrkInSlot_D_Stat 1;
BA_ "U_V710_MY2023_Tx" SG_ 1233 RmtCtlPrkInSlot_D_Stat 1;
BA_ "U_P702_MY2024_Tx" SG_ 1233 RmtCtlPrkInSlot_D_Stat 1;
BA_ "GenSigSendType" SG_ 1233 RmtCtlObstcl_B_Stat 3;
BA_ "U_P708_MY2023_Tx" SG_ 1233 RmtCtlObstcl_B_Stat 1;
BA_ "U_V710_MY2023_Tx" SG_ 1233 RmtCtlObstcl_B_Stat 1;
BA_ "U_P702_MY2024_Tx" SG_ 1233 RmtCtlObstcl_B_Stat 1;
BA_ "GenSigSendType" SG_ 1233 RmtCtlNxtMoveDir_D_Stat 3;
BA_ "U_P708_MY2023_Tx" SG_ 1233 RmtCtlNxtMoveDir_D_Stat 1;
BA_ "U_V710_MY2023_Tx" SG_ 1233 RmtCtlNxtMoveDir_D_Stat 1;
BA_ "U_P702_MY2024_Tx" SG_ 1233 RmtCtlNxtMoveDir_D_Stat 1;
BA_ "GenSigSendType" SG_ 1233 RmtCtlMoveDir_D_Stat 3;
BA_ "U_P708_MY2023_Tx" SG_ 1233 RmtCtlMoveDir_D_Stat 1;
BA_ "U_V710_MY2023_Tx" SG_ 1233 RmtCtlMoveDir_D_Stat 1;
BA_ "U_P702_MY2024_Tx" SG_ 1233 RmtCtlMoveDir_D_Stat 1;
BA_ "GenSigSendType" SG_ 1233 RmtCtlLeftOrnt_D_Avail 3;
BA_ "U_P708_MY2023_Tx" SG_ 1233 RmtCtlLeftOrnt_D_Avail 1;
BA_ "U_V710_MY2023_Tx" SG_ 1233 RmtCtlLeftOrnt_D_Avail 1;
BA_ "U_P702_MY2024_Tx" SG_ 1233 RmtCtlLeftOrnt_D_Avail 1;
BA_ "GenSigSendType" SG_ 1233 RmtCtlLeft_D_Avail 3;
BA_ "U_P708_MY2023_Tx" SG_ 1233 RmtCtlLeft_D_Avail 1;
BA_ "U_V710_MY2023_Tx" SG_ 1233 RmtCtlLeft_D_Avail 1;
BA_ "U_P702_MY2024_Tx" SG_ 1233 RmtCtlLeft_D_Avail 1;
BA_ "GenSigSendType" SG_ 1233 RmtCtlFront_D_Avail 3;
BA_ "U_P708_MY2023_Tx" SG_ 1233 RmtCtlFront_D_Avail 1;
BA_ "U_V710_MY2023_Tx" SG_ 1233 RmtCtlFront_D_Avail 1;
BA_ "U_P702_MY2024_Tx" SG_ 1233 RmtCtlFront_D_Avail 1;
BA_ "U_P708_MY2023_Rx" SG_ 817 VehLckInd_D_Rq 1;
BA_ "U_P702_MY2024_Rx" SG_ 817 VehLckInd_D_Rq 1;
BA_ "WakeupSignal" SG_ 817 DrTgateOpen_B_Rq 1;
BA_ "WakeupSignal" SG_ 817 DrTgateExtSwMde_B_Stat 1;
BA_ "WakeupSignal" SG_ 817 Remote_Device_Feedback 1;
BA_ "WakeupSignal" SG_ 817 Veh_Lock_Requestor 1;
BA_ "U_P708_MY2023_Rx" SG_ 817 Veh_Lock_Requestor 1;
BA_ "U_P702_MY2024_Rx" SG_ 817 Veh_Lock_Requestor 1;
BA_ "WakeupSignal" SG_ 817 R_Pwr_Sliding_Dr_Rqst 1;
BA_ "WakeupSignal" SG_ 817 Power_Liftgate_Rqst 1;
BA_ "WakeupSignal" SG_ 817 Veh_Lock_EvNum 1;
BA_ "U_P708_MY2023_Rx" SG_ 817 Veh_Lock_EvNum 1;
BA_ "U_P702_MY2024_Rx" SG_ 817 Veh_Lock_EvNum 1;
BA_ "WakeupSignal" SG_ 817 Power_Decklid_Rqst 1;
BA_ "WakeupSignal" SG_ 817 L_Pwr_Sliding_Dr_Rqst 1;
BA_ "WakeupSignal" SG_ 817 Keyfob_Pad_Msg_Count 1;
BA_ "MetaData" SG_ 817 Keyfob_Pad_Msg_Count 1;
BA_ "U_P708_MY2023_Rx" SG_ 817 Veh_Lock_Sub_Id 1;
BA_ "U_P702_MY2024_Rx" SG_ 817 Veh_Lock_Sub_Id 1;
BA_ "WakeupSignal" SG_ 817 Veh_Lock_Status 1;
BA_ "GenSigStartValue" SG_ 817 Veh_Lock_Status 1;
BA_ "U_P708_MY2023_Rx" SG_ 817 Veh_Lock_Status 1;
BA_ "U_V710_MY2023_Rx" SG_ 817 Veh_Lock_Status 1;
BA_ "U_P702_MY2024_Rx" SG_ 817 Veh_Lock_Status 1;
BA_ "U_P708_MY2023_Rx" SG_ 817 WindowLockout_B_Stat 1;
BA_ "U_P702_MY2024_Rx" SG_ 817 WindowLockout_B_Stat 1;
BA_ "U_P708_MY2023_Rx" SG_ 817 RollCodeUnlock 1;
BA_ "U_P702_MY2024_Rx" SG_ 817 RollCodeUnlock 1;
BA_ "WakeupSignal" SG_ 817 Lockmsgtxt_D_Rq 1;
BA_ "WakeupSignal" SG_ 817 LockInhibit 1;
BA_ "GenSigSendType" SG_ 2612194520 PARSEDPushFcGWM_ECGtoCMR 3;
BA_ "ECGUsedTxSignal" SG_ 2612194520 PARSEDPushFcGWM_ECGtoCMR 1;
BA_ "U_P708_MY2023_Tx" SG_ 2612194520 PARSEDPushFcGWM_ECGtoCMR 1;
BA_ "U_CDX74X_MY2024_Tx" SG_ 2612194520 PARSEDPushFcGWM_ECGtoCMR 1;
BA_ "U_V710_MY2023_Tx" SG_ 2612194520 PARSEDPushFcGWM_ECGtoCMR 1;
BA_ "U_P702_MY2024_Tx" SG_ 2612194520 PARSEDPushFcGWM_ECGtoCMR 1;
BA_ "GenSigSendType" SG_ 2611145944 PARSEDPhysGWM_ECGtoCMR 3;
BA_ "ECGUsedTxSignal" SG_ 2611145944 PARSEDPhysGWM_ECGtoCMR 1;
BA_ "U_P708_MY2023_Tx" SG_ 2611145944 PARSEDPhysGWM_ECGtoCMR 1;
BA_ "U_CDX74X_MY2024_Tx" SG_ 2611145944 PARSEDPhysGWM_ECGtoCMR 1;
BA_ "U_P702_MY2024_Tx" SG_ 2611145944 PARSEDPhysGWM_ECGtoCMR 1;
BA_ "WakeupSignal" SG_ 954 LghtAmbDrvMde_B_Stat 1;
BA_ "WakeupSignal" SG_ 954 TrukBedLght_B_Stat 1;
BA_ "WakeupSignal" SG_ 954 TrlrHitchLamp_D_Stat 1;
BA_ "WakeupSignal" SG_ 954 ExtLghtRight_D_Stat 1;
BA_ "WakeupSignal" SG_ 954 ExtLghtRear_D_Stat 1;
BA_ "WakeupSignal" SG_ 954 ExtLghtLeft_D_Stat 1;
BA_ "WakeupSignal" SG_ 954 ExtLghtFront_D_Stat 1;
BA_ "WakeupSignal" SG_ 954 ExtLghtAlrt_B_Rq 1;
BA_ "WakeupSignal" SG_ 954 ExtLght_D_Falt 1;
BA_ "U_P708_MY2023_Rx" SG_ 954 ChildLckMaint_D_Stat 1;
BA_ "U_V710_MY2023_Rx" SG_ 954 ChildLckMaint_D_Stat 1;
BA_ "U_P702_MY2024_Rx" SG_ 954 ChildLckMaint_D_Stat 1;
BA_ "WakeupSignal" SG_ 954 ExtLghtFront_D_RqBody 1;
BA_ "GenSigStartValue" SG_ 954 ExtLghtFront_D_RqBody 1;
BA_ "U_P708_MY2023_Rx" SG_ 954 ExtLghtFront_D_RqBody 1;
BA_ "U_CDX74X_MY2024_Rx" SG_ 954 ExtLghtFront_D_RqBody 1;
BA_ "U_V710_MY2023_Rx" SG_ 954 ExtLghtFront_D_RqBody 1;
BA_ "U_P702_MY2024_Rx" SG_ 954 ExtLghtFront_D_RqBody 1;
BA_ "WakeupSignal" SG_ 954 VehWlcmFrwlMde_D_Stat 1;
BA_ "U_P708_MY2023_Rx" SG_ 954 VehWlcmFrwlMde_D_Stat 1;
BA_ "U_CDX74X_MY2024_Rx" SG_ 954 VehWlcmFrwlMde_D_Stat 1;
BA_ "U_V710_MY2023_Rx" SG_ 954 VehWlcmFrwlMde_D_Stat 1;
BA_ "U_P702_MY2024_Rx" SG_ 954 VehWlcmFrwlMde_D_Stat 1;
BA_ "WakeupSignal" SG_ 954 PwRnngBoardPoll_D_Stat 1;
BA_ "U_P708_MY2023_Rx" SG_ 954 PwRnngBoardPoll_D_Stat 1;
BA_ "U_P702_MY2024_Rx" SG_ 954 PwRnngBoardPoll_D_Stat 1;
BA_ "U_P708_MY2023_Rx" SG_ 954 GenericSwtch3_No_Actl 1;
BA_ "U_CDX74X_MY2024_Rx" SG_ 954 GenericSwtch3_No_Actl 1;
BA_ "U_V710_MY2023_Rx" SG_ 954 GenericSwtch3_No_Actl 1;
BA_ "U_P702_MY2024_Rx" SG_ 954 GenericSwtch3_No_Actl 1;
BA_ "U_P708_MY2023_Rx" SG_ 954 GenericSwtch2_No_Actl 1;
BA_ "U_CDX74X_MY2024_Rx" SG_ 954 GenericSwtch2_No_Actl 1;
BA_ "U_V710_MY2023_Rx" SG_ 954 GenericSwtch2_No_Actl 1;
BA_ "U_P702_MY2024_Rx" SG_ 954 GenericSwtch2_No_Actl 1;
BA_ "U_P708_MY2023_Rx" SG_ 954 GenericSwtch1_No_Actl 1;
BA_ "U_CDX74X_MY2024_Rx" SG_ 954 GenericSwtch1_No_Actl 1;
BA_ "U_V710_MY2023_Rx" SG_ 954 GenericSwtch1_No_Actl 1;
BA_ "U_P702_MY2024_Rx" SG_ 954 GenericSwtch1_No_Actl 1;
BA_ "WakeupSignal" SG_ 954 PudSptLghtRight_D_Rq 1;
BA_ "U_P708_MY2023_Rx" SG_ 954 PudSptLghtRight_D_Rq 1;
BA_ "U_P702_MY2024_Rx" SG_ 954 PudSptLghtRight_D_Rq 1;
BA_ "WakeupSignal" SG_ 954 PudSptLghtLeft_D_Rq 1;
BA_ "U_P708_MY2023_Rx" SG_ 954 PudSptLghtLeft_D_Rq 1;
BA_ "U_P702_MY2024_Rx" SG_ 954 PudSptLghtLeft_D_Rq 1;
BA_ "U_P708_MY2023_Rx" SG_ 954 PoliceDmngLvl_D_Stat 1;
BA_ "U_P702_MY2024_Rx" SG_ 954 PoliceDmngLvl_D_Stat 1;
BA_ "WakeupSignal" SG_ 954 VehWlcmFrwl_D_Stat 1;
BA_ "U_P708_MY2023_Rx" SG_ 954 VehWlcmFrwl_D_Stat 1;
BA_ "U_CDX74X_MY2024_Rx" SG_ 954 VehWlcmFrwl_D_Stat 1;
BA_ "U_V710_MY2023_Rx" SG_ 954 VehWlcmFrwl_D_Stat 1;
BA_ "U_P702_MY2024_Rx" SG_ 954 VehWlcmFrwl_D_Stat 1;
BA_ "U_P708_MY2023_Rx" SG_ 954 PosLghtFr_D_Stat 1;
BA_ "U_CDX74X_MY2024_Rx" SG_ 954 PosLghtFr_D_Stat 1;
BA_ "U_V710_MY2023_Rx" SG_ 954 PosLghtFr_D_Stat 1;
BA_ "U_P702_MY2024_Rx" SG_ 954 PosLghtFr_D_Stat 1;
BA_ "U_P708_MY2023_Rx" SG_ 954 PosLghtFl_D_Stat 1;
BA_ "U_CDX74X_MY2024_Rx" SG_ 954 PosLghtFl_D_Stat 1;
BA_ "U_V710_MY2023_Rx" SG_ 954 PosLghtFl_D_Stat 1;
BA_ "U_P702_MY2024_Rx" SG_ 954 PosLghtFl_D_Stat 1;
BA_ "GenSigSendType" SG_ 1844 TesterPhysicalReqHCM 3;
BA_ "U_P708_MY2023_Rx" SG_ 1844 TesterPhysicalReqHCM 1;
BA_ "U_CDX74X_MY2024_Rx" SG_ 1844 TesterPhysicalReqHCM 1;
BA_ "U_V710_MY2023_Rx" SG_ 1844 TesterPhysicalReqHCM 1;
BA_ "U_P702_MY2024_Rx" SG_ 1844 TesterPhysicalReqHCM 1;
BA_ "GenSigSendType" SG_ 1852 TesterPhysicalResHCM 3;
BA_ "U_P708_MY2023_Tx" SG_ 1852 TesterPhysicalResHCM 1;
BA_ "U_CDX74X_MY2024_Tx" SG_ 1852 TesterPhysicalResHCM 1;
BA_ "U_V710_MY2023_Tx" SG_ 1852 TesterPhysicalResHCM 1;
BA_ "U_P702_MY2024_Tx" SG_ 1852 TesterPhysicalResHCM 1;
BA_ "GenSigSendType" SG_ 989 FeatNoHcm_No_Actl 3;
BA_ "U_P708_MY2023_Tx" SG_ 989 FeatNoHcm_No_Actl 1;
BA_ "U_CDX74X_MY2024_Tx" SG_ 989 FeatNoHcm_No_Actl 1;
BA_ "U_V710_MY2023_Tx" SG_ 989 FeatNoHcm_No_Actl 1;
BA_ "U_P702_MY2024_Tx" SG_ 989 FeatNoHcm_No_Actl 1;
BA_ "GenSigSendType" SG_ 989 FeatConfigHcmActl 3;
BA_ "U_P708_MY2023_Tx" SG_ 989 FeatConfigHcmActl 1;
BA_ "U_CDX74X_MY2024_Tx" SG_ 989 FeatConfigHcmActl 1;
BA_ "U_V710_MY2023_Tx" SG_ 989 FeatConfigHcmActl 1;
BA_ "U_P702_MY2024_Tx" SG_ 989 FeatConfigHcmActl 1;
BA_ "GenSigSendType" SG_ 820 AhbStatGfhbFdbk_D_Actl 3;
BA_ "U_P708_MY2023_Rx" SG_ 820 AhbStatGfhbFdbk_D_Actl 1;
BA_ "U_V710_MY2023_Rx" SG_ 820 AhbStatGfhbFdbk_D_Actl 1;
BA_ "U_P702_MY2024_Rx" SG_ 820 AhbStatGfhbFdbk_D_Actl 1;
BA_ "U_P708_MY2023_Tx" SG_ 820 AhbStatGfhbFdbk_D_Actl 1;
BA_ "U_CDX74X_MY2024_Tx" SG_ 820 AhbStatGfhbFdbk_D_Actl 1;
BA_ "U_V710_MY2023_Tx" SG_ 820 AhbStatGfhbFdbk_D_Actl 1;
BA_ "U_P702_MY2024_Tx" SG_ 820 AhbStatGfhbFdbk_D_Actl 1;
BA_ "GenSigSendType" SG_ 820 TurnLampFrOut_B_Stat 3;
BA_ "U_P708_MY2023_Tx" SG_ 820 TurnLampFrOut_B_Stat 1;
BA_ "U_CDX74X_MY2024_Tx" SG_ 820 TurnLampFrOut_B_Stat 1;
BA_ "U_V710_MY2023_Tx" SG_ 820 TurnLampFrOut_B_Stat 1;
BA_ "U_P702_MY2024_Tx" SG_ 820 TurnLampFrOut_B_Stat 1;
BA_ "GenSigSendType" SG_ 820 TurnLampFlOut_B_Stat 3;
BA_ "U_P708_MY2023_Tx" SG_ 820 TurnLampFlOut_B_Stat 1;
BA_ "U_CDX74X_MY2024_Tx" SG_ 820 TurnLampFlOut_B_Stat 1;
BA_ "U_V710_MY2023_Tx" SG_ 820 TurnLampFlOut_B_Stat 1;
BA_ "U_P702_MY2024_Tx" SG_ 820 TurnLampFlOut_B_Stat 1;
BA_ "GenSigSendType" SG_ 820 HeadLghtDrvSide_B_Stat 3;
BA_ "U_P708_MY2023_Rx" SG_ 820 HeadLghtDrvSide_B_Stat 1;
BA_ "U_V710_MY2023_Rx" SG_ 820 HeadLghtDrvSide_B_Stat 1;
BA_ "U_P702_MY2024_Rx" SG_ 820 HeadLghtDrvSide_B_Stat 1;
BA_ "U_P708_MY2023_Tx" SG_ 820 HeadLghtDrvSide_B_Stat 1;
BA_ "U_CDX74X_MY2024_Tx" SG_ 820 HeadLghtDrvSide_B_Stat 1;
BA_ "U_V710_MY2023_Tx" SG_ 820 HeadLghtDrvSide_B_Stat 1;
BA_ "U_P702_MY2024_Tx" SG_ 820 HeadLghtDrvSide_B_Stat 1;
BA_ "GenSigSendType" SG_ 820 HeadLghtHiOn_B_StatHcm 3;
BA_ "U_P708_MY2023_Tx" SG_ 820 HeadLghtHiOn_B_StatHcm 1;
BA_ "U_CDX74X_MY2024_Tx" SG_ 820 HeadLghtHiOn_B_StatHcm 1;
BA_ "U_V710_MY2023_Tx" SG_ 820 HeadLghtHiOn_B_StatHcm 1;
BA_ "U_P702_MY2024_Tx" SG_ 820 HeadLghtHiOn_B_StatHcm 1;
BA_ "GenSigSendType" SG_ 820 Adaptive_Hdlmp_Fault 3;
BA_ "U_P708_MY2023_Tx" SG_ 820 Adaptive_Hdlmp_Fault 1;
BA_ "U_CDX74X_MY2024_Tx" SG_ 820 Adaptive_Hdlmp_Fault 1;
BA_ "U_V710_MY2023_Tx" SG_ 820 Adaptive_Hdlmp_Fault 1;
BA_ "U_P702_MY2024_Tx" SG_ 820 Adaptive_Hdlmp_Fault 1;
BA_ "U_P708_MY2023_Rx" SG_ 402 CamraFrntBttn_D_Stat3 1;
BA_ "U_V710_MY2023_Rx" SG_ 402 CamraFrntBttn_D_Stat3 1;
BA_ "U_P702_MY2024_Rx" SG_ 402 CamraFrntBttn_D_Stat3 1;
BA_ "U_P708_MY2023_Rx" SG_ 402 PrkAidSwtch_D_RqMnu 1;
BA_ "U_V710_MY2023_Rx" SG_ 402 PrkAidSwtch_D_RqMnu 1;
BA_ "U_P702_MY2024_Rx" SG_ 402 PrkAidSwtch_D_RqMnu 1;
BA_ "U_P708_MY2023_Rx" SG_ 402 ApaSwtch_D_RqMnu 1;
BA_ "U_V710_MY2023_Rx" SG_ 402 ApaSwtch_D_RqMnu 1;
BA_ "U_P702_MY2024_Rx" SG_ 402 ApaSwtch_D_RqMnu 1;
BA_ "U_P708_MY2023_Rx" SG_ 402 ApaMdeStat_D_RqDrv 1;
BA_ "U_V710_MY2023_Rx" SG_ 402 ApaMdeStat_D_RqDrv 1;
BA_ "U_P702_MY2024_Rx" SG_ 402 ApaMdeStat_D_RqDrv 1;
BA_ "U_P708_MY2023_Rx" SG_ 402 ApaSlotAlrtSet_D_RqDrv 1;
BA_ "U_V710_MY2023_Rx" SG_ 402 ApaSlotAlrtSet_D_RqDrv 1;
BA_ "U_P702_MY2024_Rx" SG_ 402 ApaSlotAlrtSet_D_RqDrv 1;
BA_ "U_P708_MY2023_Rx" SG_ 402 ApaSlotTrgt_D_RqDrv 1;
BA_ "U_V710_MY2023_Rx" SG_ 402 ApaSlotTrgt_D_RqDrv 1;
BA_ "U_P702_MY2024_Rx" SG_ 402 ApaSlotTrgt_D_RqDrv 1;
BA_ "U_P708_MY2023_Rx" SG_ 402 ApaFeat_D_RqDrv 1;
BA_ "U_V710_MY2023_Rx" SG_ 402 ApaFeat_D_RqDrv 1;
BA_ "U_P702_MY2024_Rx" SG_ 402 ApaFeat_D_RqDrv 1;
BA_ "U_P708_MY2023_Rx" SG_ 402 ApaFeatChange_B_RqDrv 1;
BA_ "U_V710_MY2023_Rx" SG_ 402 ApaFeatChange_B_RqDrv 1;
BA_ "U_P702_MY2024_Rx" SG_ 402 ApaFeatChange_B_RqDrv 1;
BA_ "GenSigSendType" SG_ 2612170968 PARSEDPushFcGWM_ECGtoPDM 3;
BA_ "U_P708_MY2023_Rx" SG_ 2612170968 PARSEDPushFcGWM_ECGtoPDM 1;
BA_ "U_P702_MY2024_Rx" SG_ 2612170968 PARSEDPushFcGWM_ECGtoPDM 1;
BA_ "ECGUsedTxSignal" SG_ 2612170968 PARSEDPushFcGWM_ECGtoPDM 1;
BA_ "U_P708_MY2023_Tx" SG_ 2612170968 PARSEDPushFcGWM_ECGtoPDM 1;
BA_ "U_P702_MY2024_Tx" SG_ 2612170968 PARSEDPushFcGWM_ECGtoPDM 1;
BA_ "GenSigSendType" SG_ 2612166872 PARSEDPushFcGWM_ECGtoDDM 3;
BA_ "U_P708_MY2023_Rx" SG_ 2612166872 PARSEDPushFcGWM_ECGtoDDM 1;
BA_ "U_P702_MY2024_Rx" SG_ 2612166872 PARSEDPushFcGWM_ECGtoDDM 1;
BA_ "ECGUsedTxSignal" SG_ 2612166872 PARSEDPushFcGWM_ECGtoDDM 1;
BA_ "U_P708_MY2023_Tx" SG_ 2612166872 PARSEDPushFcGWM_ECGtoDDM 1;
BA_ "U_P702_MY2024_Tx" SG_ 2612166872 PARSEDPushFcGWM_ECGtoDDM 1;
BA_ "GenSigSendType" SG_ 2611122392 PARSEDPhysGWM_ECGtoPDM 3;
BA_ "U_P708_MY2023_Rx" SG_ 2611122392 PARSEDPhysGWM_ECGtoPDM 1;
BA_ "U_P702_MY2024_Rx" SG_ 2611122392 PARSEDPhysGWM_ECGtoPDM 1;
BA_ "ECGUsedTxSignal" SG_ 2611122392 PARSEDPhysGWM_ECGtoPDM 1;
BA_ "U_P708_MY2023_Tx" SG_ 2611122392 PARSEDPhysGWM_ECGtoPDM 1;
BA_ "U_CDX74X_MY2024_Tx" SG_ 2611122392 PARSEDPhysGWM_ECGtoPDM 1;
BA_ "U_P702_MY2024_Tx" SG_ 2611122392 PARSEDPhysGWM_ECGtoPDM 1;
BA_ "GenSigSendType" SG_ 2611118296 PARSEDPhysGWM_ECGtoDDM 3;
BA_ "U_P708_MY2023_Rx" SG_ 2611118296 PARSEDPhysGWM_ECGtoDDM 1;
BA_ "U_P702_MY2024_Rx" SG_ 2611118296 PARSEDPhysGWM_ECGtoDDM 1;
BA_ "ECGUsedTxSignal" SG_ 2611118296 PARSEDPhysGWM_ECGtoDDM 1;
BA_ "U_P708_MY2023_Tx" SG_ 2611118296 PARSEDPhysGWM_ECGtoDDM 1;
BA_ "U_CDX74X_MY2024_Tx" SG_ 2611118296 PARSEDPhysGWM_ECGtoDDM 1;
BA_ "U_P702_MY2024_Tx" SG_ 2611118296 PARSEDPhysGWM_ECGtoDDM 1;
BA_ "GenSigSendType" SG_ 2612224164 PARSEDPushPDMtoGWM_ECG 3;
BA_ "ECGUsedRxSignal" SG_ 2612224164 PARSEDPushPDMtoGWM_ECG 1;
BA_ "U_P708_MY2023_Rx" SG_ 2612224164 PARSEDPushPDMtoGWM_ECG 1;
BA_ "U_P702_MY2024_Rx" SG_ 2612224164 PARSEDPushPDMtoGWM_ECG 1;
BA_ "U_P708_MY2023_Tx" SG_ 2612224164 PARSEDPushPDMtoGWM_ECG 1;
BA_ "U_V710_MY2023_Tx" SG_ 2612224164 PARSEDPushPDMtoGWM_ECG 1;
BA_ "U_P702_MY2024_Tx" SG_ 2612224164 PARSEDPushPDMtoGWM_ECG 1;
BA_ "GenSigSendType" SG_ 2612224160 PARSEDPushDDMtoGWM_ECG 3;
BA_ "ECGUsedRxSignal" SG_ 2612224160 PARSEDPushDDMtoGWM_ECG 1;
BA_ "U_P708_MY2023_Rx" SG_ 2612224160 PARSEDPushDDMtoGWM_ECG 1;
BA_ "U_P702_MY2024_Rx" SG_ 2612224160 PARSEDPushDDMtoGWM_ECG 1;
BA_ "U_P708_MY2023_Tx" SG_ 2612224160 PARSEDPushDDMtoGWM_ECG 1;
BA_ "U_P702_MY2024_Tx" SG_ 2612224160 PARSEDPushDDMtoGWM_ECG 1;
BA_ "GenSigSendType" SG_ 2611175588 PARSEDPhysPDMtoGWM_ECG 3;
BA_ "ECGUsedRxSignal" SG_ 2611175588 PARSEDPhysPDMtoGWM_ECG 1;
BA_ "U_P708_MY2023_Rx" SG_ 2611175588 PARSEDPhysPDMtoGWM_ECG 1;
BA_ "U_CDX74X_MY2024_Rx" SG_ 2611175588 PARSEDPhysPDMtoGWM_ECG 1;
BA_ "U_P702_MY2024_Rx" SG_ 2611175588 PARSEDPhysPDMtoGWM_ECG 1;
BA_ "U_P708_MY2023_Tx" SG_ 2611175588 PARSEDPhysPDMtoGWM_ECG 1;
BA_ "U_V710_MY2023_Tx" SG_ 2611175588 PARSEDPhysPDMtoGWM_ECG 1;
BA_ "U_P702_MY2024_Tx" SG_ 2611175588 PARSEDPhysPDMtoGWM_ECG 1;
BA_ "GenSigSendType" SG_ 2611175584 PARSEDPhysDDMtoGWM_ECG 3;
BA_ "ECGUsedRxSignal" SG_ 2611175584 PARSEDPhysDDMtoGWM_ECG 1;
BA_ "U_P708_MY2023_Rx" SG_ 2611175584 PARSEDPhysDDMtoGWM_ECG 1;
BA_ "U_P702_MY2024_Rx" SG_ 2611175584 PARSEDPhysDDMtoGWM_ECG 1;
BA_ "U_P708_MY2023_Tx" SG_ 2611175584 PARSEDPhysDDMtoGWM_ECG 1;
BA_ "U_P702_MY2024_Tx" SG_ 2611175584 PARSEDPhysDDMtoGWM_ECG 1;
BA_ "GenSigSendType" SG_ 2610073816 OTAPhysGWM_ECGtoPDM 3;
BA_ "U_P708_MY2023_Rx" SG_ 2610073816 OTAPhysGWM_ECGtoPDM 1;
BA_ "U_P702_MY2024_Rx" SG_ 2610073816 OTAPhysGWM_ECGtoPDM 1;
BA_ "ECGUsedTxSignal" SG_ 2610073816 OTAPhysGWM_ECGtoPDM 1;
BA_ "U_P708_MY2023_Tx" SG_ 2610073816 OTAPhysGWM_ECGtoPDM 1;
BA_ "U_P702_MY2024_Tx" SG_ 2610073816 OTAPhysGWM_ECGtoPDM 1;
BA_ "GenSigSendType" SG_ 2610069720 OTAPhysGWM_ECGtoDDM 3;
BA_ "U_P708_MY2023_Rx" SG_ 2610069720 OTAPhysGWM_ECGtoDDM 1;
BA_ "U_P702_MY2024_Rx" SG_ 2610069720 OTAPhysGWM_ECGtoDDM 1;
BA_ "ECGUsedTxSignal" SG_ 2610069720 OTAPhysGWM_ECGtoDDM 1;
BA_ "U_P708_MY2023_Tx" SG_ 2610069720 OTAPhysGWM_ECGtoDDM 1;
BA_ "U_P702_MY2024_Tx" SG_ 2610069720 OTAPhysGWM_ECGtoDDM 1;
BA_ "GenSigSendType" SG_ 2610127012 OTAPhysPDMtoGWM_ECG 3;
BA_ "ECGUsedRxSignal" SG_ 2610127012 OTAPhysPDMtoGWM_ECG 1;
BA_ "U_P708_MY2023_Rx" SG_ 2610127012 OTAPhysPDMtoGWM_ECG 1;
BA_ "U_CDX74X_MY2024_Rx" SG_ 2610127012 OTAPhysPDMtoGWM_ECG 1;
BA_ "U_P702_MY2024_Rx" SG_ 2610127012 OTAPhysPDMtoGWM_ECG 1;
BA_ "U_V713N_MY2022_Tx" SG_ 2610127012 OTAPhysPDMtoGWM_ECG 1;
BA_ "U_P708_MY2023_Tx" SG_ 2610127012 OTAPhysPDMtoGWM_ECG 1;
BA_ "U_V710_MY2023_Tx" SG_ 2610127012 OTAPhysPDMtoGWM_ECG 1;
BA_ "U_P702_MY2024_Tx" SG_ 2610127012 OTAPhysPDMtoGWM_ECG 1;
BA_ "GenSigSendType" SG_ 2610127008 OTAPhysDDMtoGWM_ECG 3;
BA_ "ECGUsedRxSignal" SG_ 2610127008 OTAPhysDDMtoGWM_ECG 1;
BA_ "U_P708_MY2023_Rx" SG_ 2610127008 OTAPhysDDMtoGWM_ECG 1;
BA_ "U_CDX74X_MY2024_Rx" SG_ 2610127008 OTAPhysDDMtoGWM_ECG 1;
BA_ "U_P702_MY2024_Rx" SG_ 2610127008 OTAPhysDDMtoGWM_ECG 1;
BA_ "U_V713N_MY2022_Tx" SG_ 2610127008 OTAPhysDDMtoGWM_ECG 1;
BA_ "U_V713AV_MY2022_Tx" SG_ 2610127008 OTAPhysDDMtoGWM_ECG 1;
BA_ "U_P708_MY2023_Tx" SG_ 2610127008 OTAPhysDDMtoGWM_ECG 1;
BA_ "U_P702_MY2024_Tx" SG_ 2610127008 OTAPhysDDMtoGWM_ECG 1;
BA_ "GenSigSendType" SG_ 1814 TesterPhysicalReqGWM_F3 3;
BA_ "ECGUsedRxSignal" SG_ 1814 TesterPhysicalReqGWM_F3 1;
BA_ "U_P708_MY2023_Rx" SG_ 1814 TesterPhysicalReqGWM_F3 1;
BA_ "U_CDX74X_MY2024_Rx" SG_ 1814 TesterPhysicalReqGWM_F3 1;
BA_ "U_V710_MY2023_Rx" SG_ 1814 TesterPhysicalReqGWM_F3 1;
BA_ "U_P702_MY2024_Rx" SG_ 1814 TesterPhysicalReqGWM_F3 1;
BA_ "U_P708_MY2023_Rx" SG_ 1113 TrlrTrgtAcquire_D_Stat 1;
BA_ "U_P702_MY2024_Rx" SG_ 1113 TrlrTrgtAcquire_D_Stat 1;
BA_ "U_P708_MY2023_Tx" SG_ 1113 TrlrTrgtAcquire_D_Stat 1;
BA_ "U_V710_MY2023_Tx" SG_ 1113 TrlrTrgtAcquire_D_Stat 1;
BA_ "U_P702_MY2024_Tx" SG_ 1113 TrlrTrgtAcquire_D_Stat 1;
BA_ "U_P708_MY2023_Rx" SG_ 1113 TrlrAnOffst_An_Calc 1;
BA_ "U_P708_MY2023_Tx" SG_ 1113 TrlrAnOffst_An_Calc 1;
BA_ "U_V710_MY2023_Tx" SG_ 1113 TrlrAnOffst_An_Calc 1;
BA_ "U_P702_MY2024_Tx" SG_ 1113 TrlrAnOffst_An_Calc 1;
BA_ "U_P708_MY2023_Rx" SG_ 1113 TrlrAnOffstDir_D_Calc 1;
BA_ "U_P708_MY2023_Tx" SG_ 1113 TrlrAnOffstDir_D_Calc 1;
BA_ "U_V710_MY2023_Tx" SG_ 1113 TrlrAnOffstDir_D_Calc 1;
BA_ "U_P702_MY2024_Tx" SG_ 1113 TrlrAnOffstDir_D_Calc 1;
BA_ "U_P708_MY2023_Tx" SG_ 1113 TrlrAnCalib_B_Complt 1;
BA_ "U_V710_MY2023_Tx" SG_ 1113 TrlrAnCalib_B_Complt 1;
BA_ "U_P702_MY2024_Tx" SG_ 1113 TrlrAnCalib_B_Complt 1;
BA_ "U_P708_MY2023_Rx" SG_ 1113 TrlrRvrse_D_Stat 1;
BA_ "U_P702_MY2024_Rx" SG_ 1113 TrlrRvrse_D_Stat 1;
BA_ "U_P708_MY2023_Tx" SG_ 1113 TrlrRvrse_D_Stat 1;
BA_ "U_V710_MY2023_Tx" SG_ 1113 TrlrRvrse_D_Stat 1;
BA_ "U_P702_MY2024_Tx" SG_ 1113 TrlrRvrse_D_Stat 1;
BA_ "U_P708_MY2023_Rx" SG_ 1113 TrlrAid_D2_Stat 1;
BA_ "U_P702_MY2024_Rx" SG_ 1113 TrlrAid_D2_Stat 1;
BA_ "U_P708_MY2023_Tx" SG_ 1113 TrlrAid_D2_Stat 1;
BA_ "U_V710_MY2023_Tx" SG_ 1113 TrlrAid_D2_Stat 1;
BA_ "U_P702_MY2024_Tx" SG_ 1113 TrlrAid_D2_Stat 1;
BA_ "U_P708_MY2023_Rx" SG_ 1113 TrlrAidTrgtId_No_Actl 1;
BA_ "U_P702_MY2024_Rx" SG_ 1113 TrlrAidTrgtId_No_Actl 1;
BA_ "U_P708_MY2023_Tx" SG_ 1113 TrlrAidTrgtId_No_Actl 1;
BA_ "U_V710_MY2023_Tx" SG_ 1113 TrlrAidTrgtId_No_Actl 1;
BA_ "U_P702_MY2024_Tx" SG_ 1113 TrlrAidTrgtId_No_Actl 1;
BA_ "U_P708_MY2023_Rx" SG_ 1113 TrlrAid_An3_Actl 1;
BA_ "U_P702_MY2024_Rx" SG_ 1113 TrlrAid_An3_Actl 1;
BA_ "U_P708_MY2023_Tx" SG_ 1113 TrlrAid_An3_Actl 1;
BA_ "U_V710_MY2023_Tx" SG_ 1113 TrlrAid_An3_Actl 1;
BA_ "U_P702_MY2024_Tx" SG_ 1113 TrlrAid_An3_Actl 1;
BA_ "U_P708_MY2023_Rx" SG_ 1113 TrlrAid_AnRate2_Actl 1;
BA_ "U_P702_MY2024_Rx" SG_ 1113 TrlrAid_AnRate2_Actl 1;
BA_ "U_P708_MY2023_Tx" SG_ 1113 TrlrAid_AnRate2_Actl 1;
BA_ "U_V710_MY2023_Tx" SG_ 1113 TrlrAid_AnRate2_Actl 1;
BA_ "U_P702_MY2024_Tx" SG_ 1113 TrlrAid_AnRate2_Actl 1;
BA_ "GenSigStartValue" SG_ 1113 HitchToVehAxle_L_Calc 255;
BA_ "U_P708_MY2023_Rx" SG_ 1113 HitchToVehAxle_L_Calc 1;
BA_ "U_P702_MY2024_Rx" SG_ 1113 HitchToVehAxle_L_Calc 1;
BA_ "U_P708_MY2023_Tx" SG_ 1113 HitchToVehAxle_L_Calc 1;
BA_ "U_V710_MY2023_Tx" SG_ 1113 HitchToVehAxle_L_Calc 1;
BA_ "U_P702_MY2024_Tx" SG_ 1113 HitchToVehAxle_L_Calc 1;
BA_ "U_P708_MY2023_Tx" SG_ 1113 HitchToTrlrAxle_L_Calc2 1;
BA_ "U_V710_MY2023_Tx" SG_ 1113 HitchToTrlrAxle_L_Calc2 1;
BA_ "U_P702_MY2024_Tx" SG_ 1113 HitchToTrlrAxle_L_Calc2 1;
BA_ "U_P708_MY2023_Rx" SG_ 1047 TrlrAnOffst_An2_Calc 1;
BA_ "U_V710_MY2023_Rx" SG_ 1047 TrlrAnOffst_An2_Calc 1;
BA_ "U_P702_MY2024_Rx" SG_ 1047 TrlrAnOffst_An2_Calc 1;
BA_ "U_V713N_MY2022_Tx" SG_ 1047 TrlrAnOffst_An2_Calc 1;
BA_ "U_P708_MY2023_Tx" SG_ 1047 TrlrAnOffst_An2_Calc 1;
BA_ "U_P702_MY2024_Tx" SG_ 1047 TrlrAnOffst_An2_Calc 1;
BA_ "U_P708_MY2023_Rx" SG_ 1047 TrlrAn_An_WarnCalc 1;
BA_ "U_V710_MY2023_Rx" SG_ 1047 TrlrAn_An_WarnCalc 1;
BA_ "U_P702_MY2024_Rx" SG_ 1047 TrlrAn_An_WarnCalc 1;
BA_ "U_V713N_MY2022_Tx" SG_ 1047 TrlrAn_An_WarnCalc 1;
BA_ "U_P708_MY2023_Tx" SG_ 1047 TrlrAn_An_WarnCalc 1;
BA_ "U_P702_MY2024_Tx" SG_ 1047 TrlrAn_An_WarnCalc 1;
BA_ "U_P708_MY2023_Rx" SG_ 1047 TrlrAn_An_MxCalc 1;
BA_ "U_V710_MY2023_Rx" SG_ 1047 TrlrAn_An_MxCalc 1;
BA_ "U_P702_MY2024_Rx" SG_ 1047 TrlrAn_An_MxCalc 1;
BA_ "U_V713N_MY2022_Tx" SG_ 1047 TrlrAn_An_MxCalc 1;
BA_ "U_P708_MY2023_Tx" SG_ 1047 TrlrAn_An_MxCalc 1;
BA_ "U_P702_MY2024_Tx" SG_ 1047 TrlrAn_An_MxCalc 1;
BA_ "U_V713N_MY2022_Tx" SG_ 1047 TrlrAidTrlrId_No_Rq 1;
BA_ "U_P708_MY2023_Tx" SG_ 1047 TrlrAidTrlrId_No_Rq 1;
BA_ "U_P702_MY2024_Tx" SG_ 1047 TrlrAidTrlrId_No_Rq 1;
BA_ "U_P708_MY2023_Rx" SG_ 1047 TrlrAidTrgtId_No_Rq 1;
BA_ "U_V710_MY2023_Rx" SG_ 1047 TrlrAidTrgtId_No_Rq 1;
BA_ "U_P702_MY2024_Rx" SG_ 1047 TrlrAidTrgtId_No_Rq 1;
BA_ "U_V713N_MY2022_Tx" SG_ 1047 TrlrAidTrgtId_No_Rq 1;
BA_ "U_P708_MY2023_Tx" SG_ 1047 TrlrAidTrgtId_No_Rq 1;
BA_ "U_P702_MY2024_Tx" SG_ 1047 TrlrAidTrgtId_No_Rq 1;
BA_ "U_P708_MY2023_Rx" SG_ 1047 TrlrAidSetup_D2_Stat 1;
BA_ "U_V710_MY2023_Rx" SG_ 1047 TrlrAidSetup_D2_Stat 1;
BA_ "U_P702_MY2024_Rx" SG_ 1047 TrlrAidSetup_D2_Stat 1;
BA_ "U_V713N_MY2022_Tx" SG_ 1047 TrlrAidSetup_D2_Stat 1;
BA_ "U_P708_MY2023_Tx" SG_ 1047 TrlrAidSetup_D2_Stat 1;
BA_ "U_P702_MY2024_Tx" SG_ 1047 TrlrAidSetup_D2_Stat 1;
BA_ "GenSigSendType" SG_ 1047 TrlrAidEnbl_D2_Stat 3;
BA_ "U_P708_MY2023_Rx" SG_ 1047 TrlrAidEnbl_D2_Stat 1;
BA_ "U_V710_MY2023_Rx" SG_ 1047 TrlrAidEnbl_D2_Stat 1;
BA_ "U_P702_MY2024_Rx" SG_ 1047 TrlrAidEnbl_D2_Stat 1;
BA_ "U_V713N_MY2022_Tx" SG_ 1047 TrlrAidEnbl_D2_Stat 1;
BA_ "U_P708_MY2023_Tx" SG_ 1047 TrlrAidEnbl_D2_Stat 1;
BA_ "U_P702_MY2024_Tx" SG_ 1047 TrlrAidEnbl_D2_Stat 1;
BA_ "GenSigSendType" SG_ 1047 TrlrAidMsgTxt_D2_Rq 3;
BA_ "U_P708_MY2023_Rx" SG_ 1047 TrlrAidMsgTxt_D2_Rq 1;
BA_ "U_V710_MY2023_Rx" SG_ 1047 TrlrAidMsgTxt_D2_Rq 1;
BA_ "U_P702_MY2024_Rx" SG_ 1047 TrlrAidMsgTxt_D2_Rq 1;
BA_ "U_V713N_MY2022_Tx" SG_ 1047 TrlrAidMsgTxt_D2_Rq 1;
BA_ "U_P708_MY2023_Tx" SG_ 1047 TrlrAidMsgTxt_D2_Rq 1;
BA_ "U_P702_MY2024_Tx" SG_ 1047 TrlrAidMsgTxt_D2_Rq 1;
BA_ "GenSigStartValue" SG_ 1047 EsaOn_B_Stat 1;
BA_ "GenSigSendType" SG_ 1047 EsaOn_B_Stat 3;
BA_ "U_V713N_MY2022_Tx" SG_ 1047 EsaOn_B_Stat 1;
BA_ "U_P708_MY2023_Tx" SG_ 1047 EsaOn_B_Stat 1;
BA_ "U_CDX74X_MY2024_Tx" SG_ 1047 EsaOn_B_Stat 1;
BA_ "U_V710_MY2023_Tx" SG_ 1047 EsaOn_B_Stat 1;
BA_ "U_P702_MY2024_Tx" SG_ 1047 EsaOn_B_Stat 1;
BA_ "U_P708_MY2023_Rx" SG_ 1047 HitchToTrlrAxle_L_Calc 1;
BA_ "U_V710_MY2023_Rx" SG_ 1047 HitchToTrlrAxle_L_Calc 1;
BA_ "U_P702_MY2024_Rx" SG_ 1047 HitchToTrlrAxle_L_Calc 1;
BA_ "U_V713N_MY2022_Tx" SG_ 1047 HitchToTrlrAxle_L_Calc 1;
BA_ "U_P708_MY2023_Tx" SG_ 1047 HitchToTrlrAxle_L_Calc 1;
BA_ "U_P702_MY2024_Tx" SG_ 1047 HitchToTrlrAxle_L_Calc 1;
BA_ "GenSigSendType" SG_ 1047 SelDrvMdeSte_D_Stat 3;
BA_ "U_V713N_MY2022_Tx" SG_ 1047 SelDrvMdeSte_D_Stat 1;
BA_ "U_P708_MY2023_Tx" SG_ 1047 SelDrvMdeSte_D_Stat 1;
BA_ "U_CDX74X_MY2024_Tx" SG_ 1047 SelDrvMdeSte_D_Stat 1;
BA_ "U_V710_MY2023_Tx" SG_ 1047 SelDrvMdeSte_D_Stat 1;
BA_ "U_P702_MY2024_Tx" SG_ 1047 SelDrvMdeSte_D_Stat 1;
BA_ "GenSigStartValue" SG_ 1006 PersIndexIpmb_D_Actl 4;
BA_ "GenSigSendType" SG_ 1006 PersIndexIpmb_D_Actl 3;
BA_ "U_P708_MY2023_Tx" SG_ 1006 PersIndexIpmb_D_Actl 1;
BA_ "U_V710_MY2023_Tx" SG_ 1006 PersIndexIpmb_D_Actl 1;
BA_ "U_P702_MY2024_Tx" SG_ 1006 PersIndexIpmb_D_Actl 1;
BA_ "GenSigSendType" SG_ 1006 FeatNoIpmbActl 3;
BA_ "U_P708_MY2023_Tx" SG_ 1006 FeatNoIpmbActl 1;
BA_ "U_V710_MY2023_Tx" SG_ 1006 FeatNoIpmbActl 1;
BA_ "U_P702_MY2024_Tx" SG_ 1006 FeatNoIpmbActl 1;
BA_ "GenSigSendType" SG_ 1006 FeatConfigIpmbActl 3;
BA_ "U_P708_MY2023_Tx" SG_ 1006 FeatConfigIpmbActl 1;
BA_ "U_V710_MY2023_Tx" SG_ 1006 FeatConfigIpmbActl 1;
BA_ "U_P702_MY2024_Tx" SG_ 1006 FeatConfigIpmbActl 1;
BA_ "GenSigStartValue" SG_ 997 PersTurnSglView_D_Stat 3;
BA_ "GenSigSendType" SG_ 997 PersTurnSglView_D_Stat 3;
BA_ "U_P708_MY2023_Tx" SG_ 997 PersTurnSglView_D_Stat 1;
BA_ "U_V710_MY2023_Tx" SG_ 997 PersTurnSglView_D_Stat 1;
BA_ "U_P702_MY2024_Tx" SG_ 997 PersTurnSglView_D_Stat 1;
BA_ "GenSigStartValue" SG_ 997 PersIndexCcm_D_Actl 4;
BA_ "GenSigSendType" SG_ 997 PersIndexCcm_D_Actl 3;
BA_ "U_P708_MY2023_Tx" SG_ 997 PersIndexCcm_D_Actl 1;
BA_ "U_V710_MY2023_Tx" SG_ 997 PersIndexCcm_D_Actl 1;
BA_ "U_P702_MY2024_Tx" SG_ 997 PersIndexCcm_D_Actl 1;
BA_ "GenSigSendType" SG_ 997 FeatNoCcmActl 3;
BA_ "U_P708_MY2023_Tx" SG_ 997 FeatNoCcmActl 1;
BA_ "U_V710_MY2023_Tx" SG_ 997 FeatNoCcmActl 1;
BA_ "U_P702_MY2024_Tx" SG_ 997 FeatNoCcmActl 1;
BA_ "GenSigSendType" SG_ 997 FeatConfigCcmActl 3;
BA_ "U_P708_MY2023_Tx" SG_ 997 FeatConfigCcmActl 1;
BA_ "U_V710_MY2023_Tx" SG_ 997 FeatConfigCcmActl 1;
BA_ "U_P702_MY2024_Tx" SG_ 997 FeatConfigCcmActl 1;
BA_ "GenSigSendType" SG_ 973 PersCtaSplitView_D_Stat 3;
BA_ "U_P708_MY2023_Tx" SG_ 973 PersCtaSplitView_D_Stat 1;
BA_ "U_V710_MY2023_Tx" SG_ 973 PersCtaSplitView_D_Stat 1;
BA_ "U_P702_MY2024_Tx" SG_ 973 PersCtaSplitView_D_Stat 1;
BA_ "GenSigSendType" SG_ 973 LaSysOffStat_D_Dsply 3;
BA_ "U_P708_MY2023_Tx" SG_ 973 LaSysOffStat_D_Dsply 1;
BA_ "U_V710_MY2023_Tx" SG_ 973 LaSysOffStat_D_Dsply 1;
BA_ "U_P702_MY2024_Tx" SG_ 973 LaSysOffStat_D_Dsply 1;
BA_ "GenSigSendType" SG_ 973 TsrVl2PrmntMsgTxt_D_Rq 3;
BA_ "U_P708_MY2023_Tx" SG_ 973 TsrVl2PrmntMsgTxt_D_Rq 1;
BA_ "U_V710_MY2023_Tx" SG_ 973 TsrVl2PrmntMsgTxt_D_Rq 1;
BA_ "U_P702_MY2024_Tx" SG_ 973 TsrVl2PrmntMsgTxt_D_Rq 1;
BA_ "GenSigSendType" SG_ 973 TsrVl1PrmntMsgTxt_D_Rq 3;
BA_ "U_P708_MY2023_Tx" SG_ 973 TsrVl1PrmntMsgTxt_D_Rq 1;
BA_ "U_V710_MY2023_Tx" SG_ 973 TsrVl1PrmntMsgTxt_D_Rq 1;
BA_ "U_P702_MY2024_Tx" SG_ 973 TsrVl1PrmntMsgTxt_D_Rq 1;
BA_ "GenSigStartValue" SG_ 973 TsrVl2RstrcMsgTxt2_D_Rq 1;
BA_ "GenSigSendType" SG_ 973 TsrVl2RstrcMsgTxt2_D_Rq 3;
BA_ "U_P708_MY2023_Tx" SG_ 973 TsrVl2RstrcMsgTxt2_D_Rq 1;
BA_ "U_V710_MY2023_Tx" SG_ 973 TsrVl2RstrcMsgTxt2_D_Rq 1;
BA_ "U_P702_MY2024_Tx" SG_ 973 TsrVl2RstrcMsgTxt2_D_Rq 1;
BA_ "GenSigStartValue" SG_ 973 TsrVl1RstrcMsgTxt2_D_Rq 1;
BA_ "GenSigSendType" SG_ 973 TsrVl1RstrcMsgTxt2_D_Rq 3;
BA_ "U_P708_MY2023_Tx" SG_ 973 TsrVl1RstrcMsgTxt2_D_Rq 1;
BA_ "U_V710_MY2023_Tx" SG_ 973 TsrVl1RstrcMsgTxt2_D_Rq 1;
BA_ "U_P702_MY2024_Tx" SG_ 973 TsrVl1RstrcMsgTxt2_D_Rq 1;
BA_ "GenSigSendType" SG_ 973 TsrOvtkMsgTxt2_D_Rq 3;
BA_ "U_P708_MY2023_Tx" SG_ 973 TsrOvtkMsgTxt2_D_Rq 1;
BA_ "U_V710_MY2023_Tx" SG_ 973 TsrOvtkMsgTxt2_D_Rq 1;
BA_ "U_P702_MY2024_Tx" SG_ 973 TsrOvtkMsgTxt2_D_Rq 1;
BA_ "GenSigSendType" SG_ 973 WwaWarn_B_Rq 3;
BA_ "U_P708_MY2023_Tx" SG_ 973 WwaWarn_B_Rq 1;
BA_ "U_V710_MY2023_Tx" SG_ 973 WwaWarn_B_Rq 1;
BA_ "U_P702_MY2024_Tx" SG_ 973 WwaWarn_B_Rq 1;
BA_ "GenSigStartValue" SG_ 973 TsrVlUnitMsgTxt_D_Rq 2;
BA_ "GenSigSendType" SG_ 973 TsrVlUnitMsgTxt_D_Rq 3;
BA_ "U_P708_MY2023_Tx" SG_ 973 TsrVlUnitMsgTxt_D_Rq 1;
BA_ "U_V710_MY2023_Tx" SG_ 973 TsrVlUnitMsgTxt_D_Rq 1;
BA_ "U_P702_MY2024_Tx" SG_ 973 TsrVlUnitMsgTxt_D_Rq 1;
BA_ "GenSigStartValue" SG_ 973 TsrVLim2MsgTxt_D_Rq 255;
BA_ "GenSigSendType" SG_ 973 TsrVLim2MsgTxt_D_Rq 3;
BA_ "U_P708_MY2023_Tx" SG_ 973 TsrVLim2MsgTxt_D_Rq 1;
BA_ "U_V710_MY2023_Tx" SG_ 973 TsrVLim2MsgTxt_D_Rq 1;
BA_ "U_P702_MY2024_Tx" SG_ 973 TsrVLim2MsgTxt_D_Rq 1;
BA_ "GenSigStartValue" SG_ 973 TsrVLim1MsgTxt_D_Rq 255;
BA_ "GenSigSendType" SG_ 973 TsrVLim1MsgTxt_D_Rq 3;
BA_ "U_P708_MY2023_Tx" SG_ 973 TsrVLim1MsgTxt_D_Rq 1;
BA_ "U_V710_MY2023_Tx" SG_ 973 TsrVLim1MsgTxt_D_Rq 1;
BA_ "U_P702_MY2024_Tx" SG_ 973 TsrVLim1MsgTxt_D_Rq 1;
BA_ "GenSigSendType" SG_ 973 TsrVl2StatMsgTxt_D_Rq 3;
BA_ "U_P708_MY2023_Tx" SG_ 973 TsrVl2StatMsgTxt_D_Rq 1;
BA_ "U_V710_MY2023_Tx" SG_ 973 TsrVl2StatMsgTxt_D_Rq 1;
BA_ "U_P702_MY2024_Tx" SG_ 973 TsrVl2StatMsgTxt_D_Rq 1;
BA_ "GenSigSendType" SG_ 973 TsrVl2RstrcMsgTxt_D_Rq 3;
BA_ "U_P708_MY2023_Tx" SG_ 973 TsrVl2RstrcMsgTxt_D_Rq 1;
BA_ "U_V710_MY2023_Tx" SG_ 973 TsrVl2RstrcMsgTxt_D_Rq 1;
BA_ "U_P702_MY2024_Tx" SG_ 973 TsrVl2RstrcMsgTxt_D_Rq 1;
BA_ "GenSigSendType" SG_ 973 TsrVl1StatMsgTxt_D_Rq 3;
BA_ "U_P708_MY2023_Tx" SG_ 973 TsrVl1StatMsgTxt_D_Rq 1;
BA_ "U_V710_MY2023_Tx" SG_ 973 TsrVl1StatMsgTxt_D_Rq 1;
BA_ "U_P702_MY2024_Tx" SG_ 973 TsrVl1StatMsgTxt_D_Rq 1;
BA_ "GenSigSendType" SG_ 973 TsrVl1RstrcMsgTxt_D_Rq 3;
BA_ "U_P708_MY2023_Tx" SG_ 973 TsrVl1RstrcMsgTxt_D_Rq 1;
BA_ "U_V710_MY2023_Tx" SG_ 973 TsrVl1RstrcMsgTxt_D_Rq 1;
BA_ "U_P702_MY2024_Tx" SG_ 973 TsrVl1RstrcMsgTxt_D_Rq 1;
BA_ "GenSigSendType" SG_ 973 TsrStatMsgTxt_D_Rq 3;
BA_ "U_P708_MY2023_Tx" SG_ 973 TsrStatMsgTxt_D_Rq 1;
BA_ "U_V710_MY2023_Tx" SG_ 973 TsrStatMsgTxt_D_Rq 1;
BA_ "U_P702_MY2024_Tx" SG_ 973 TsrStatMsgTxt_D_Rq 1;
BA_ "GenSigSendType" SG_ 973 TsrOvtkStatMsgTxt_D_Rq 3;
BA_ "U_P708_MY2023_Tx" SG_ 973 TsrOvtkStatMsgTxt_D_Rq 1;
BA_ "U_V710_MY2023_Tx" SG_ 973 TsrOvtkStatMsgTxt_D_Rq 1;
BA_ "U_P702_MY2024_Tx" SG_ 973 TsrOvtkStatMsgTxt_D_Rq 1;
BA_ "GenSigStartValue" SG_ 973 TsrOvtkMsgTxt_D_Rq 1;
BA_ "GenSigSendType" SG_ 973 TsrOvtkMsgTxt_D_Rq 3;
BA_ "U_P708_MY2023_Tx" SG_ 973 TsrOvtkMsgTxt_D_Rq 1;
BA_ "U_V710_MY2023_Tx" SG_ 973 TsrOvtkMsgTxt_D_Rq 1;
BA_ "U_P702_MY2024_Tx" SG_ 973 TsrOvtkMsgTxt_D_Rq 1;
BA_ "GenSigStartValue" SG_ 973 TsrOswWarnMsgTxt_D_Rq 1;
BA_ "GenSigSendType" SG_ 973 TsrOswWarnMsgTxt_D_Rq 3;
BA_ "U_P708_MY2023_Tx" SG_ 973 TsrOswWarnMsgTxt_D_Rq 1;
BA_ "U_V710_MY2023_Tx" SG_ 973 TsrOswWarnMsgTxt_D_Rq 1;
BA_ "U_P702_MY2024_Tx" SG_ 973 TsrOswWarnMsgTxt_D_Rq 1;
BA_ "GenSigStartValue" SG_ 973 TsrMsgTxt_D_Rq 1;
BA_ "GenSigSendType" SG_ 973 TsrMsgTxt_D_Rq 3;
BA_ "U_P708_MY2023_Tx" SG_ 973 TsrMsgTxt_D_Rq 1;
BA_ "U_V710_MY2023_Tx" SG_ 973 TsrMsgTxt_D_Rq 1;
BA_ "U_P702_MY2024_Tx" SG_ 973 TsrMsgTxt_D_Rq 1;
BA_ "GenSigSendType" SG_ 973 RoadSignRgltry_D_Dsply 3;
BA_ "U_P708_MY2023_Tx" SG_ 973 RoadSignRgltry_D_Dsply 1;
BA_ "U_V710_MY2023_Tx" SG_ 973 RoadSignRgltry_D_Dsply 1;
BA_ "U_P702_MY2024_Tx" SG_ 973 RoadSignRgltry_D_Dsply 1;
BA_ "U_P708_MY2023_Tx" SG_ 976 SuspClkSync_No_Actl 1;
BA_ "U_V710_MY2023_Tx" SG_ 976 SuspClkSync_No_Actl 1;
BA_ "U_P702_MY2024_Tx" SG_ 976 SuspClkSync_No_Actl 1;
BA_ "U_P708_MY2023_Tx" SG_ 976 SrpSigValid_B_Stat 1;
BA_ "U_V710_MY2023_Tx" SG_ 976 SrpSigValid_B_Stat 1;
BA_ "U_P702_MY2024_Tx" SG_ 976 SrpSigValid_B_Stat 1;
BA_ "U_P708_MY2023_Tx" SG_ 976 SrpHghtRight_L_Actl 1;
BA_ "U_V710_MY2023_Tx" SG_ 976 SrpHghtRight_L_Actl 1;
BA_ "U_P702_MY2024_Tx" SG_ 976 SrpHghtRight_L_Actl 1;
BA_ "U_P708_MY2023_Tx" SG_ 976 SrpHghtLeft_L_Actl 1;
BA_ "U_V710_MY2023_Tx" SG_ 976 SrpHghtLeft_L_Actl 1;
BA_ "U_P702_MY2024_Tx" SG_ 976 SrpHghtLeft_L_Actl 1;
BA_ "U_P708_MY2023_Tx" SG_ 976 SrpEventRight_D_Stat 1;
BA_ "U_V710_MY2023_Tx" SG_ 976 SrpEventRight_D_Stat 1;
BA_ "U_P702_MY2024_Tx" SG_ 976 SrpEventRight_D_Stat 1;
BA_ "U_P708_MY2023_Tx" SG_ 976 SrpEventLeft_D_Stat 1;
BA_ "U_V710_MY2023_Tx" SG_ 976 SrpEventLeft_D_Stat 1;
BA_ "U_P702_MY2024_Tx" SG_ 976 SrpEventLeft_D_Stat 1;
BA_ "U_P708_MY2023_Tx" SG_ 976 SrpDistRight_L_Actl 1;
BA_ "U_V710_MY2023_Tx" SG_ 976 SrpDistRight_L_Actl 1;
BA_ "U_P702_MY2024_Tx" SG_ 976 SrpDistRight_L_Actl 1;
BA_ "U_P708_MY2023_Tx" SG_ 976 SrpDistLeft_L_Actl 1;
BA_ "U_V710_MY2023_Tx" SG_ 976 SrpDistLeft_L_Actl 1;
BA_ "U_P702_MY2024_Tx" SG_ 976 SrpDistLeft_L_Actl 1;
BA_ "GenSigStartValue" SG_ 837 VehGvwr_M_Actl 1022;
BA_ "GenSigStartValue" SG_ 837 VehCurb_M_Actl 1022;
BA_ "U_V713N_MY2022_Rx" SG_ 982 LatCtlPathOffst_L_Actl 1;
BA_ "U_P708_MY2023_Rx" SG_ 982 LatCtlPathOffst_L_Actl 1;
BA_ "U_CDX74X_MY2024_Rx" SG_ 982 LatCtlPathOffst_L_Actl 1;
BA_ "U_V710_MY2023_Rx" SG_ 982 LatCtlPathOffst_L_Actl 1;
BA_ "U_P702_MY2024_Rx" SG_ 982 LatCtlPathOffst_L_Actl 1;
BA_ "U_P708_MY2023_Tx" SG_ 982 LatCtlPathOffst_L_Actl 1;
BA_ "U_V710_MY2023_Tx" SG_ 982 LatCtlPathOffst_L_Actl 1;
BA_ "U_P702_MY2024_Tx" SG_ 982 LatCtlPathOffst_L_Actl 1;
BA_ "U_V713N_MY2022_Rx" SG_ 982 LatCtlPath_An_Actl 1;
BA_ "U_P708_MY2023_Rx" SG_ 982 LatCtlPath_An_Actl 1;
BA_ "U_CDX74X_MY2024_Rx" SG_ 982 LatCtlPath_An_Actl 1;
BA_ "U_V710_MY2023_Rx" SG_ 982 LatCtlPath_An_Actl 1;
BA_ "U_P702_MY2024_Rx" SG_ 982 LatCtlPath_An_Actl 1;
BA_ "U_P708_MY2023_Tx" SG_ 982 LatCtlPath_An_Actl 1;
BA_ "U_V710_MY2023_Tx" SG_ 982 LatCtlPath_An_Actl 1;
BA_ "U_P702_MY2024_Tx" SG_ 982 LatCtlPath_An_Actl 1;
BA_ "U_V713N_MY2022_Rx" SG_ 982 LatCtlCurv_No_Actl 1;
BA_ "U_P708_MY2023_Rx" SG_ 982 LatCtlCurv_No_Actl 1;
BA_ "U_CDX74X_MY2024_Rx" SG_ 982 LatCtlCurv_No_Actl 1;
BA_ "U_V710_MY2023_Rx" SG_ 982 LatCtlCurv_No_Actl 1;
BA_ "U_P702_MY2024_Rx" SG_ 982 LatCtlCurv_No_Actl 1;
BA_ "U_P708_MY2023_Tx" SG_ 982 LatCtlCurv_No_Actl 1;
BA_ "U_V710_MY2023_Tx" SG_ 982 LatCtlCurv_No_Actl 1;
BA_ "U_P702_MY2024_Tx" SG_ 982 LatCtlCurv_No_Actl 1;
BA_ "U_V713N_MY2022_Rx" SG_ 982 LatCtlRampType_D_Rq 1;
BA_ "U_P708_MY2023_Rx" SG_ 982 LatCtlRampType_D_Rq 1;
BA_ "U_CDX74X_MY2024_Rx" SG_ 982 LatCtlRampType_D_Rq 1;
BA_ "U_V710_MY2023_Rx" SG_ 982 LatCtlRampType_D_Rq 1;
BA_ "U_P702_MY2024_Rx" SG_ 982 LatCtlRampType_D_Rq 1;
BA_ "U_P708_MY2023_Tx" SG_ 982 LatCtlRampType_D_Rq 1;
BA_ "U_V710_MY2023_Tx" SG_ 982 LatCtlRampType_D_Rq 1;
BA_ "U_P702_MY2024_Tx" SG_ 982 LatCtlRampType_D_Rq 1;
BA_ "U_V713N_MY2022_Rx" SG_ 982 LatCtlPrecision_D_Rq 1;
BA_ "U_P708_MY2023_Rx" SG_ 982 LatCtlPrecision_D_Rq 1;
BA_ "U_CDX74X_MY2024_Rx" SG_ 982 LatCtlPrecision_D_Rq 1;
BA_ "U_V710_MY2023_Rx" SG_ 982 LatCtlPrecision_D_Rq 1;
BA_ "U_P702_MY2024_Rx" SG_ 982 LatCtlPrecision_D_Rq 1;
BA_ "U_P708_MY2023_Tx" SG_ 982 LatCtlPrecision_D_Rq 1;
BA_ "U_V710_MY2023_Tx" SG_ 982 LatCtlPrecision_D_Rq 1;
BA_ "U_P702_MY2024_Tx" SG_ 982 LatCtlPrecision_D_Rq 1;
BA_ "U_P708_MY2023_Rx" SG_ 982 HandsOffCnfm_B_Rq 1;
BA_ "U_CDX74X_MY2024_Rx" SG_ 982 HandsOffCnfm_B_Rq 1;
BA_ "U_V710_MY2023_Rx" SG_ 982 HandsOffCnfm_B_Rq 1;
BA_ "U_P702_MY2024_Rx" SG_ 982 HandsOffCnfm_B_Rq 1;
BA_ "U_P708_MY2023_Tx" SG_ 982 HandsOffCnfm_B_Rq 1;
BA_ "U_V710_MY2023_Tx" SG_ 982 HandsOffCnfm_B_Rq 1;
BA_ "U_P702_MY2024_Tx" SG_ 982 HandsOffCnfm_B_Rq 1;
BA_ "GenSigStartValue" SG_ 982 LatCtlCrv_NoRate2_Actl 1024;
BA_ "U_P708_MY2023_Rx" SG_ 982 LatCtlCrv_NoRate2_Actl 1;
BA_ "U_CDX74X_MY2024_Rx" SG_ 982 LatCtlCrv_NoRate2_Actl 1;
BA_ "U_V710_MY2023_Rx" SG_ 982 LatCtlCrv_NoRate2_Actl 1;
BA_ "U_P702_MY2024_Rx" SG_ 982 LatCtlCrv_NoRate2_Actl 1;
BA_ "U_P708_MY2023_Tx" SG_ 982 LatCtlCrv_NoRate2_Actl 1;
BA_ "U_V710_MY2023_Tx" SG_ 982 LatCtlCrv_NoRate2_Actl 1;
BA_ "U_P702_MY2024_Tx" SG_ 982 LatCtlCrv_NoRate2_Actl 1;
BA_ "MetaData" SG_ 982 LatCtlPath_No_Cnt 1;
BA_ "U_P708_MY2023_Rx" SG_ 982 LatCtlPath_No_Cnt 1;
BA_ "U_CDX74X_MY2024_Rx" SG_ 982 LatCtlPath_No_Cnt 1;
BA_ "U_V710_MY2023_Rx" SG_ 982 LatCtlPath_No_Cnt 1;
BA_ "U_P702_MY2024_Rx" SG_ 982 LatCtlPath_No_Cnt 1;
BA_ "U_P708_MY2023_Tx" SG_ 982 LatCtlPath_No_Cnt 1;
BA_ "U_V710_MY2023_Tx" SG_ 982 LatCtlPath_No_Cnt 1;
BA_ "U_P702_MY2024_Tx" SG_ 982 LatCtlPath_No_Cnt 1;
BA_ "MetaData" SG_ 982 LatCtlPath_No_Cs 1;
BA_ "U_P708_MY2023_Rx" SG_ 982 LatCtlPath_No_Cs 1;
BA_ "U_CDX74X_MY2024_Rx" SG_ 982 LatCtlPath_No_Cs 1;
BA_ "U_V710_MY2023_Rx" SG_ 982 LatCtlPath_No_Cs 1;
BA_ "U_P702_MY2024_Rx" SG_ 982 LatCtlPath_No_Cs 1;
BA_ "U_P708_MY2023_Tx" SG_ 982 LatCtlPath_No_Cs 1;
BA_ "U_V710_MY2023_Tx" SG_ 982 LatCtlPath_No_Cs 1;
BA_ "U_P702_MY2024_Tx" SG_ 982 LatCtlPath_No_Cs 1;
BA_ "U_P708_MY2023_Rx" SG_ 982 LatCtl_D2_Rq 1;
BA_ "U_CDX74X_MY2024_Rx" SG_ 982 LatCtl_D2_Rq 1;
BA_ "U_V710_MY2023_Rx" SG_ 982 LatCtl_D2_Rq 1;
BA_ "U_P702_MY2024_Rx" SG_ 982 LatCtl_D2_Rq 1;
BA_ "U_P708_MY2023_Tx" SG_ 982 LatCtl_D2_Rq 1;
BA_ "U_V710_MY2023_Tx" SG_ 982 LatCtl_D2_Rq 1;
BA_ "U_P702_MY2024_Tx" SG_ 982 LatCtl_D2_Rq 1;
BA_ "GenSigSendType" SG_ 2611070168 PARSEDPhysGWM_ECGtoHCM 3;
BA_ "U_P708_MY2023_Rx" SG_ 2611070168 PARSEDPhysGWM_ECGtoHCM 1;
BA_ "U_CDX74X_MY2024_Rx" SG_ 2611070168 PARSEDPhysGWM_ECGtoHCM 1;
BA_ "U_V710_MY2023_Rx" SG_ 2611070168 PARSEDPhysGWM_ECGtoHCM 1;
BA_ "U_P702_MY2024_Rx" SG_ 2611070168 PARSEDPhysGWM_ECGtoHCM 1;
BA_ "ECGUsedTxSignal" SG_ 2611070168 PARSEDPhysGWM_ECGtoHCM 1;
BA_ "U_P708_MY2023_Tx" SG_ 2611070168 PARSEDPhysGWM_ECGtoHCM 1;
BA_ "U_V710_MY2023_Tx" SG_ 2611070168 PARSEDPhysGWM_ECGtoHCM 1;
BA_ "U_P702_MY2024_Tx" SG_ 2611070168 PARSEDPhysGWM_ECGtoHCM 1;
BA_ "GenSigSendType" SG_ 2611175537 PARSEDPhysHCMtoGWM_ECG 3;
BA_ "ECGUsedRxSignal" SG_ 2611175537 PARSEDPhysHCMtoGWM_ECG 1;
BA_ "U_P708_MY2023_Rx" SG_ 2611175537 PARSEDPhysHCMtoGWM_ECG 1;
BA_ "U_CDX74X_MY2024_Rx" SG_ 2611175537 PARSEDPhysHCMtoGWM_ECG 1;
BA_ "U_V710_MY2023_Rx" SG_ 2611175537 PARSEDPhysHCMtoGWM_ECG 1;
BA_ "U_P702_MY2024_Rx" SG_ 2611175537 PARSEDPhysHCMtoGWM_ECG 1;
BA_ "U_P708_MY2023_Tx" SG_ 2611175537 PARSEDPhysHCMtoGWM_ECG 1;
BA_ "U_CDX74X_MY2024_Tx" SG_ 2611175537 PARSEDPhysHCMtoGWM_ECG 1;
BA_ "U_V710_MY2023_Tx" SG_ 2611175537 PARSEDPhysHCMtoGWM_ECG 1;
BA_ "U_P702_MY2024_Tx" SG_ 2611175537 PARSEDPhysHCMtoGWM_ECG 1;
BA_ "GenSigSendType" SG_ 2610021592 OTAPhysGWM_ECGtoHCM 3;
BA_ "U_P708_MY2023_Rx" SG_ 2610021592 OTAPhysGWM_ECGtoHCM 1;
BA_ "U_CDX74X_MY2024_Rx" SG_ 2610021592 OTAPhysGWM_ECGtoHCM 1;
BA_ "U_V710_MY2023_Rx" SG_ 2610021592 OTAPhysGWM_ECGtoHCM 1;
BA_ "U_P702_MY2024_Rx" SG_ 2610021592 OTAPhysGWM_ECGtoHCM 1;
BA_ "ECGUsedTxSignal" SG_ 2610021592 OTAPhysGWM_ECGtoHCM 1;
BA_ "U_P708_MY2023_Tx" SG_ 2610021592 OTAPhysGWM_ECGtoHCM 1;
BA_ "U_CDX74X_MY2024_Tx" SG_ 2610021592 OTAPhysGWM_ECGtoHCM 1;
BA_ "U_V710_MY2023_Tx" SG_ 2610021592 OTAPhysGWM_ECGtoHCM 1;
BA_ "U_P702_MY2024_Tx" SG_ 2610021592 OTAPhysGWM_ECGtoHCM 1;
BA_ "GenSigSendType" SG_ 2610126961 OTAPhysHCMtoGWM_ECG 3;
BA_ "ECGUsedRxSignal" SG_ 2610126961 OTAPhysHCMtoGWM_ECG 1;
BA_ "U_P708_MY2023_Rx" SG_ 2610126961 OTAPhysHCMtoGWM_ECG 1;
BA_ "U_CDX74X_MY2024_Rx" SG_ 2610126961 OTAPhysHCMtoGWM_ECG 1;
BA_ "U_V710_MY2023_Rx" SG_ 2610126961 OTAPhysHCMtoGWM_ECG 1;
BA_ "U_P702_MY2024_Rx" SG_ 2610126961 OTAPhysHCMtoGWM_ECG 1;
BA_ "U_P708_MY2023_Tx" SG_ 2610126961 OTAPhysHCMtoGWM_ECG 1;
BA_ "U_CDX74X_MY2024_Tx" SG_ 2610126961 OTAPhysHCMtoGWM_ECG 1;
BA_ "U_V710_MY2023_Tx" SG_ 2610126961 OTAPhysHCMtoGWM_ECG 1;
BA_ "U_P702_MY2024_Tx" SG_ 2610126961 OTAPhysHCMtoGWM_ECG 1;
BA_ "GenSigSendType" SG_ 2610975960 PARSEDPhysGWM_ECGtoCCM 3;
BA_ "U_P708_MY2023_Rx" SG_ 2610975960 PARSEDPhysGWM_ECGtoCCM 1;
BA_ "U_V710_MY2023_Rx" SG_ 2610975960 PARSEDPhysGWM_ECGtoCCM 1;
BA_ "U_P702_MY2024_Rx" SG_ 2610975960 PARSEDPhysGWM_ECGtoCCM 1;
BA_ "ECGUsedTxSignal" SG_ 2610975960 PARSEDPhysGWM_ECGtoCCM 1;
BA_ "U_P708_MY2023_Tx" SG_ 2610975960 PARSEDPhysGWM_ECGtoCCM 1;
BA_ "U_P702_MY2024_Tx" SG_ 2610975960 PARSEDPhysGWM_ECGtoCCM 1;
BA_ "GenSigSendType" SG_ 2611175445 PARSEDPhysCCMtoGWM_ECG 3;
BA_ "ECGUsedRxSignal" SG_ 2611175445 PARSEDPhysCCMtoGWM_ECG 1;
BA_ "U_P708_MY2023_Rx" SG_ 2611175445 PARSEDPhysCCMtoGWM_ECG 1;
BA_ "U_V710_MY2023_Rx" SG_ 2611175445 PARSEDPhysCCMtoGWM_ECG 1;
BA_ "U_P702_MY2024_Rx" SG_ 2611175445 PARSEDPhysCCMtoGWM_ECG 1;
BA_ "U_P708_MY2023_Tx" SG_ 2611175445 PARSEDPhysCCMtoGWM_ECG 1;
BA_ "U_V710_MY2023_Tx" SG_ 2611175445 PARSEDPhysCCMtoGWM_ECG 1;
BA_ "U_P702_MY2024_Tx" SG_ 2611175445 PARSEDPhysCCMtoGWM_ECG 1;
BA_ "GenSigSendType" SG_ 2612224021 PARSEDPushCCMtoGWM_ECG 3;
BA_ "ECGUsedRxSignal" SG_ 2612224021 PARSEDPushCCMtoGWM_ECG 1;
BA_ "U_P708_MY2023_Rx" SG_ 2612224021 PARSEDPushCCMtoGWM_ECG 1;
BA_ "U_V710_MY2023_Rx" SG_ 2612224021 PARSEDPushCCMtoGWM_ECG 1;
BA_ "U_P702_MY2024_Rx" SG_ 2612224021 PARSEDPushCCMtoGWM_ECG 1;
BA_ "U_P708_MY2023_Tx" SG_ 2612224021 PARSEDPushCCMtoGWM_ECG 1;
BA_ "U_V710_MY2023_Tx" SG_ 2612224021 PARSEDPushCCMtoGWM_ECG 1;
BA_ "U_P702_MY2024_Tx" SG_ 2612224021 PARSEDPushCCMtoGWM_ECG 1;
BA_ "GenSigSendType" SG_ 2611025112 PARSEDPhysGWM_ECGtoSODCMC 3;
BA_ "U_P708_MY2023_Rx" SG_ 2611025112 PARSEDPhysGWM_ECGtoSODCMC 1;
BA_ "U_V710_MY2023_Rx" SG_ 2611025112 PARSEDPhysGWM_ECGtoSODCMC 1;
BA_ "U_P702_MY2024_Rx" SG_ 2611025112 PARSEDPhysGWM_ECGtoSODCMC 1;
BA_ "ECGUsedTxSignal" SG_ 2611025112 PARSEDPhysGWM_ECGtoSODCMC 1;
BA_ "U_P708_MY2023_Tx" SG_ 2611025112 PARSEDPhysGWM_ECGtoSODCMC 1;
BA_ "U_V710_MY2023_Tx" SG_ 2611025112 PARSEDPhysGWM_ECGtoSODCMC 1;
BA_ "U_P702_MY2024_Tx" SG_ 2611025112 PARSEDPhysGWM_ECGtoSODCMC 1;
BA_ "GenSigSendType" SG_ 2611175493 PARSEDPhysSODCMCtoGWM_ECG 3;
BA_ "ECGUsedRxSignal" SG_ 2611175493 PARSEDPhysSODCMCtoGWM_ECG 1;
BA_ "U_P708_MY2023_Rx" SG_ 2611175493 PARSEDPhysSODCMCtoGWM_ECG 1;
BA_ "U_V710_MY2023_Rx" SG_ 2611175493 PARSEDPhysSODCMCtoGWM_ECG 1;
BA_ "U_P702_MY2024_Rx" SG_ 2611175493 PARSEDPhysSODCMCtoGWM_ECG 1;
BA_ "U_P708_MY2023_Tx" SG_ 2611175493 PARSEDPhysSODCMCtoGWM_ECG 1;
BA_ "U_V710_MY2023_Tx" SG_ 2611175493 PARSEDPhysSODCMCtoGWM_ECG 1;
BA_ "U_P702_MY2024_Tx" SG_ 2611175493 PARSEDPhysSODCMCtoGWM_ECG 1;
BA_ "GenSigSendType" SG_ 2612024536 PARSEDPushFcGWM_ECGtoCCM 3;
BA_ "U_P708_MY2023_Rx" SG_ 2612024536 PARSEDPushFcGWM_ECGtoCCM 1;
BA_ "U_V710_MY2023_Rx" SG_ 2612024536 PARSEDPushFcGWM_ECGtoCCM 1;
BA_ "U_P702_MY2024_Rx" SG_ 2612024536 PARSEDPushFcGWM_ECGtoCCM 1;
BA_ "ECGUsedTxSignal" SG_ 2612024536 PARSEDPushFcGWM_ECGtoCCM 1;
BA_ "U_P708_MY2023_Tx" SG_ 2612024536 PARSEDPushFcGWM_ECGtoCCM 1;
BA_ "U_V710_MY2023_Tx" SG_ 2612024536 PARSEDPushFcGWM_ECGtoCCM 1;
BA_ "U_P702_MY2024_Tx" SG_ 2612024536 PARSEDPushFcGWM_ECGtoCCM 1;
BA_ "GenSigStartValue" SG_ 1200 BrkBstrVac_P_Actl 127;
BA_ "U_V713N_MY2022_Rx" SG_ 1200 YawStabilityIndex 1;
BA_ "U_P708_MY2023_Rx" SG_ 1200 YawStabilityIndex 1;
BA_ "U_CDX74X_MY2024_Rx" SG_ 1200 YawStabilityIndex 1;
BA_ "U_V710_MY2023_Rx" SG_ 1200 YawStabilityIndex 1;
BA_ "U_P702_MY2024_Rx" SG_ 1200 YawStabilityIndex 1;
BA_ "U_V713N_MY2022_Rx" SG_ 1200 BrkTot_Tq_RqDrv 1;
BA_ "U_P708_MY2023_Rx" SG_ 1200 BrkTot_Tq_RqDrv 1;
BA_ "U_CDX74X_MY2024_Rx" SG_ 1200 BrkTot_Tq_RqDrv 1;
BA_ "U_V710_MY2023_Rx" SG_ 1200 BrkTot_Tq_RqDrv 1;
BA_ "U_P702_MY2024_Rx" SG_ 1200 BrkTot_Tq_RqDrv 1;
BA_ "MetaData" SG_ 1200 BrkTotTqRqDrv_No_Cnt 1;
BA_ "MetaData" SG_ 1200 BrkTotTqRqDrv_No_Cs 1;
BA_ "U_P708_MY2023_Rx" SG_ 1200 BrkHold_D_Stat 1;
BA_ "U_V710_MY2023_Rx" SG_ 1200 BrkHold_D_Stat 1;
BA_ "U_P702_MY2024_Rx" SG_ 1200 BrkHold_D_Stat 1;
BA_ "U_P708_MY2023_Rx" SG_ 1093 TrlrBrkActCnnct_B_Actl 1;
BA_ "U_V710_MY2023_Rx" SG_ 1093 TrlrBrkActCnnct_B_Actl 1;
BA_ "U_P702_MY2024_Rx" SG_ 1093 TrlrBrkActCnnct_B_Actl 1;
BA_ "U_P708_MY2023_Rx" SG_ 1093 TrlrBrkCtl_B_Falt 1;
BA_ "U_V710_MY2023_Rx" SG_ 1093 TrlrBrkCtl_B_Falt 1;
BA_ "U_P702_MY2024_Rx" SG_ 1093 TrlrBrkCtl_B_Falt 1;
BA_ "U_P708_MY2023_Rx" SG_ 1093 TrlrBrkActCirct_B_Falt 1;
BA_ "U_V710_MY2023_Rx" SG_ 1093 TrlrBrkActCirct_B_Falt 1;
BA_ "U_P702_MY2024_Rx" SG_ 1093 TrlrBrkActCirct_B_Falt 1;
BA_ "GenSigSendType" SG_ 1787 TesterPhysicalResSODCMD 3;
BA_ "U_P708_MY2023_Tx" SG_ 1787 TesterPhysicalResSODCMD 1;
BA_ "U_V710_MY2023_Tx" SG_ 1787 TesterPhysicalResSODCMD 1;
BA_ "U_P702_MY2024_Tx" SG_ 1787 TesterPhysicalResSODCMD 1;
BA_ "GenSigSendType" SG_ 1779 TesterPhysicalReqSODCMD 3;
BA_ "U_P708_MY2023_Rx" SG_ 1779 TesterPhysicalReqSODCMD 1;
BA_ "U_V710_MY2023_Rx" SG_ 1779 TesterPhysicalReqSODCMD 1;
BA_ "U_P702_MY2024_Rx" SG_ 1779 TesterPhysicalReqSODCMD 1;
BA_ "GenSigSendType" SG_ 1786 TesterPhysicalResSODCMC 3;
BA_ "U_P708_MY2023_Tx" SG_ 1786 TesterPhysicalResSODCMC 1;
BA_ "U_V710_MY2023_Tx" SG_ 1786 TesterPhysicalResSODCMC 1;
BA_ "U_P702_MY2024_Tx" SG_ 1786 TesterPhysicalResSODCMC 1;
BA_ "GenSigSendType" SG_ 935 CtaAlrtRight2_D_Stat 3;
BA_ "U_P708_MY2023_Tx" SG_ 935 CtaAlrtRight2_D_Stat 1;
BA_ "U_V710_MY2023_Tx" SG_ 935 CtaAlrtRight2_D_Stat 1;
BA_ "U_P702_MY2024_Tx" SG_ 935 CtaAlrtRight2_D_Stat 1;
BA_ "GenSigSendType" SG_ 935 BttRight_D_Stat 3;
BA_ "U_P708_MY2023_Tx" SG_ 935 BttRight_D_Stat 1;
BA_ "U_V710_MY2023_Tx" SG_ 935 BttRight_D_Stat 1;
BA_ "U_P702_MY2024_Tx" SG_ 935 BttRight_D_Stat 1;
BA_ "GenSigSendType" SG_ 935 BttRight_D_RqDrv 3;
BA_ "U_P708_MY2023_Tx" SG_ 935 BttRight_D_RqDrv 1;
BA_ "U_V710_MY2023_Tx" SG_ 935 BttRight_D_RqDrv 1;
BA_ "U_P702_MY2024_Tx" SG_ 935 BttRight_D_RqDrv 1;
BA_ "GenSigSendType" SG_ 935 CtaBrkRightMsgTxt_B_Rq 3;
BA_ "U_P708_MY2023_Tx" SG_ 935 CtaBrkRightMsgTxt_B_Rq 1;
BA_ "U_V710_MY2023_Tx" SG_ 935 CtaBrkRightMsgTxt_B_Rq 1;
BA_ "U_P702_MY2024_Tx" SG_ 935 CtaBrkRightMsgTxt_B_Rq 1;
BA_ "GenSigSendType" SG_ 935 CtaRightBrkEnbl_B_Rq 3;
BA_ "U_P708_MY2023_Tx" SG_ 935 CtaRightBrkEnbl_B_Rq 1;
BA_ "U_V710_MY2023_Tx" SG_ 935 CtaRightBrkEnbl_B_Rq 1;
BA_ "U_P702_MY2024_Tx" SG_ 935 CtaRightBrkEnbl_B_Rq 1;
BA_ "GenSigSendType" SG_ 935 CtaRightBrkDecel_B_Rq 3;
BA_ "U_P708_MY2023_Tx" SG_ 935 CtaRightBrkDecel_B_Rq 1;
BA_ "U_V710_MY2023_Tx" SG_ 935 CtaRightBrkDecel_B_Rq 1;
BA_ "U_P702_MY2024_Tx" SG_ 935 CtaRightBrkDecel_B_Rq 1;
BA_ "GenSigStartValue" SG_ 935 Side_Detect_R_Illum 100;
BA_ "U_P708_MY2023_Rx" SG_ 935 Side_Detect_R_Illum 1;
BA_ "U_P702_MY2024_Rx" SG_ 935 Side_Detect_R_Illum 1;
BA_ "U_P708_MY2023_Tx" SG_ 935 Side_Detect_R_Illum 1;
BA_ "U_V710_MY2023_Tx" SG_ 935 Side_Detect_R_Illum 1;
BA_ "U_P702_MY2024_Tx" SG_ 935 Side_Detect_R_Illum 1;
BA_ "GenSigSendType" SG_ 935 CtaSnsRight_D_Stat 3;
BA_ "U_P708_MY2023_Tx" SG_ 935 CtaSnsRight_D_Stat 1;
BA_ "U_V710_MY2023_Tx" SG_ 935 CtaSnsRight_D_Stat 1;
BA_ "U_P702_MY2024_Tx" SG_ 935 CtaSnsRight_D_Stat 1;
BA_ "GenSigSendType" SG_ 935 CtaAlrtRight_D_Stat 3;
BA_ "U_P708_MY2023_Rx" SG_ 935 CtaAlrtRight_D_Stat 1;
BA_ "U_P702_MY2024_Rx" SG_ 935 CtaAlrtRight_D_Stat 1;
BA_ "U_P708_MY2023_Tx" SG_ 935 CtaAlrtRight_D_Stat 1;
BA_ "U_V710_MY2023_Tx" SG_ 935 CtaAlrtRight_D_Stat 1;
BA_ "U_P702_MY2024_Tx" SG_ 935 CtaAlrtRight_D_Stat 1;
BA_ "GenSigSendType" SG_ 935 CtaRight_D_Stat 3;
BA_ "U_P708_MY2023_Tx" SG_ 935 CtaRight_D_Stat 1;
BA_ "U_V710_MY2023_Tx" SG_ 935 CtaRight_D_Stat 1;
BA_ "U_P702_MY2024_Tx" SG_ 935 CtaRight_D_Stat 1;
BA_ "GenSigStartValue" SG_ 935 SodRight_D_Stat 2;
BA_ "GenSigSendType" SG_ 935 SodRight_D_Stat 3;
BA_ "U_P708_MY2023_Tx" SG_ 935 SodRight_D_Stat 1;
BA_ "U_V710_MY2023_Tx" SG_ 935 SodRight_D_Stat 1;
BA_ "U_P702_MY2024_Tx" SG_ 935 SodRight_D_Stat 1;
BA_ "GenSigSendType" SG_ 935 SodSnsRight_D_Stat 3;
BA_ "U_P708_MY2023_Rx" SG_ 935 SodSnsRight_D_Stat 1;
BA_ "U_P702_MY2024_Rx" SG_ 935 SodSnsRight_D_Stat 1;
BA_ "U_P708_MY2023_Tx" SG_ 935 SodSnsRight_D_Stat 1;
BA_ "U_V710_MY2023_Tx" SG_ 935 SodSnsRight_D_Stat 1;
BA_ "U_P702_MY2024_Tx" SG_ 935 SodSnsRight_D_Stat 1;
BA_ "GenSigSendType" SG_ 935 SodAlrtRight_D_Stat 3;
BA_ "U_P708_MY2023_Rx" SG_ 935 SodAlrtRight_D_Stat 1;
BA_ "U_P702_MY2024_Rx" SG_ 935 SodAlrtRight_D_Stat 1;
BA_ "U_P708_MY2023_Tx" SG_ 935 SodAlrtRight_D_Stat 1;
BA_ "U_V710_MY2023_Tx" SG_ 935 SodAlrtRight_D_Stat 1;
BA_ "U_P702_MY2024_Tx" SG_ 935 SodAlrtRight_D_Stat 1;
BA_ "GenSigSendType" SG_ 935 SodDetctRight_D_Stat 3;
BA_ "U_P708_MY2023_Tx" SG_ 935 SodDetctRight_D_Stat 1;
BA_ "U_V710_MY2023_Tx" SG_ 935 SodDetctRight_D_Stat 1;
BA_ "U_P702_MY2024_Tx" SG_ 935 SodDetctRight_D_Stat 1;
BA_ "GenSigStartValue" SG_ 935 SodWarnRight_Prd_Rq 14;
BA_ "U_P708_MY2023_Rx" SG_ 935 SodWarnRight_Prd_Rq 1;
BA_ "U_P702_MY2024_Rx" SG_ 935 SodWarnRight_Prd_Rq 1;
BA_ "U_P708_MY2023_Tx" SG_ 935 SodWarnRight_Prd_Rq 1;
BA_ "U_V710_MY2023_Tx" SG_ 935 SodWarnRight_Prd_Rq 1;
BA_ "U_P702_MY2024_Tx" SG_ 935 SodWarnRight_Prd_Rq 1;
BA_ "U_P708_MY2023_Rx" SG_ 1087 FapLcInhbt_B_Rq 1;
BA_ "U_V710_MY2023_Rx" SG_ 1087 FapLcInhbt_B_Rq 1;
BA_ "U_P702_MY2024_Rx" SG_ 1087 FapLcInhbt_B_Rq 1;
BA_ "U_P708_MY2023_Rx" SG_ 1087 FapLcObstcl_B_Stat 1;
BA_ "U_V710_MY2023_Rx" SG_ 1087 FapLcObstcl_B_Stat 1;
BA_ "U_P702_MY2024_Rx" SG_ 1087 FapLcObstcl_B_Stat 1;
BA_ "U_P708_MY2023_Rx" SG_ 1087 FapLcMaxGrdInhbt_B_Stat 1;
BA_ "U_V710_MY2023_Rx" SG_ 1087 FapLcMaxGrdInhbt_B_Stat 1;
BA_ "U_P702_MY2024_Rx" SG_ 1087 FapLcMaxGrdInhbt_B_Stat 1;
BA_ "U_P708_MY2023_Rx" SG_ 1087 FapLcMaxGrdAbrt_B_Stat 1;
BA_ "U_V710_MY2023_Rx" SG_ 1087 FapLcMaxGrdAbrt_B_Stat 1;
BA_ "U_P702_MY2024_Rx" SG_ 1087 FapLcMaxGrdAbrt_B_Stat 1;
BA_ "U_P708_MY2023_Rx" SG_ 1087 FapLcActv_B_Stat 1;
BA_ "U_V710_MY2023_Rx" SG_ 1087 FapLcActv_B_Stat 1;
BA_ "U_P702_MY2024_Rx" SG_ 1087 FapLcActv_B_Stat 1;
BA_ "U_P708_MY2023_Rx" SG_ 1087 AdasLcObtclAbrt_B_Stat 1;
BA_ "U_V710_MY2023_Rx" SG_ 1087 AdasLcObtclAbrt_B_Stat 1;
BA_ "U_P702_MY2024_Rx" SG_ 1087 AdasLcObtclAbrt_B_Stat 1;
BA_ "GenSigStartValue" SG_ 1076 W2S_LAMP_OK 1;
BA_ "GenSigStartValue" SG_ 1076 Veh_V_CompLimMx 4093;
BA_ "U_P708_MY2023_Rx" SG_ 1076 DISPLAY_SPEED_SCALING 1;
BA_ "U_V710_MY2023_Rx" SG_ 1076 DISPLAY_SPEED_SCALING 1;
BA_ "U_P702_MY2024_Rx" SG_ 1076 DISPLAY_SPEED_SCALING 1;
BA_ "U_P708_MY2023_Rx" SG_ 1076 DISPLAY_SPEED_OFFSET 1;
BA_ "U_V710_MY2023_Rx" SG_ 1076 DISPLAY_SPEED_OFFSET 1;
BA_ "U_P702_MY2024_Rx" SG_ 1076 DISPLAY_SPEED_OFFSET 1;
BA_ "GenSigSendType" SG_ 2611026136 PARSEDPhysGWM_ECGtoSODCMD 3;
BA_ "U_P708_MY2023_Rx" SG_ 2611026136 PARSEDPhysGWM_ECGtoSODCMD 1;
BA_ "U_V710_MY2023_Rx" SG_ 2611026136 PARSEDPhysGWM_ECGtoSODCMD 1;
BA_ "U_P702_MY2024_Rx" SG_ 2611026136 PARSEDPhysGWM_ECGtoSODCMD 1;
BA_ "ECGUsedTxSignal" SG_ 2611026136 PARSEDPhysGWM_ECGtoSODCMD 1;
BA_ "U_P708_MY2023_Tx" SG_ 2611026136 PARSEDPhysGWM_ECGtoSODCMD 1;
BA_ "U_V710_MY2023_Tx" SG_ 2611026136 PARSEDPhysGWM_ECGtoSODCMD 1;
BA_ "U_P702_MY2024_Tx" SG_ 2611026136 PARSEDPhysGWM_ECGtoSODCMD 1;
BA_ "GenSigSendType" SG_ 2611175494 PARSEDPhysSODCMDtoGWM_ECG 3;
BA_ "ECGUsedRxSignal" SG_ 2611175494 PARSEDPhysSODCMDtoGWM_ECG 1;
BA_ "U_P708_MY2023_Rx" SG_ 2611175494 PARSEDPhysSODCMDtoGWM_ECG 1;
BA_ "U_V710_MY2023_Rx" SG_ 2611175494 PARSEDPhysSODCMDtoGWM_ECG 1;
BA_ "U_P702_MY2024_Rx" SG_ 2611175494 PARSEDPhysSODCMDtoGWM_ECG 1;
BA_ "U_P708_MY2023_Tx" SG_ 2611175494 PARSEDPhysSODCMDtoGWM_ECG 1;
BA_ "U_V710_MY2023_Tx" SG_ 2611175494 PARSEDPhysSODCMDtoGWM_ECG 1;
BA_ "U_P702_MY2024_Tx" SG_ 2611175494 PARSEDPhysSODCMDtoGWM_ECG 1;
BA_ "GenSigSendType" SG_ 2611054808 PARSEDPhysGWM_ECGtoSODL 3;
BA_ "U_P708_MY2023_Rx" SG_ 2611054808 PARSEDPhysGWM_ECGtoSODL 1;
BA_ "U_V710_MY2023_Rx" SG_ 2611054808 PARSEDPhysGWM_ECGtoSODL 1;
BA_ "U_P702_MY2024_Rx" SG_ 2611054808 PARSEDPhysGWM_ECGtoSODL 1;
BA_ "ECGUsedTxSignal" SG_ 2611054808 PARSEDPhysGWM_ECGtoSODL 1;
BA_ "U_P708_MY2023_Tx" SG_ 2611054808 PARSEDPhysGWM_ECGtoSODL 1;
BA_ "U_P702_MY2024_Tx" SG_ 2611054808 PARSEDPhysGWM_ECGtoSODL 1;
BA_ "GenSigSendType" SG_ 2611175523 PARSEDPhysSODRtoGWM_ECG 3;
BA_ "ECGUsedRxSignal" SG_ 2611175523 PARSEDPhysSODRtoGWM_ECG 1;
BA_ "U_P708_MY2023_Rx" SG_ 2611175523 PARSEDPhysSODRtoGWM_ECG 1;
BA_ "U_P702_MY2024_Rx" SG_ 2611175523 PARSEDPhysSODRtoGWM_ECG 1;
BA_ "U_P708_MY2023_Tx" SG_ 2611175523 PARSEDPhysSODRtoGWM_ECG 1;
BA_ "U_V710_MY2023_Tx" SG_ 2611175523 PARSEDPhysSODRtoGWM_ECG 1;
BA_ "U_P702_MY2024_Tx" SG_ 2611175523 PARSEDPhysSODRtoGWM_ECG 1;
BA_ "GenSigSendType" SG_ 2611055832 PARSEDPhysGWM_ECGtoSODR 3;
BA_ "U_P708_MY2023_Rx" SG_ 2611055832 PARSEDPhysGWM_ECGtoSODR 1;
BA_ "U_V710_MY2023_Rx" SG_ 2611055832 PARSEDPhysGWM_ECGtoSODR 1;
BA_ "U_P702_MY2024_Rx" SG_ 2611055832 PARSEDPhysGWM_ECGtoSODR 1;
BA_ "ECGUsedTxSignal" SG_ 2611055832 PARSEDPhysGWM_ECGtoSODR 1;
BA_ "U_P708_MY2023_Tx" SG_ 2611055832 PARSEDPhysGWM_ECGtoSODR 1;
BA_ "U_P702_MY2024_Tx" SG_ 2611055832 PARSEDPhysGWM_ECGtoSODR 1;
BA_ "GenSigSendType" SG_ 2611175522 PARSEDPhysSODLtoGWM_ECG 3;
BA_ "ECGUsedRxSignal" SG_ 2611175522 PARSEDPhysSODLtoGWM_ECG 1;
BA_ "U_P708_MY2023_Rx" SG_ 2611175522 PARSEDPhysSODLtoGWM_ECG 1;
BA_ "U_P702_MY2024_Rx" SG_ 2611175522 PARSEDPhysSODLtoGWM_ECG 1;
BA_ "U_P708_MY2023_Tx" SG_ 2611175522 PARSEDPhysSODLtoGWM_ECG 1;
BA_ "U_V710_MY2023_Tx" SG_ 2611175522 PARSEDPhysSODLtoGWM_ECG 1;
BA_ "U_P702_MY2024_Tx" SG_ 2611175522 PARSEDPhysSODLtoGWM_ECG 1;
BA_ "GenSigSendType" SG_ 2609927384 OTAPhysGWM_ECGtoCCM 3;
BA_ "U_P708_MY2023_Rx" SG_ 2609927384 OTAPhysGWM_ECGtoCCM 1;
BA_ "U_V710_MY2023_Rx" SG_ 2609927384 OTAPhysGWM_ECGtoCCM 1;
BA_ "U_P702_MY2024_Rx" SG_ 2609927384 OTAPhysGWM_ECGtoCCM 1;
BA_ "ECGUsedTxSignal" SG_ 2609927384 OTAPhysGWM_ECGtoCCM 1;
BA_ "U_P708_MY2023_Tx" SG_ 2609927384 OTAPhysGWM_ECGtoCCM 1;
BA_ "U_V710_MY2023_Tx" SG_ 2609927384 OTAPhysGWM_ECGtoCCM 1;
BA_ "U_P702_MY2024_Tx" SG_ 2609927384 OTAPhysGWM_ECGtoCCM 1;
BA_ "GenSigSendType" SG_ 2610126869 OTAPhysCCMtoGWM_ECG 3;
BA_ "ECGUsedRxSignal" SG_ 2610126869 OTAPhysCCMtoGWM_ECG 1;
BA_ "U_P708_MY2023_Rx" SG_ 2610126869 OTAPhysCCMtoGWM_ECG 1;
BA_ "U_V710_MY2023_Rx" SG_ 2610126869 OTAPhysCCMtoGWM_ECG 1;
BA_ "U_P702_MY2024_Rx" SG_ 2610126869 OTAPhysCCMtoGWM_ECG 1;
BA_ "U_P708_MY2023_Tx" SG_ 2610126869 OTAPhysCCMtoGWM_ECG 1;
BA_ "U_V710_MY2023_Tx" SG_ 2610126869 OTAPhysCCMtoGWM_ECG 1;
BA_ "U_P702_MY2024_Tx" SG_ 2610126869 OTAPhysCCMtoGWM_ECG 1;
BA_ "GenSigSendType" SG_ 2609976536 OTAPhysGWM_ECGtoSODCMC 3;
BA_ "U_P708_MY2023_Rx" SG_ 2609976536 OTAPhysGWM_ECGtoSODCMC 1;
BA_ "U_V710_MY2023_Rx" SG_ 2609976536 OTAPhysGWM_ECGtoSODCMC 1;
BA_ "U_P702_MY2024_Rx" SG_ 2609976536 OTAPhysGWM_ECGtoSODCMC 1;
BA_ "ECGUsedTxSignal" SG_ 2609976536 OTAPhysGWM_ECGtoSODCMC 1;
BA_ "U_P708_MY2023_Tx" SG_ 2609976536 OTAPhysGWM_ECGtoSODCMC 1;
BA_ "U_V710_MY2023_Tx" SG_ 2609976536 OTAPhysGWM_ECGtoSODCMC 1;
BA_ "U_P702_MY2024_Tx" SG_ 2609976536 OTAPhysGWM_ECGtoSODCMC 1;
BA_ "GenSigSendType" SG_ 2610126917 OTAPhysSODCMCtoGWM_ECG 3;
BA_ "ECGUsedRxSignal" SG_ 2610126917 OTAPhysSODCMCtoGWM_ECG 1;
BA_ "U_P708_MY2023_Rx" SG_ 2610126917 OTAPhysSODCMCtoGWM_ECG 1;
BA_ "U_V710_MY2023_Rx" SG_ 2610126917 OTAPhysSODCMCtoGWM_ECG 1;
BA_ "U_P702_MY2024_Rx" SG_ 2610126917 OTAPhysSODCMCtoGWM_ECG 1;
BA_ "U_P708_MY2023_Tx" SG_ 2610126917 OTAPhysSODCMCtoGWM_ECG 1;
BA_ "U_V710_MY2023_Tx" SG_ 2610126917 OTAPhysSODCMCtoGWM_ECG 1;
BA_ "U_P702_MY2024_Tx" SG_ 2610126917 OTAPhysSODCMCtoGWM_ECG 1;
BA_ "GenSigSendType" SG_ 2609977560 OTAPhysGWM_ECGtoSODCMD 3;
BA_ "U_P708_MY2023_Rx" SG_ 2609977560 OTAPhysGWM_ECGtoSODCMD 1;
BA_ "U_V710_MY2023_Rx" SG_ 2609977560 OTAPhysGWM_ECGtoSODCMD 1;
BA_ "U_P702_MY2024_Rx" SG_ 2609977560 OTAPhysGWM_ECGtoSODCMD 1;
BA_ "ECGUsedTxSignal" SG_ 2609977560 OTAPhysGWM_ECGtoSODCMD 1;
BA_ "U_P708_MY2023_Tx" SG_ 2609977560 OTAPhysGWM_ECGtoSODCMD 1;
BA_ "U_V710_MY2023_Tx" SG_ 2609977560 OTAPhysGWM_ECGtoSODCMD 1;
BA_ "U_P702_MY2024_Tx" SG_ 2609977560 OTAPhysGWM_ECGtoSODCMD 1;
BA_ "GenSigSendType" SG_ 2610126918 OTAPhysSODCMDtoGWM_ECG 3;
BA_ "ECGUsedRxSignal" SG_ 2610126918 OTAPhysSODCMDtoGWM_ECG 1;
BA_ "U_P708_MY2023_Rx" SG_ 2610126918 OTAPhysSODCMDtoGWM_ECG 1;
BA_ "U_V710_MY2023_Rx" SG_ 2610126918 OTAPhysSODCMDtoGWM_ECG 1;
BA_ "U_P702_MY2024_Rx" SG_ 2610126918 OTAPhysSODCMDtoGWM_ECG 1;
BA_ "U_P708_MY2023_Tx" SG_ 2610126918 OTAPhysSODCMDtoGWM_ECG 1;
BA_ "U_V710_MY2023_Tx" SG_ 2610126918 OTAPhysSODCMDtoGWM_ECG 1;
BA_ "U_P702_MY2024_Tx" SG_ 2610126918 OTAPhysSODCMDtoGWM_ECG 1;
BA_ "GenSigSendType" SG_ 2610007256 OTAPhysGWM_ECGtoSODR 3;
BA_ "U_P708_MY2023_Rx" SG_ 2610007256 OTAPhysGWM_ECGtoSODR 1;
BA_ "U_V710_MY2023_Rx" SG_ 2610007256 OTAPhysGWM_ECGtoSODR 1;
BA_ "U_P702_MY2024_Rx" SG_ 2610007256 OTAPhysGWM_ECGtoSODR 1;
BA_ "ECGUsedTxSignal" SG_ 2610007256 OTAPhysGWM_ECGtoSODR 1;
BA_ "U_P708_MY2023_Tx" SG_ 2610007256 OTAPhysGWM_ECGtoSODR 1;
BA_ "U_P702_MY2024_Tx" SG_ 2610007256 OTAPhysGWM_ECGtoSODR 1;
BA_ "GenSigSendType" SG_ 2610126947 OTAPhysSODRtoGWM_ECG 3;
BA_ "ECGUsedRxSignal" SG_ 2610126947 OTAPhysSODRtoGWM_ECG 1;
BA_ "U_P708_MY2023_Rx" SG_ 2610126947 OTAPhysSODRtoGWM_ECG 1;
BA_ "U_P702_MY2024_Rx" SG_ 2610126947 OTAPhysSODRtoGWM_ECG 1;
BA_ "U_P708_MY2023_Tx" SG_ 2610126947 OTAPhysSODRtoGWM_ECG 1;
BA_ "U_V710_MY2023_Tx" SG_ 2610126947 OTAPhysSODRtoGWM_ECG 1;
BA_ "U_P702_MY2024_Tx" SG_ 2610126947 OTAPhysSODRtoGWM_ECG 1;
BA_ "GenSigSendType" SG_ 1238 TjaCanclMsgTxt_D_Dsply 3;
BA_ "ECGUsedRxSignal" SG_ 1238 TjaCanclMsgTxt_D_Dsply 1;
BA_ "U_P708_MY2023_Rx" SG_ 1238 TjaCanclMsgTxt_D_Dsply 1;
BA_ "U_CDX74X_MY2024_Rx" SG_ 1238 TjaCanclMsgTxt_D_Dsply 1;
BA_ "U_P702_MY2024_Rx" SG_ 1238 TjaCanclMsgTxt_D_Dsply 1;
BA_ "U_P708_MY2023_Tx" SG_ 1238 TjaCanclMsgTxt_D_Dsply 1;
BA_ "U_V710_MY2023_Tx" SG_ 1238 TjaCanclMsgTxt_D_Dsply 1;
BA_ "U_P702_MY2024_Tx" SG_ 1238 TjaCanclMsgTxt_D_Dsply 1;
BA_ "GenSigSendType" SG_ 1238 GfhbMnu_D_Rq 3;
BA_ "U_P708_MY2023_Tx" SG_ 1238 GfhbMnu_D_Rq 1;
BA_ "U_V710_MY2023_Tx" SG_ 1238 GfhbMnu_D_Rq 1;
BA_ "U_P702_MY2024_Tx" SG_ 1238 GfhbMnu_D_Rq 1;
BA_ "GenSigSendType" SG_ 1238 AhbcMnu_D_Rq 3;
BA_ "U_P708_MY2023_Tx" SG_ 1238 AhbcMnu_D_Rq 1;
BA_ "U_V710_MY2023_Tx" SG_ 1238 AhbcMnu_D_Rq 1;
BA_ "U_P702_MY2024_Tx" SG_ 1238 AhbcMnu_D_Rq 1;
BA_ "GenSigSendType" SG_ 1238 TjaLaneBias_D_Stat 3;
BA_ "U_P708_MY2023_Tx" SG_ 1238 TjaLaneBias_D_Stat 1;
BA_ "U_V710_MY2023_Tx" SG_ 1238 TjaLaneBias_D_Stat 1;
BA_ "U_P702_MY2024_Tx" SG_ 1238 TjaLaneBias_D_Stat 1;
BA_ "GenSigSendType" SG_ 1238 TjaLaneBiasEnbl_D_Stat 3;
BA_ "U_P708_MY2023_Tx" SG_ 1238 TjaLaneBiasEnbl_D_Stat 1;
BA_ "U_V710_MY2023_Tx" SG_ 1238 TjaLaneBiasEnbl_D_Stat 1;
BA_ "U_P702_MY2024_Tx" SG_ 1238 TjaLaneBiasEnbl_D_Stat 1;
BA_ "U_P708_MY2023_Tx" SG_ 1238 IaccVAdjReas_D_Dsply 1;
BA_ "U_V710_MY2023_Tx" SG_ 1238 IaccVAdjReas_D_Dsply 1;
BA_ "U_P702_MY2024_Tx" SG_ 1238 IaccVAdjReas_D_Dsply 1;
BA_ "GenSigSendType" SG_ 1238 IaccVAdjLim_No_Actl 3;
BA_ "U_P708_MY2023_Tx" SG_ 1238 IaccVAdjLim_No_Actl 1;
BA_ "U_V710_MY2023_Tx" SG_ 1238 IaccVAdjLim_No_Actl 1;
BA_ "U_P702_MY2024_Tx" SG_ 1238 IaccVAdjLim_No_Actl 1;
BA_ "GenSigSendType" SG_ 2612073688 PARSEDPushFcECGtoSODCMC 3;
BA_ "U_P708_MY2023_Rx" SG_ 2612073688 PARSEDPushFcECGtoSODCMC 1;
BA_ "U_V710_MY2023_Rx" SG_ 2612073688 PARSEDPushFcECGtoSODCMC 1;
BA_ "U_P702_MY2024_Rx" SG_ 2612073688 PARSEDPushFcECGtoSODCMC 1;
BA_ "ECGUsedTxSignal" SG_ 2612073688 PARSEDPushFcECGtoSODCMC 1;
BA_ "U_P708_MY2023_Tx" SG_ 2612073688 PARSEDPushFcECGtoSODCMC 1;
BA_ "U_V710_MY2023_Tx" SG_ 2612073688 PARSEDPushFcECGtoSODCMC 1;
BA_ "U_P702_MY2024_Tx" SG_ 2612073688 PARSEDPushFcECGtoSODCMC 1;
BA_ "GenSigStartValue" SG_ 1072 HsaMde_D_Rq 1;
BA_ "WakeupSignal" SG_ 1072 Power_Liftgate_Mode_Cmd 1;
BA_ "GenSigStartValue" SG_ 1072 AccEnbl_B_RqDrv 1;
BA_ "U_P708_MY2023_Rx" SG_ 1072 AccEnbl_B_RqDrv 1;
BA_ "U_V710_MY2023_Rx" SG_ 1072 AccEnbl_B_RqDrv 1;
BA_ "U_P702_MY2024_Rx" SG_ 1072 AccEnbl_B_RqDrv 1;
BA_ "U_P708_MY2023_Rx" SG_ 1072 OdometerMasterValue 1;
BA_ "U_V710_MY2023_Rx" SG_ 1072 OdometerMasterValue 1;
BA_ "U_P702_MY2024_Rx" SG_ 1072 OdometerMasterValue 1;
BA_ "U_V713N_MY2022_Rx" SG_ 1072 OdometerMasterValue 1;
BA_ "U_CDX74X_MY2024_Rx" SG_ 1072 OdometerMasterValue 1;
BA_ "U_P708_MY2023_Rx" SG_ 1072 AccDeny_B_RqIpc 1;
BA_ "U_V710_MY2023_Rx" SG_ 1072 AccDeny_B_RqIpc 1;
BA_ "U_P702_MY2024_Rx" SG_ 1072 AccDeny_B_RqIpc 1;
BA_ "WakeupSignal" SG_ 1072 ePRNDL_MODE 1;
BA_ "U_P708_MY2023_Rx" SG_ 1072 HaDsplyCpblty_B_Stat 1;
BA_ "U_V710_MY2023_Rx" SG_ 1072 HaDsplyCpblty_B_Stat 1;
BA_ "U_P702_MY2024_Rx" SG_ 1072 HaDsplyCpblty_B_Stat 1;
BA_ "U_P708_MY2023_Rx" SG_ 1072 MetricActv_B_Actl 1;
BA_ "U_V710_MY2023_Rx" SG_ 1072 MetricActv_B_Actl 1;
BA_ "U_P702_MY2024_Rx" SG_ 1072 MetricActv_B_Actl 1;
BA_ "U_P708_MY2023_Tx" SG_ 981 AdbRamping_T_Rq 1;
BA_ "U_V710_MY2023_Tx" SG_ 981 AdbRamping_T_Rq 1;
BA_ "U_P702_MY2024_Tx" SG_ 981 AdbRamping_T_Rq 1;
BA_ "GenSigStartValue" SG_ 981 AdbBrdrTop_An_Rq 254;
BA_ "U_P708_MY2023_Tx" SG_ 981 AdbBrdrTop_An_Rq 1;
BA_ "U_V710_MY2023_Tx" SG_ 981 AdbBrdrTop_An_Rq 1;
BA_ "U_P702_MY2024_Tx" SG_ 981 AdbBrdrTop_An_Rq 1;
BA_ "GenSigStartValue" SG_ 981 AdbBrdrRight_L_Stat 510;
BA_ "U_P708_MY2023_Tx" SG_ 981 AdbBrdrRight_L_Stat 1;
BA_ "U_V710_MY2023_Tx" SG_ 981 AdbBrdrRight_L_Stat 1;
BA_ "U_P702_MY2024_Tx" SG_ 981 AdbBrdrRight_L_Stat 1;
BA_ "GenSigStartValue" SG_ 981 AdbBrdrRight_An_Rq 1022;
BA_ "U_P708_MY2023_Tx" SG_ 981 AdbBrdrRight_An_Rq 1;
BA_ "U_V710_MY2023_Tx" SG_ 981 AdbBrdrRight_An_Rq 1;
BA_ "U_P702_MY2024_Tx" SG_ 981 AdbBrdrRight_An_Rq 1;
BA_ "GenSigStartValue" SG_ 981 AdbBrdrLeft_L_Stat 510;
BA_ "U_P708_MY2023_Tx" SG_ 981 AdbBrdrLeft_L_Stat 1;
BA_ "U_V710_MY2023_Tx" SG_ 981 AdbBrdrLeft_L_Stat 1;
BA_ "U_P702_MY2024_Tx" SG_ 981 AdbBrdrLeft_L_Stat 1;
BA_ "GenSigStartValue" SG_ 981 AdbBrdrLeft_An_Rq 1022;
BA_ "U_P708_MY2023_Tx" SG_ 981 AdbBrdrLeft_An_Rq 1;
BA_ "U_V710_MY2023_Tx" SG_ 981 AdbBrdrLeft_An_Rq 1;
BA_ "U_P702_MY2024_Tx" SG_ 981 AdbBrdrLeft_An_Rq 1;
BA_ "GenSigStartValue" SG_ 981 AdbBrdrBottom_An_Rq 62;
BA_ "U_P708_MY2023_Tx" SG_ 981 AdbBrdrBottom_An_Rq 1;
BA_ "U_V710_MY2023_Tx" SG_ 981 AdbBrdrBottom_An_Rq 1;
BA_ "U_P702_MY2024_Tx" SG_ 981 AdbBrdrBottom_An_Rq 1;
BA_ "U_P708_MY2023_Tx" SG_ 981 AdbBeam_D_Rq 1;
BA_ "U_V710_MY2023_Tx" SG_ 981 AdbBeam_D_Rq 1;
BA_ "U_P702_MY2024_Tx" SG_ 981 AdbBeam_D_Rq 1;
BA_ "GenSigSendType" SG_ 2610126946 OTAPhysSODLtoGWM_ECG 3;
BA_ "ECGUsedRxSignal" SG_ 2610126946 OTAPhysSODLtoGWM_ECG 1;
BA_ "U_P708_MY2023_Rx" SG_ 2610126946 OTAPhysSODLtoGWM_ECG 1;
BA_ "U_P702_MY2024_Rx" SG_ 2610126946 OTAPhysSODLtoGWM_ECG 1;
BA_ "U_P708_MY2023_Tx" SG_ 2610126946 OTAPhysSODLtoGWM_ECG 1;
BA_ "U_V710_MY2023_Tx" SG_ 2610126946 OTAPhysSODLtoGWM_ECG 1;
BA_ "U_P702_MY2024_Tx" SG_ 2610126946 OTAPhysSODLtoGWM_ECG 1;
BA_ "GenSigSendType" SG_ 2610006232 OTAPhysGWM_ECGtoSODL 3;
BA_ "U_P708_MY2023_Rx" SG_ 2610006232 OTAPhysGWM_ECGtoSODL 1;
BA_ "U_V710_MY2023_Rx" SG_ 2610006232 OTAPhysGWM_ECGtoSODL 1;
BA_ "U_P702_MY2024_Rx" SG_ 2610006232 OTAPhysGWM_ECGtoSODL 1;
BA_ "ECGUsedTxSignal" SG_ 2610006232 OTAPhysGWM_ECGtoSODL 1;
BA_ "U_P708_MY2023_Tx" SG_ 2610006232 OTAPhysGWM_ECGtoSODL 1;
BA_ "U_P702_MY2024_Tx" SG_ 2610006232 OTAPhysGWM_ECGtoSODL 1;
BA_ "GenSigSendType" SG_ 1985 TesterPhysicalReqCMR_DSMC 3;
BA_ "GenSigStartValue" SG_ 76 PassRstrnInd_Req 3;
BA_ "GenSigStartValue" SG_ 76 SecondRowBucklePsngr 3;
BA_ "GenSigStartValue" SG_ 76 SecondRowBuckleMid 3;
BA_ "GenSigStartValue" SG_ 76 SecondRowBuckleDriver 3;
BA_ "GenSigStartValue" SG_ 76 PsngrFmidDetct_D_Actl 3;
BA_ "GenSigStartValue" SG_ 76 FirstRowBuckleMid 3;
BA_ "U_P708_MY2023_Rx" SG_ 76 FirstRowBuckleMid 1;
BA_ "U_V710_MY2023_Rx" SG_ 76 FirstRowBuckleMid 1;
BA_ "U_P702_MY2024_Rx" SG_ 76 FirstRowBuckleMid 1;
BA_ "GenSigStartValue" SG_ 76 FirstRowBuckleDriver 3;
BA_ "U_P708_MY2023_Rx" SG_ 76 FirstRowBuckleDriver 1;
BA_ "U_V710_MY2023_Rx" SG_ 76 FirstRowBuckleDriver 1;
BA_ "U_P702_MY2024_Rx" SG_ 76 FirstRowBuckleDriver 1;
BA_ "GenSigStartValue" SG_ 76 FirstRowBucklePsngr 3;
BA_ "U_P708_MY2023_Rx" SG_ 76 FirstRowBucklePsngr 1;
BA_ "U_V710_MY2023_Rx" SG_ 76 FirstRowBucklePsngr 1;
BA_ "U_P702_MY2024_Rx" SG_ 76 FirstRowBucklePsngr 1;
BA_ "WakeupSignal" SG_ 76 RstrnImpactEvntStatus 1;
BA_ "U_P708_MY2023_Rx" SG_ 76 RstrnImpactEvntStatus 1;
BA_ "U_V710_MY2023_Rx" SG_ 76 RstrnImpactEvntStatus 1;
BA_ "U_P702_MY2024_Rx" SG_ 76 RstrnImpactEvntStatus 1;
BA_ "U_P708_MY2023_Rx" SG_ 76 EDRTriggerEvntSync 1;
BA_ "U_V710_MY2023_Rx" SG_ 76 EDRTriggerEvntSync 1;
BA_ "U_P702_MY2024_Rx" SG_ 76 EDRTriggerEvntSync 1;
BA_ "MetaData" SG_ 76 FirstRowBuckle_No_Cs 1;
BA_ "U_P708_MY2023_Rx" SG_ 76 FirstRowBuckle_No_Cs 1;
BA_ "U_V710_MY2023_Rx" SG_ 76 FirstRowBuckle_No_Cs 1;
BA_ "U_P702_MY2024_Rx" SG_ 76 FirstRowBuckle_No_Cs 1;
BA_ "MetaData" SG_ 76 RCMStatusMsg2_No_Cnt 1;
BA_ "U_P708_MY2023_Rx" SG_ 76 RCMStatusMsg2_No_Cnt 1;
BA_ "U_V710_MY2023_Rx" SG_ 76 RCMStatusMsg2_No_Cnt 1;
BA_ "U_P702_MY2024_Rx" SG_ 76 RCMStatusMsg2_No_Cnt 1;
BA_ "GenSigSendType" SG_ 2609955032 OTAPhysGWM_ECGtoPSCM 3;
BA_ "U_V713N_MY2022_Rx" SG_ 2609955032 OTAPhysGWM_ECGtoPSCM 1;
BA_ "U_P708_MY2023_Rx" SG_ 2609955032 OTAPhysGWM_ECGtoPSCM 1;
BA_ "U_CDX74X_MY2024_Rx" SG_ 2609955032 OTAPhysGWM_ECGtoPSCM 1;
BA_ "U_V710_MY2023_Rx" SG_ 2609955032 OTAPhysGWM_ECGtoPSCM 1;
BA_ "U_P702_MY2024_Rx" SG_ 2609955032 OTAPhysGWM_ECGtoPSCM 1;
BA_ "ECGUsedTxSignal" SG_ 2609955032 OTAPhysGWM_ECGtoPSCM 1;
BA_ "U_P708_MY2023_Tx" SG_ 2609955032 OTAPhysGWM_ECGtoPSCM 1;
BA_ "U_CDX74X_MY2024_Tx" SG_ 2609955032 OTAPhysGWM_ECGtoPSCM 1;
BA_ "U_V710_MY2023_Tx" SG_ 2609955032 OTAPhysGWM_ECGtoPSCM 1;
BA_ "U_P702_MY2024_Tx" SG_ 2609955032 OTAPhysGWM_ECGtoPSCM 1;
BA_ "GenSigSendType" SG_ 2610126896 OTAPhysPSCMtoGWM_ECG 3;
BA_ "ECGUsedRxSignal" SG_ 2610126896 OTAPhysPSCMtoGWM_ECG 1;
BA_ "U_P708_MY2023_Rx" SG_ 2610126896 OTAPhysPSCMtoGWM_ECG 1;
BA_ "U_CDX74X_MY2024_Rx" SG_ 2610126896 OTAPhysPSCMtoGWM_ECG 1;
BA_ "U_V710_MY2023_Rx" SG_ 2610126896 OTAPhysPSCMtoGWM_ECG 1;
BA_ "U_P702_MY2024_Rx" SG_ 2610126896 OTAPhysPSCMtoGWM_ECG 1;
BA_ "U_V713N_MY2022_Tx" SG_ 2610126896 OTAPhysPSCMtoGWM_ECG 1;
BA_ "U_P708_MY2023_Tx" SG_ 2610126896 OTAPhysPSCMtoGWM_ECG 1;
BA_ "U_CDX74X_MY2024_Tx" SG_ 2610126896 OTAPhysPSCMtoGWM_ECG 1;
BA_ "U_V710_MY2023_Tx" SG_ 2610126896 OTAPhysPSCMtoGWM_ECG 1;
BA_ "U_P702_MY2024_Tx" SG_ 2610126896 OTAPhysPSCMtoGWM_ECG 1;
BA_ "GenSigSendType" SG_ 2611003608 PARSEDPhysGWM_ECGtoPSCM 3;
BA_ "U_V713N_MY2022_Rx" SG_ 2611003608 PARSEDPhysGWM_ECGtoPSCM 1;
BA_ "U_P708_MY2023_Rx" SG_ 2611003608 PARSEDPhysGWM_ECGtoPSCM 1;
BA_ "U_CDX74X_MY2024_Rx" SG_ 2611003608 PARSEDPhysGWM_ECGtoPSCM 1;
BA_ "U_V710_MY2023_Rx" SG_ 2611003608 PARSEDPhysGWM_ECGtoPSCM 1;
BA_ "U_P702_MY2024_Rx" SG_ 2611003608 PARSEDPhysGWM_ECGtoPSCM 1;
BA_ "ECGUsedTxSignal" SG_ 2611003608 PARSEDPhysGWM_ECGtoPSCM 1;
BA_ "U_P708_MY2023_Tx" SG_ 2611003608 PARSEDPhysGWM_ECGtoPSCM 1;
BA_ "U_CDX74X_MY2024_Tx" SG_ 2611003608 PARSEDPhysGWM_ECGtoPSCM 1;
BA_ "U_V710_MY2023_Tx" SG_ 2611003608 PARSEDPhysGWM_ECGtoPSCM 1;
BA_ "U_P702_MY2024_Tx" SG_ 2611003608 PARSEDPhysGWM_ECGtoPSCM 1;
BA_ "GenSigSendType" SG_ 2611175472 PARSEDPhysPSCMtoGWM_ECG 3;
BA_ "ECGUsedRxSignal" SG_ 2611175472 PARSEDPhysPSCMtoGWM_ECG 1;
BA_ "U_P708_MY2023_Rx" SG_ 2611175472 PARSEDPhysPSCMtoGWM_ECG 1;
BA_ "U_CDX74X_MY2024_Rx" SG_ 2611175472 PARSEDPhysPSCMtoGWM_ECG 1;
BA_ "U_V710_MY2023_Rx" SG_ 2611175472 PARSEDPhysPSCMtoGWM_ECG 1;
BA_ "U_P702_MY2024_Rx" SG_ 2611175472 PARSEDPhysPSCMtoGWM_ECG 1;
BA_ "U_V713N_MY2022_Tx" SG_ 2611175472 PARSEDPhysPSCMtoGWM_ECG 1;
BA_ "U_P708_MY2023_Tx" SG_ 2611175472 PARSEDPhysPSCMtoGWM_ECG 1;
BA_ "U_CDX74X_MY2024_Tx" SG_ 2611175472 PARSEDPhysPSCMtoGWM_ECG 1;
BA_ "U_V710_MY2023_Tx" SG_ 2611175472 PARSEDPhysPSCMtoGWM_ECG 1;
BA_ "U_P702_MY2024_Tx" SG_ 2611175472 PARSEDPhysPSCMtoGWM_ECG 1;
BA_ "GenSigSendType" SG_ 2609939672 OTAPhysGWM_ECGtoIPMA 3;
BA_ "U_P708_MY2023_Rx" SG_ 2609939672 OTAPhysGWM_ECGtoIPMA 1;
BA_ "U_V710_MY2023_Rx" SG_ 2609939672 OTAPhysGWM_ECGtoIPMA 1;
BA_ "U_P702_MY2024_Rx" SG_ 2609939672 OTAPhysGWM_ECGtoIPMA 1;
BA_ "ECGUsedTxSignal" SG_ 2609939672 OTAPhysGWM_ECGtoIPMA 1;
BA_ "U_P708_MY2023_Tx" SG_ 2609939672 OTAPhysGWM_ECGtoIPMA 1;
BA_ "U_CDX74X_MY2024_Tx" SG_ 2609939672 OTAPhysGWM_ECGtoIPMA 1;
BA_ "U_V710_MY2023_Tx" SG_ 2609939672 OTAPhysGWM_ECGtoIPMA 1;
BA_ "U_P702_MY2024_Tx" SG_ 2609939672 OTAPhysGWM_ECGtoIPMA 1;
BA_ "GenSigSendType" SG_ 2610126881 OTAPhysIPMAtoGWM_ECG 3;
BA_ "ECGUsedRxSignal" SG_ 2610126881 OTAPhysIPMAtoGWM_ECG 1;
BA_ "U_P708_MY2023_Rx" SG_ 2610126881 OTAPhysIPMAtoGWM_ECG 1;
BA_ "U_CDX74X_MY2024_Rx" SG_ 2610126881 OTAPhysIPMAtoGWM_ECG 1;
BA_ "U_V710_MY2023_Rx" SG_ 2610126881 OTAPhysIPMAtoGWM_ECG 1;
BA_ "U_P702_MY2024_Rx" SG_ 2610126881 OTAPhysIPMAtoGWM_ECG 1;
BA_ "U_P708_MY2023_Tx" SG_ 2610126881 OTAPhysIPMAtoGWM_ECG 1;
BA_ "U_V710_MY2023_Tx" SG_ 2610126881 OTAPhysIPMAtoGWM_ECG 1;
BA_ "U_P702_MY2024_Tx" SG_ 2610126881 OTAPhysIPMAtoGWM_ECG 1;
BA_ "GenSigStartValue" SG_ 1056 ActvDrvMde_D2_Stat 31;
BA_ "U_P708_MY2023_Rx" SG_ 1056 ActvDrvMde_D2_Stat 1;
BA_ "U_V710_MY2023_Rx" SG_ 1056 ActvDrvMde_D2_Stat 1;
BA_ "U_P702_MY2024_Rx" SG_ 1056 ActvDrvMde_D2_Stat 1;
BA_ "GenSigStartValue" SG_ 1056 SelDrvMde_D2_Rq 31;
BA_ "GenSigStartValue" SG_ 1056 AwdMde_D_RqBrk 5;
BA_ "U_P708_MY2023_Rx" SG_ 1150 LocationServices_1 1;
BA_ "U_V710_MY2023_Rx" SG_ 1150 LocationServices_1 1;
BA_ "U_P702_MY2024_Rx" SG_ 1150 LocationServices_1 1;
BA_REL_ "SC_Verification" BU_SG_REL_ PDM SG_ 817 Veh_Lock_EvNum 1;
BA_REL_ "SC_Verification" BU_SG_REL_ DDM SG_ 817 Veh_Lock_EvNum 1;
BA_REL_ "SC_Verification" BU_SG_REL_ PDM SG_ 817 Veh_Lock_Status 1;
BA_REL_ "SC_Verification" BU_SG_REL_ DDM SG_ 817 Veh_Lock_Status 1;
BA_REL_ "SC_Verification" BU_SG_REL_ PDM SG_ 817 RollCodeUnlock 1;
BA_REL_ "SC_Verification" BU_SG_REL_ DDM SG_ 817 RollCodeUnlock 1;
BA_REL_ "SC_Verification" BU_SG_REL_ IPMA_ADAS SG_ 1200 BrkTot_Tq_RqDrv 1;
BA_REL_ "SC_Verification" BU_SG_REL_ IPMA_ADAS SG_ 1056 ActvDrvMde_D2_Stat 1;
VAL_ 1236 ApaSlotRight3_D_Stat 7 "NotUsed_3" 6 "NotUsed_2" 5 "NotUsed_1" 4 "IPeReady" 3 "IPeFound" 2 "IPaReady" 1 "IPaFound" 0 "None" ;
VAL_ 1236 ApaSlotRight3_B_Altr 1 "Available" 0 "NotAvailable" ;
VAL_ 1236 ApaSlotRight2_D_Stat 7 "NotUsed_3" 6 "NotUsed_2" 5 "NotUsed_1" 4 "IPeReady" 3 "IPeFound" 2 "IPaReady" 1 "IPaFound" 0 "None" ;
VAL_ 1236 ApaSlotRight2_B_Altr 1 "Available" 0 "NotAvailable" ;
VAL_ 1236 ApaSlotRight1_D_Stat 7 "NotUsed_3" 6 "NotUsed_2" 5 "NotUsed_1" 4 "IPeReady" 3 "IPeFound" 2 "IPaReady" 1 "IPaFound" 0 "None" ;
VAL_ 1236 ApaSlotRight1_B_Altr 1 "Available" 0 "NotAvailable" ;
VAL_ 1236 ApaSlotRear_D_Stat 1 "True" 0 "False" ;
VAL_ 1235 ApaSlotFront_D_Stat 1 "True" 0 "False" ;
VAL_ 1235 ApaSlotLeft3_D_Stat 7 "NotUsed_3" 6 "NotUsed_2" 5 "NotUsed_1" 4 "IPeReady" 3 "IPeFound" 2 "IPaReady" 1 "IPaFound" 0 "None" ;
VAL_ 1235 ApaSlotLeft3_B_Altr 1 "Available" 0 "NotAvailable" ;
VAL_ 1235 ApaSlotLeft2_D_Stat 7 "NotUsed_3" 6 "NotUsed_2" 5 "NotUsed_1" 4 "IPeReady" 3 "IPeFound" 2 "IPaReady" 1 "IPaFound" 0 "None" ;
VAL_ 1235 ApaSlotLeft2_B_Altr 1 "Unavailable" 0 "Available" ;
VAL_ 1235 ApaSlotLeft1_D_Stat 7 "NotUsed_3" 6 "NotUsed_2" 5 "NotUsed_1" 4 "IPeReady" 3 "IPeFound" 2 "IPaReady" 1 "IPaFound" 0 "None" ;
VAL_ 1235 ApaSlotLeft1_B_Altr 1 "Unavailable" 0 "Available" ;
VAL_ 1234 RmtCtlConfgSrc_D_Stat 7 "NotUsed_2" 6 "NotUsed_1" 5 "BPO" 4 "ApaHmi" 3 "FAP_Handover" 2 "User" 1 "None" 0 "NotDetermined" ;
VAL_ 1234 RmtCtlTrjctry_D_Avail 1 "Available" 0 "NotAvailable" ;
VAL_ 1234 RmtCtlSns_D_Err 1 "Yes" 0 "No" ;
VAL_ 1234 RmtCtlPathPlan_D_Stat 7 "NotUsed_3" 6 "NotUsed_2" 5 "NotUsed_1" 4 "FinishedMovesExceeded" 3 "FinishedDistanceExceeded" 2 "Finished" 1 "Ongoing" 0 "None" ;
VAL_ 1234 RmtCtlPathPlan_B_Err 1 "Yes" 0 "No" ;
VAL_ 1234 RmtCtlAdas_D_Stat 7 "Paused" 6 "Abort" 5 "ManeuverFinished" 4 "EndPositionReached" 3 "Backward" 2 "Forward" 1 "ManeuverBegin" 0 "Inactive" ;
VAL_ 1234 RmtCtlAdas_B_Err 1 "Yes" 0 "No" ;
VAL_ 1234 RmtCtlSnsBlckg_B_Stat 1 "Yes" 0 "No" ;
VAL_ 1233 FreeDrvRear_D_Avail 3 "NotUsed" 2 "Available" 1 "NotAvailable" 0 "Null" ;
VAL_ 1233 FreeDrvFwd_D_Avail 3 "NotUsed" 2 "Available" 1 "NotAvailable" 0 "Null" ;
VAL_ 1233 RmtCtlSnsRrCrnr_D_Stat 3 "Zone3" 2 "Zone2" 1 "Zone1" 0 "Off" ;
VAL_ 1233 RmtCtlSnsRlCrnr_D_Stat 3 "Zone3" 2 "Zone2" 1 "Zone1" 0 "Off" ;
VAL_ 1233 RmtCtlSnsRear_D_Stat 3 "Zone3" 2 "Zone2" 1 "Zone1" 0 "Off" ;
VAL_ 1233 RmtCtlSnsFront_D_Stat 3 "Zone3" 2 "Zone2" 1 "Zone1" 0 "Off" ;
VAL_ 1233 RmtCtlSnsFrCrnr_D_Stat 3 "Zone3" 2 "Zone2" 1 "Zone1" 0 "Off" ;
VAL_ 1233 RmtCtlSnsFlCrnr_D_Stat 3 "Zone3" 2 "Zone2" 1 "Zone1" 0 "Off" ;
VAL_ 1233 RmtCtlSideSnsR4_D_Stat 3 "Zone3" 2 "Zone2" 1 "Zone1" 0 "Off" ;
VAL_ 1233 RmtCtlSideSnsR3_D_Stat 3 "Zone3" 2 "Zone2" 1 "Zone1" 0 "Off" ;
VAL_ 1233 RmtCtlSideSnsR2_D_Stat 3 "Zone3" 2 "Zone2" 1 "Zone1" 0 "Off" ;
VAL_ 1233 RmtCtlSideSnsR1_D_Stat 3 "Zone3" 2 "Zone2" 1 "Zone1" 0 "Off" ;
VAL_ 1233 RmtCtlSideSnsL4_D_Stat 3 "Zone3" 2 "Zone2" 1 "Zone1" 0 "Off" ;
VAL_ 1233 RmtCtlSideSnsL3_D_Stat 3 "Zone3" 2 "Zone2" 1 "Zone1" 0 "Off" ;
VAL_ 1233 RmtCtlSideSnsL2_D_Stat 3 "Zone3" 2 "Zone2" 1 "Zone1" 0 "Off" ;
VAL_ 1233 RmtCtlSideSnsL1_D_Stat 3 "Zone3" 2 "Zone2" 1 "Zone1" 0 "Off" ;
VAL_ 1233 RmtCtlRightOrnt_D_Avail 7 "NotUsed_3" 6 "NotUsed_2" 5 "NotUsed_1" 4 "Both" 3 "Backward" 2 "Forward" 1 "None" 0 "NotDetermined" ;
VAL_ 1233 RmtCtlRight_D_Avail 3 "NotUsed" 2 "Available" 1 "NotAvailable" 0 "Null" ;
VAL_ 1233 RmtCtlRear_D_Avail 3 "NotUsed" 2 "Available" 1 "NotAvailable" 0 "Null" ;
VAL_ 1233 RmtCtlPrkMde_D_Stat 3 "NotUsed" 2 "FreeDrive" 1 "ParkIn" 0 "None" ;
VAL_ 1233 RmtCtlPrkInSlot_D_Stat 7 "NotUsed_3" 6 "NotUsed_2" 5 "NotUsed_1" 4 "Right" 3 "Left" 2 "Rear" 1 "Front" 0 "None" ;
VAL_ 1233 RmtCtlObstcl_B_Stat 1 "Yes" 0 "No" ;
VAL_ 1233 RmtCtlNxtMoveDir_D_Stat 3 "NotUsed" 2 "Backward" 1 "Forward" 0 "Null" ;
VAL_ 1233 RmtCtlMoveDir_D_Stat 3 "NotUsed" 2 "Backward" 1 "Forward" 0 "None" ;
VAL_ 1233 RmtCtlLeftOrnt_D_Avail 7 "NotUsed_3" 6 "NotUsed_2" 5 "NotUsed_1" 4 "Both" 3 "Backward" 2 "Forward" 1 "None" 0 "NotDetermined" ;
VAL_ 1233 RmtCtlLeft_D_Avail 3 "NotUsed" 2 "Available" 1 "NotAvailable" 0 "Null" ;
VAL_ 1233 RmtCtlFront_D_Avail 3 "NotUsed" 2 "Available" 1 "NotAvailable" 0 "Null" ;
VAL_ 817 ChildLckMde_B_Stat 1 "Enable" 0 "Disable" ;
VAL_ 817 VehLckInd_D_Rq 3 "NotUsed" 2 "On_Day" 1 "On_Night" 0 "Off" ;
VAL_ 817 DrTgateOpen_B_Rq 1 "Open" 0 "Null" ;
VAL_ 817 DrTgateExtSwMde_B_Stat 1 "Enable" 0 "Disable" ;
VAL_ 817 Remote_Device_Feedback 7 "Unused3" 6 "Unused2" 5 "Unused1" 4 "Shutdown" 3 "Running" 2 "Starting" 1 "Acknowledge" 0 "Null" ;
VAL_ 817 Veh_Lock_Requestor 31 "Walk_Away_Locking" 30 "Remote_Park_Assist" 29 "DoorsOffToOn_Smart_Unlock" 28 "Rgtm_Shutlock_Switch" 27 "Boundary_Alert" 26 "Transit_Vehicle_Relock" 25 "Transit_Cargo_Relock" 24 "Transit_Ajar_Lock" 23 "Diagnostics" 22 "Console_Lock" 21 "Child_Lock" 20 "Double_Lock" 19 "Passive_Pasenger" 18 "Passive_Driver" 17 "Slam_Lock_Protect" 16 "SYNC" 15 "Passport" 14 "Passive_Smart_Unlock" 13 "Autorelock" 12 "RemoteStart" 0 "Null" 1 "Autolock" 11 "Smart_Unlock" 10 "Sliding_Door" 9 "Passive" 8 "Remote" 7 "Programming" 6 "Powerslide" 5 "Keypad" 4 "Key_Cylinder" 3 "Interior" 2 "Auto_Unlock" ;
VAL_ 817 R_Pwr_Sliding_Dr_Rqst 1 "Active" 0 "Null" ;
VAL_ 817 Power_Liftgate_Rqst 1 "Active" 0 "Null" ;
VAL_ 817 Power_Decklid_Rqst 1 "Active" 0 "Null" ;
VAL_ 817 L_Pwr_Sliding_Dr_Rqst 1 "Active" 0 "Null" ;
VAL_ 817 Veh_Lock_Sub_Id 15 "Unused7" 14 "Unused6" 13 "Unused5" 12 "Unused4" 11 "Unused3" 10 "Unused2" 9 "Unused1" 8 "Customer_8" 7 "Customer_7" 6 "Customer_6" 5 "Customer_5" 4 "Customer_4" 3 "Customer_3" 2 "Customer_2" 1 "Customer_1" 0 "Null" ;
VAL_ 817 Veh_Lock_Status 3 "UNLOCK_DRV" 2 "UNLOCK_ALL" 1 "LOCK_ALL" 0 "LOCK_DBL" ;
VAL_ 817 WindowLockout_B_Stat 1 "Locked" 0 "Unlock" ;
VAL_ 817 Lockmsgtxt_D_Rq 7 "MSG7" 6 "MSG6" 5 "MSG5" 4 "MSG4" 3 "MSG3" 2 "MSG2" 1 "MSG1" 0 "NO_WARNING" ;
VAL_ 817 FobComm_D_Stat 3 "NotUsed" 2 "RemEngStartOK" 1 "RemEngStartFail" 0 "Null" ;
VAL_ 817 LockInhibit 1 "Inhibit" 0 "No_Inhibit" ;
VAL_ 954 CrtsyLghtRear_D_Stat 3 "NotUsed_1" 2 "Automatic" 1 "Manual" 0 "Null" ;
VAL_ 954 LoadShedRelayMde_D_Stat 3 "NotUsed_1" 2 "EngRunRelay" 1 "SnowPlow" 0 "LoadShed" ;
VAL_ 954 CargoLght_D_Stat 3 "NotUsed" 2 "Automatic" 1 "Manual" 0 "Null" ;
VAL_ 954 KeylessIdl_B_Stat 1 "Pressed" 0 "Not_Pressed" ;
VAL_ 954 TlghtTestLght_D_Stat 7 "Error" 6 "AllOff" 5 "TestingReverseLights" 4 "TestingBrakeLights" 3 "TestingLeftTurnSignal" 2 "TestingRightTurnSignal" 1 "ParkingLightsIlluminated" 0 "Null" ;
VAL_ 954 TlghtTestPrecnd_D_Stat 7 "Error" 6 "NotStationary" 5 "InteractionPresent" 4 "PreconditionsPassed" 3 "BattSocLessThan75Percent" 2 "TailLightsOn" 1 "IgnitionNotOn" 0 "Null" ;
VAL_ 954 TlghtTest_D_Stat 3 "InProgress" 2 "Ended" 1 "Completed" 0 "Null" ;
VAL_ 954 LghtAmbDrvMde_B_Stat 1 "Automatic" 0 "Manual" ;
VAL_ 954 TrukBedLght_B_Stat 1 "On" 0 "Off" ;
VAL_ 954 TrlrHitchLamp_D_Stat 1 "On" 0 "Off" ;
VAL_ 954 LicPlateLght_B_Stat 1 "On" 0 "Off" ;
VAL_ 954 ExtLghtRight_D_Stat 3 "NotUsed" 2 "On" 1 "Off" 0 "Null" ;
VAL_ 954 ExtLghtRear_D_Stat 3 "NotUsed" 2 "On" 1 "Off" 0 "Null" ;
VAL_ 954 ExtLghtLeft_D_Stat 3 "NotUsed" 2 "On" 1 "Off" 0 "Null" ;
VAL_ 954 ExtLghtFront_D_Stat 3 "NotUsed" 2 "On" 1 "Off" 0 "Null" ;
VAL_ 954 ExtLghtAlrt_B_Rq 1 "Yes" 0 "No" ;
VAL_ 954 ExtLght_D_Falt 3 "Error" 2 "NoStationary" 1 "StartEngine" 0 "Null" ;
VAL_ 954 TrlrHitchLamp_D2_Stat 3 "NotUsed" 2 "Automatic" 1 "Manual" 0 "Null" ;
VAL_ 954 ChildLckMaint_D_Stat 3 "NotUsed_1" 2 "Overruled" 1 "On" 0 "Off" ;
VAL_ 954 ExtLghtFront_D_RqBody 3 "NotUsed" 2 "On" 1 "Off" 0 "Null" ;
VAL_ 954 LoadShedRelay_B_Rq 1 "Active" 0 "Inactive" ;
VAL_ 954 VehWlcmFrwlMde_D_Stat 7 "IlluminatedExit" 6 "CourtesyLightingDelayExt" 5 "CourtesyLightingExtended" 4 "CourtesyLightingDelayAll" 3 "CourtesyLightingAll" 2 "IlluminatedEntry" 1 "Approach" 0 "Null" ;
VAL_ 954 PwRnngBoardPoll_D_Stat 3 "NotUsed" 2 "PkPresent" 1 "PkNotPresent" 0 "NotPolling" ;
VAL_ 954 PudSptLghtRight_D_Rq 3 "NotUsed" 2 "On" 1 "Off" 0 "Null" ;
VAL_ 954 PudSptLghtLeft_D_Rq 3 "NotUsed" 2 "On" 1 "Off" 0 "Null" ;
VAL_ 954 PoliceDmngLvl_D_Stat 7 "NotUsed" 6 "Off_Night" 5 "Off_Day" 4 "Low1Night" 3 "Low1Day" 2 "Inactive" 1 "Decommissioned" 0 "Null" ;
VAL_ 954 VehWlcmFrwl_D_Stat 3 "RunStart" 2 "Farewell" 1 "Welcome" 0 "Null" ;
VAL_ 954 PosLghtFr_D_Stat 3 "Faulty" 2 "Outage" 1 "On" 0 "Off" ;
VAL_ 954 PosLghtFl_D_Stat 3 "Faulty" 2 "Outage" 1 "On" 0 "Off" ;
VAL_ 820 AhbStatGfhbFdbk_D_Actl 3 "GfhbHighBeamFullyOn" 2 "GfhbHighBeamPartlyOn" 1 "GfhbHighBeamOff" 0 "GfhbUnavailable" ;
VAL_ 820 TurnLampFrOut_B_Stat 1 "Out" 0 "Null" ;
VAL_ 820 TurnLampFlOut_B_Stat 1 "Out" 0 "Null" ;
VAL_ 820 HeadLghtDrvSide_B_Stat 1 "Left_Hand_Traffic" 0 "Right_Hand_Traffic" ;
VAL_ 820 HeadLghtHiOn_B_StatHcm 1 "On" 0 "Off" ;
VAL_ 820 Adaptive_Hdlmp_Fault 1 "Yes" 0 "No" ;
VAL_ 402 CamraFrntBttn_D_Stat3 1 "Pressed" 0 "Not_Pressed" ;
VAL_ 402 PrkAidSwtch_D_RqMnu 1 "Pressed" 0 "Not_Pressed" ;
VAL_ 402 ApaSwtch_D_RqMnu 3 "NotUsed2" 2 "NotUsed1" 1 "Pressed" 0 "Not_Pressed" ;
VAL_ 402 ApaMdeStat_D_RqDrv 7 "Faulty" 6 "Off" 5 "NotUsed2" 4 "NotUsed1" 3 "POA" 2 "PPA" 1 "SAPP" 0 "Inactive" ;
VAL_ 402 CamraViewSplit_B_Rq 1 "On" 0 "Off" ;
VAL_ 402 CamraZoomMan_D_Rq 7 "Unknown" 6 "Invalid" 5 "Zoom_Level_V" 4 "Zoom_Level_IV" 3 "Zoom_Level_III" 2 "Zoom_Level_II" 1 "Zoom_Level_I" 0 "Off" ;
VAL_ 402 CamraOvrlStat_D_Rq 1 "On" 0 "Off" ;
VAL_ 402 CamraOvrlDyn_D_Rq 1 "On" 0 "Off" ;
VAL_ 402 CamAutoTowbarZoom 1 "On" 0 "Off" ;
VAL_ 402 DistanceBarSetting 1 "On" 0 "Off" ;
VAL_ 402 ApaSlotAlrtSet_D_RqDrv 3 "TemporarySuppression" 2 "Disable" 1 "Enable" 0 "None" ;
VAL_ 402 ApaSlotTrgt_D_RqDrv 15 "NotUsed_7" 14 "NotUsed_6" 13 "NotUsed_5" 12 "NotUsed_4" 11 "NotUsed_3" 10 "NotUsed_2" 9 "NotUsed_1" 8 "Front" 7 "Rear" 6 "Right3" 5 "Right2" 4 "Right1" 3 "Left3" 2 "Left2" 1 "Left1" 0 "None" ;
VAL_ 402 ApaFeat_D_RqDrv 7 "Faulty" 6 "Off" 5 "RePA" 4 "ParkIn" 3 "POA" 2 "PPA" 1 "SAPP" 0 "Inactive" ;
VAL_ 402 ApaFeatChange_B_RqDrv 1 "True" 0 "False" ;
VAL_ 1113 TrlrTrgtAcquire_D_Stat 7 "Faulty" 6 "NotUsed_2" 5 "NotUsed_1" 4 "RVCforTBA_Activated" 3 "Processing" 2 "TargetNotAcquired" 1 "TargetAcquired" 0 "Null" ;
VAL_ 1113 TrlrAnOffstDir_D_Calc 3 "NotUSed" 2 "Right" 1 "Left_or_Center" 0 "Null" ;
VAL_ 1113 TrlrAnCalib_B_Complt 1 "Yes" 0 "No" ;
VAL_ 1113 TrlrRvrse_D_Stat 3 "Faulty" 2 "TrailerReverseGuidanceLite" 1 "On" 0 "Off" ;
VAL_ 1113 TrlrAid_D2_Stat 15 "Faulty" 14 "NotUsed_4" 13 "NotUsed_3" 12 "NotUsed_2" 11 "NotUsed_1" 10 "DirtyCamera" 9 "IncorrectLighting" 8 "TrackingLost" 7 "TrackingUnknownConfidence" 6 "TrackingHighConfidence" 5 "TrackingMediumConfidence" 4 "TrackingLowConfidence" 3 "TurnRequested" 2 "DriveStraighRequested" 1 "Initializing" 0 "NotTracking" ;
VAL_ 1113 TrlrAid_An3_Actl 2047 "Faulty" ;
VAL_ 1113 TrlrAid_AnRate2_Actl 1023 "Faulty" ;
VAL_ 1113 HitchToVehAxle_L_Calc 255 "Faulty" ;
VAL_ 1047 TrlrAidSetup_D2_Stat 7 "NotUsed_2" 6 "NotUsed_1" 5 "SetupAcquisitionSuccess" 4 "TbaTadMonitor" 3 "SetupStartAcquisition" 2 "SetupPrepForAcquisition" 1 "TbaActive" 0 "Null" ;
VAL_ 1047 TrlrAidEnbl_D2_Stat 7 "NotUsed_1" 6 "TbaActiveExpertActive" 5 "TbaActiveExpertAvail" 4 "TbaOffTrgActive" 3 "TbaOffTrgSetup" 2 "TbaSetup" 1 "TbaActive" 0 "Inactive" ;
VAL_ 1047 TrlrAidMsgTxt_D2_Rq 63 "Message63" 62 "Message62" 61 "Message61" 60 "Message60" 55 "Message55" 50 "Message50" 45 "Message45" 40 "Message40" 35 "Message35" 31 "Message31" 30 "Message30" 29 "Message29" 28 "Message28" 27 "Message27" 26 "Message26" 25 "Message25" 24 "Message24" 23 "Message23" 22 "Message22" 21 "Message21" 20 "Message20" 19 "Message19" 18 "Message18" 17 "Message17" 16 "Message16" 15 "Message15" 14 "Message14" 13 "Message13" 12 "Message12" 11 "Message11" 10 "Message10" 9 "Message9" 8 "Message8" 7 "Message7" 6 "Message6" 5 "Message5" 4 "Message4" 3 "Message3" 2 "Message2" 1 "Message1" 0 "NoMessage" ;
VAL_ 1047 EsaOn_B_Stat 1 "On" 0 "Off" ;
VAL_ 1047 SelDrvMdeSte_D_Stat 0 "NotAvailable" 1 "Available" 2 "TemporarilyNotAvailable" 3 "Faulty" ;
VAL_ 1006 PersIndexIpmb_D_Actl 7 "Unused_3" 6 "Unused_2" 5 "Unused_1" 4 "Vehicle" 3 "PERS_4" 2 "PERS_3" 1 "PERS_2" 0 "PERS_1" ;
VAL_ 997 PersTurnSglView_D_Stat 3 "NotConfigured" 2 "Enabled" 1 "Disabled" 0 "Null" ;
VAL_ 997 PersIndexCcm_D_Actl 7 "Unused_3" 6 "Unused_2" 5 "Unused_1" 4 "Vehicle" 3 "PERS_4" 2 "PERS_3" 1 "PERS_2" 0 "PERS_1" ;
VAL_ 973 PersCtaSplitView_D_Stat 3 "EnabledFull" 2 "Enabled_180SwitchOnly" 1 "Disabled" 0 "Null" ;
VAL_ 973 LaSysOffStat_D_Dsply 3 "Level_3" 2 "Level_2" 1 "Level_1" 0 "Level_0" ;
VAL_ 973 TsrVl2PrmntMsgTxt_D_Rq 3 "NotUsed" 2 "ShowPermanentlyWithSupp" 1 "ShowPermanentlyWithoutSupp" 0 "DoNotShowSignPermanent" ;
VAL_ 973 TsrVl1PrmntMsgTxt_D_Rq 3 "NotUsed" 2 "ShowPermanentlyWithSupp" 1 "ShowPermanentlyWithoutSupp" 0 "DoNotShowSignPermanent" ;
VAL_ 973 TsrVl2RstrcMsgTxt2_D_Rq 7 "NotUsed" 6 "Time" 5 "Trailer" 4 "Snow" 3 "RainWet" 2 "NoRecognizableRestrictn" 1 "NoSpeedLimitRestrictn" 0 "Null" ;
VAL_ 973 TsrVl1RstrcMsgTxt2_D_Rq 7 "NotUsed" 6 "Time" 5 "Trailer" 4 "Snow" 3 "RainWet" 2 "NoRecognizableRestrictn" 1 "NoSpeedLimitRestrictn" 0 "Null" ;
VAL_ 973 TsrOvtkMsgTxt2_D_Rq 15 "NotUsed5" 14 "NotUsed4" 13 "NotUsed3" 12 "NotUsed2" 11 "NotUsed1" 10 "LimForTrucksCancelled" 9 "LimForTrucksWoQlfdRstrc" 8 "LimForTrucksWithoutRstrc" 7 "LimAllCancelled" 6 "LimAllWithRstrcTime" 5 "LimAllWithRstrcTrailer" 4 "LimAllWithRstrcSnow" 3 "LimAllWithRstrcRain" 2 "LimAllWithoutQlfdRstrc" 1 "LimAllWithoutRestriction" 0 "OvertakingAllowed" ;
VAL_ 973 WwaWarn_B_Rq 1 "On" 0 "Off" ;
VAL_ 973 TsrVlUnitMsgTxt_D_Rq 3 "NoDataExists" 2 "Mph" 1 "Kph" 0 "Null" ;
VAL_ 973 TsrVLim2MsgTxt_D_Rq 255 "NoLimit" 254 "NotUsed2" 253 "NotUsed1" 252 "NotToBeDisplayed" 251 "LimitCancelled" 31 "1F_FA_Message31_250" 30 "Message30" 29 "Message29" 28 "Message28" 27 "Message27" 26 "Message26" 25 "Message25" 24 "Message24" 23 "Message23" 22 "Message22" 21 "Message21" 20 "Message20" 19 "Message19" 18 "Message18" 17 "Message17" 16 "Message16" 15 "Message15" 14 "Message14" 13 "Message13" 12 "Message12" 11 "Message11" 10 "Message10" 9 "Message9" 8 "Message8" 7 "Message7" 6 "Message6" 5 "Message5" 4 "Message4" 3 "Message3" 2 "Message2" 1 "Message1" 0 "Null" ;
VAL_ 973 TsrVLim1MsgTxt_D_Rq 255 "NoLimit" 254 "NotUsed2" 253 "NotUsed1" 252 "NotToBeDisplayed" 251 "LimitCancelled" 31 "1F_FA_Message31_250" 30 "Message30" 29 "Message29" 28 "Message28" 27 "Message27" 26 "Message26" 25 "Message25" 24 "Message24" 23 "Message23" 22 "Message22" 21 "Message21" 20 "Message20" 19 "Message19" 18 "Message18" 17 "Message17" 16 "Message16" 15 "Message15" 14 "Message14" 13 "Message13" 12 "Message12" 11 "Message11" 10 "Message10" 9 "Message9" 8 "Message8" 7 "Message7" 6 "Message6" 5 "Message5" 4 "Message4" 3 "Message3" 2 "Message2" 1 "Message1" 0 "Null" ;
VAL_ 973 TsrVl2StatMsgTxt_D_Rq 3 "LimitOutdated" 2 "LimitReiable" 1 "LimitChanged" 0 "Null" ;
VAL_ 973 TsrVl2RstrcMsgTxt_D_Rq 3 "NotUsed" 2 "NoRecognizableRestriction" 1 "NoSpeedLimitRestriction" 0 "Null" ;
VAL_ 973 TsrVl1StatMsgTxt_D_Rq 3 "LimitOutdated" 2 "LimitReiable" 1 "LimitChanged" 0 "Null" ;
VAL_ 973 TsrVl1RstrcMsgTxt_D_Rq 3 "NotUsed" 2 "NoRecognizableRestriction" 1 "NoSpeedLimitRestriction" 0 "Null" ;
VAL_ 973 TsrStatMsgTxt_D_Rq 7 "NotUsed" 6 "NoDataExists" 5 "TSR_Error" 4 "Available_NavigationOnly" 3 "Available_CameraOnly" 2 "Available_FusionMode" 1 "TSR_Off" 0 "Null" ;
VAL_ 973 TsrOvtkStatMsgTxt_D_Rq 3 "LimitOutdated" 2 "LimitReiable" 1 "LimitChanged" 0 "Null" ;
VAL_ 973 TsrOvtkMsgTxt_D_Rq 7 "LimForTrucksCancelled" 6 "LimForTrucksWoQlfdRstrc" 5 "LimForTrucksWithoutRstrc" 4 "LimAllCancelled" 3 "LimAllWithoutQlfdRstrc" 2 "LimAllWithoutRestriction" 1 "OvertakingAllowed" 0 "Null" ;
VAL_ 973 TsrOswWarnMsgTxt_D_Rq 3 "NotUsed" 2 "True" 1 "False" 0 "Null" ;
VAL_ 973 TsrMsgTxt_D_Rq 15 "NotUsed6" 14 "NotUsed5" 13 "NotUsed4" 12 "NotUsed3" 11 "NotUsed2" 10 "NotUsed1" 9 "RecgnzdSignNotUsblForDsply" 8 "LimitedSystemPerformance" 7 "OffRoad" 6 "RegionNotSupported" 5 "CountryNotSupported" 4 "WrngNavDatIncompDatCarrier" 3 "NoNavDataAvailable" 2 "NoNavAvailableSwitchedOff" 1 "NoInformationAllOK" 0 "Null" ;
VAL_ 973 RoadSignRgltry_D_Dsply 3 "NoEntry" 2 "Stop" 1 "Yield" 0 "None" ;
VAL_ 976 SuspClkSync_No_Actl 255 "Faulty" 254 "NoDataExists" ;
VAL_ 976 SrpSigValid_B_Stat 1 "True" 0 "False" ;
VAL_ 976 SrpHghtRight_L_Actl 511 "Faulty" 510 "NoDataExists" ;
VAL_ 976 SrpHghtLeft_L_Actl 511 "Faulty" 510 "NoDataExists" ;
VAL_ 976 SrpEventRight_D_Stat 3 "Faulty" 2 "Bump" 1 "Pothole" 0 "NoEvent" ;
VAL_ 976 SrpEventLeft_D_Stat 3 "Faulty" 2 "Bump" 1 "Pothole" 0 "NoEvent" ;
VAL_ 976 SrpDistRight_L_Actl 511 "Faulty" 510 "NoDataExists" ;
VAL_ 976 SrpDistLeft_L_Actl 511 "Faulty" 510 "NoDataExists" ;
VAL_ 837 VehGvwr_M_Actl 1023 "Faulty" 1022 "NoDataExists" ;
VAL_ 837 VehCurb_M_Actl 1023 "Faulty" 1022 "NoDataExists" ;
VAL_ 837 Ccd_B_Falt 1 "Yes" 0 "No" ;
VAL_ 837 SelDrvMdeSusp_D_Stat 3 "Faulty" 2 "TemporarilyNotAvailable" 1 "Available" 0 "NotAvailable" ;
VAL_ 837 CcdMsgTxt_D_RqDsply 15 "Unused8" 14 "Unused7" 13 "Unused6" 12 "Unused5" 11 "Unused4" 10 "Unused3" 9 "Unused2" 8 "StationaryMode" 7 "Mode_Change_Unavailable" 6 "CCD_Temporarily_Off" 5 "CCD_Service_Required" 4 "Faulty" 3 "Sport" 2 "Normal" 1 "Comfort" 0 "No_Mode_Selected" ;
VAL_ 837 VdmSustnActv_B_Rq 1 "Active" 0 "Inactive" ;
VAL_ 982 LatCtlRampType_D_Rq 3 "Immediately" 2 "Fast" 1 "Medium" 0 "Slow" ;
VAL_ 982 LatCtlPrecision_D_Rq 3 "NotUsed2" 2 "NotUsed1" 1 "Precise" 0 "Comfortable" ;
VAL_ 982 HandsOffCnfm_B_Rq 1 "Active" 0 "Inactive" ;
VAL_ 982 LatCtl_D2_Rq 7 "NotUsed_5" 6 "NotUsed_4" 5 "NotUsed_3" 4 "NotUsed_2" 3 "SafeRampOut" 2 "PathFollowingExtendedMode" 1 "PathFollowingLimitedMode" 0 "NoLateralControl" ;
VAL_ 1200 BrkRearPCorrltn_B_Stat 1 "Yes" 0 "No" ;
VAL_ 1200 BrkBstrVac_P_Actl 127 "Invalid" ;
VAL_ 1200 YawStabilityIndex 511 "Fault" 510 "NoDataExists" ;
VAL_ 1200 BrkTot_Tq_RqDrv 8191 "Fault" ;
VAL_ 1200 BrkHold_D_Stat 7 "NotUsed_3" 6 "NotUsed_2" 5 "NotUsed_1" 4 "HeldSecondary" 3 "HeldSecure" 2 "Held" 1 "Inactive" 0 "Off" ;
VAL_ 1093 TrlrBrkMde_D_Actl 1 "Electric_Over_Hydraulic" 0 "Electric" ;
VAL_ 1093 TrlrBrkDcnnt_B_Actl 1 "Yes" 0 "No" ;
VAL_ 1093 TrlBrkInitOut_D_Stat 3 "Heavy" 2 "Medium" 1 "Light" 0 "Null" ;
VAL_ 1093 TrlrBrkDsply_B_Rq 1 "Yes" 0 "No" ;
VAL_ 1093 TrlrBrkActCnnct_B_Actl 1 "Yes" 0 "No" ;
VAL_ 1093 StopLamp_B_RqTrlrBrk 1 "Yes" 0 "No" ;
VAL_ 1093 TrlrBrkCtl_B_Falt 1 "Yes" 0 "No" ;
VAL_ 1093 TrlrBrkActCirct_B_Falt 1 "Yes" 0 "No" ;
VAL_ 935 CtaAlrtRight2_D_Stat 7 "NotUsed3" 6 "NotUsed2" 5 "NotUsed1" 4 "AlertZone4" 3 "AlertZone3" 2 "AlertZone2" 1 "AlertZone1" 0 "Off" ;
VAL_ 935 BttRight_D_Stat 7 "BTT5GFault" 6 "Disabled" 5 "Off" 4 "OffTemp" 3 "NotConnected" 2 "Pending" 1 "Connected" 0 "NotDetermined" ;
VAL_ 935 BttRight_D_RqDrv 3 "NotUsed" 2 "Request" 1 "NoRequest" 0 "Null" ;
VAL_ 935 CtaBrkRightMsgTxt_B_Rq 1 "Enable" 0 "Disable" ;
VAL_ 935 CtaRightBrkEnbl_B_Rq 1 "Enable" 0 "Disable" ;
VAL_ 935 CtaRightBrkDecel_B_Rq 1 "Enable" 0 "Disable" ;
VAL_ 935 CtaSnsRight_D_Stat 3 "Invalid" 2 "System_Failure" 1 "Blocked" 0 "Clear" ;
VAL_ 935 CtaAlrtRight_D_Stat 1 "On" 0 "Off" ;
VAL_ 935 CtaRight_D_Stat 7 "NotUsed_3" 6 "NotUsed_2" 5 "NotUsed_1" 4 "Invalid" 3 "Disabled" 2 "On" 1 "Trailer_Tow_Off" 0 "Off" ;
VAL_ 935 SodRight_D_Stat 7 "NotUsed_3" 6 "NotUsed_2" 5 "NotUsed_1" 4 "Invalid" 3 "Disabled" 2 "On" 1 "Trailer_Tow_Off" 0 "Off" ;
VAL_ 935 SodSnsRight_D_Stat 3 "Second_Warning_Audio" 2 "System_Failure" 1 "Blocked" 0 "Clear" ;
VAL_ 935 SodAlrtRight_D_Stat 3 "Bulb_Proveout" 2 "Flash" 1 "On" 0 "Off" ;
VAL_ 935 SodDetctRight_D_Stat 4 "Sensor_Blocked" 3 "Sensor_Fault" 2 "Flash_On" 1 "Alert_On" 0 "AlertOff_FlashOff_SensrClr" ;
VAL_ 1087 TrlrRngeDsply_B_Stat 1 "On" 0 "Off" ;
VAL_ 1087 StopStrtImccTxt_D_Dspl 15 "Message15" 14 "Message14" 13 "Message13" 12 "Message12" 11 "Message11" 10 "Message10" 9 "Message9" 8 "Message8" 7 "Message7" 6 "Message6" 5 "Message5" 4 "Message4" 3 "Message3" 2 "Message2" 1 "Message1" 0 "NoMessage" ;
VAL_ 1087 StopStrtImccActv_D_St 7 "NotUsed_3" 6 "NotUsed_2" 5 "NotUsed_1" 4 "Deactivated" 3 "OnSuspended" 2 "OnActive" 1 "OnNotActive" 0 "Off" ;
VAL_ 1087 StopStrtImccTxt_D_Rq 7 "Message7" 6 "Message6" 5 "Message5" 4 "Message4" 3 "Message3" 2 "Message2" 1 "Message1" 0 "NoMessage" ;
VAL_ 1087 EngIdlShutDownT_D_Stat 255 "NotUsed_13" 254 "NotUsed_12" 253 "NotUsed_11" 252 "NotUsed_10" 251 "NotUsed_9" 250 "NotUsed_8" 249 "NotUsed_7" 248 "NotUsed_6" 247 "NotUsed_5" 246 "NotUsed_4" 245 "NotUsed_3" 244 "NotUsed_2" 243 "NotUsed_1" 242 "Indefinite_Idle" 241 "Selectable_Idle_Not_Active" 240 "IdleMinutes_240" 239 "IdleMinutes_239" 238 "IdleMinutes_238" 237 "IdleMinutes_237" 236 "IdleMinutes_236" 235 "IdleMinutes_235" 234 "IdleMinutes_234" 233 "IdleMinutes_233" 232 "IdleMinutes_232" 231 "IdleMinutes_231" 230 "IdleMinutes_230" 229 "IdleMinutes_229" 228 "IdleMinutes_228" 227 "IdleMinutes_227" 226 "IdleMinutes_226" 225 "IdleMinutes_225" 224 "IdleMinutes_224" 223 "IdleMinutes_223" 222 "IdleMinutes_222" 221 "IdleMinutes_221" 220 "IdleMinutes_220" 219 "IdleMinutes_219" 218 "IdleMinutes_218" 217 "IdleMinutes_217" 216 "IdleMinutes_216" 215 "IdleMinutes_215" 214 "IdleMinutes_214" 213 "IdleMinutes_213" 212 "IdleMinutes_212" 211 "IdleMinutes_211" 210 "IdleMinutes_210" 209 "IdleMinutes_209" 208 "IdleMinutes_208" 207 "IdleMinutes_207" 206 "IdleMinutes_206" 205 "IdleMinutes_205" 204 "IdleMinutes_204" 203 "IdleMinutes_203" 202 "IdleMinutes_202" 201 "IdleMinutes_201" 200 "IdleMinutes_200" 199 "IdleMinutes_199" 198 "IdleMinutes_198" 197 "IdleMinutes_197" 196 "IdleMinutes_196" 195 "IdleMinutes_195" 194 "IdleMinutes_194" 193 "IdleMinutes_193" 192 "IdleMinutes_192" 191 "IdleMinutes_191" 190 "IdleMinutes_190" 189 "IdleMinutes_189" 188 "IdleMinutes_188" 187 "IdleMinutes_187" 186 "IdleMinutes_186" 185 "IdleMinutes_185" 184 "IdleMinutes_184" 183 "IdleMinutes_183" 182 "IdleMinutes_182" 181 "IdleMinutes_181" 180 "IdleMinutes_180" 179 "IdleMinutes_179" 178 "IdleMinutes_178" 177 "IdleMinutes_177" 176 "IdleMinutes_176" 175 "IdleMinutes_175" 174 "IdleMinutes_174" 173 "IdleMinutes_173" 172 "IdleMinutes_172" 171 "IdleMinutes_171" 170 "IdleMinutes_170" 169 "IdleMinutes_169" 168 "IdleMinutes_168" 167 "IdleMinutes_167" 166 "IdleMinutes_166" 165 "IdleMinutes_165" 164 "IdleMinutes_164" 163 "IdleMinutes_163" 162 "IdleMinutes_162" 161 "IdleMinutes_161" 160 "IdleMinutes_160" 159 "IdleMinutes_159" 158 "IdleMinutes_158" 157 "IdleMinutes_157" 156 "IdleMinutes_156" 155 "IdleMinutes_155" 154 "IdleMinutes_154" 153 "IdleMinutes_153" 152 "IdleMinutes_152" 151 "IdleMinutes_151" 150 "IdleMinutes_150" 149 "IdleMinutes_149" 148 "IdleMinutes_148" 147 "IdleMinutes_147" 146 "IdleMinutes_146" 145 "IdleMinutes_145" 144 "IdleMinutes_144" 143 "IdleMinutes_143" 142 "IdleMinutes_142" 141 "IdleMinutes_141" 140 "IdleMinutes_140" 139 "IdleMinutes_139" 138 "IdleMinutes_138" 137 "IdleMinutes_137" 136 "IdleMinutes_136" 135 "IdleMinutes_135" 134 "IdleMinutes_134" 133 "IdleMinutes_133" 132 "IdleMinutes_132" 131 "IdleMinutes_131" 130 "IdleMinutes_130" 129 "IdleMinutes_129" 128 "IdleMinutes_128" 127 "IdleMinutes_127" 126 "IdleMinutes_126" 125 "IdleMinutes_125" 124 "IdleMinutes_124" 123 "IdleMinutes_123" 122 "IdleMinutes_122" 121 "IdleMinutes_121" 120 "IdleMinutes_120" 119 "IdleMinutes_119" 118 "IdleMinutes_118" 117 "IdleMinutes_117" 116 "IdleMinutes_116" 115 "IdleMinutes_115" 114 "IdleMinutes_114" 113 "IdleMinutes_113" 112 "IdleMinutes_112" 111 "IdleMinutes_111" 110 "IdleMinutes_110" 109 "IdleMinutes_109" 108 "IdleMinutes_108" 107 "IdleMinutes_107" 106 "IdleMinutes_106" 105 "IdleMinutes_105" 104 "IdleMinutes_104" 103 "IdleMinutes_103" 102 "IdleMinutes_102" 101 "IdleMinutes_101" 100 "IdleMinutes_100" 99 "IdleMinutes_99" 98 "IdleMinutes_98" 97 "IdleMinutes_97" 96 "IdleMinutes_96" 95 "IdleMinutes_95" 94 "IdleMinutes_94" 93 "IdleMinutes_93" 92 "IdleMinutes_92" 91 "IdleMinutes_91" 90 "IdleMinutes_90" 89 "IdleMinutes_89" 88 "IdleMinutes_88" 87 "IdleMinutes_87" 86 "IdleMinutes_86" 85 "IdleMinutes_85" 84 "IdleMinutes_84" 83 "IdleMinutes_83" 82 "IdleMinutes_82" 81 "IdleMinutes_81" 80 "IdleMinutes_80" 79 "IdleMinutes_79" 78 "IdleMinutes_78" 77 "IdleMinutes_77" 76 "IdleMinutes_76" 75 "IdleMinutes_75" 74 "IdleMinutes_74" 73 "IdleMinutes_73" 72 "IdleMinutes_72" 71 "IdleMinutes_71" 70 "IdleMinutes_70" 69 "IdleMinutes_69" 68 "IdleMinutes_68" 67 "IdleMinutes_67" 66 "IdleMinutes_66" 65 "IdleMinutes_65" 64 "IdleMinutes_64" 63 "IdleMinutes_63" 62 "IdleMinutes_62" 61 "IdleMinutes_61" 60 "IdleMinutes_60" 59 "IdleMinutes_59" 58 "IdleMinutes_58" 57 "IdleMinutes_57" 56 "IdleMinutes_56" 55 "IdleMinutes_55" 54 "IdleMinutes_54" 53 "IdleMinutes_53" 52 "IdleMinutes_52" 51 "IdleMinutes_51" 50 "IdleMinutes_50" 49 "IdleMinutes_49" 48 "IdleMinutes_48" 47 "IdleMinutes_47" 46 "IdleMinutes_46" 45 "IdleMinutes_45" 44 "IdleMinutes_44" 43 "IdleMinutes_43" 42 "IdleMinutes_42" 41 "IdleMinutes_41" 40 "IdleMinutes_40" 39 "IdleMinutes_39" 38 "IdleMinutes_38" 37 "IdleMinutes_37" 36 "IdleMinutes_36" 35 "IdleMinutes_35" 34 "IdleMinutes_34" 33 "IdleMinutes_33" 32 "IdleMinutes_32" 31 "IdleMinutes_31" 30 "IdleMinutes_30" 29 "IdleMinutes_29" 28 "IdleMinutes_28" 27 "IdleMinutes_27" 26 "IdleMinutes_26" 25 "IdleMinutes_25" 24 "IdleMinutes_24" 23 "IdleMinutes_23" 22 "IdleMinutes_22" 21 "IdleMinutes_21" 20 "IdleMinutes_20" 19 "IdleMinutes_19" 18 "IdleMinutes_18" 17 "IdleMinutes_17" 16 "IdleMinutes_16" 15 "IdleMinutes_15" 14 "IdleMinutes_14" 13 "IdleMinutes_13" 12 "IdleMinutes_12" 11 "IdleMinutes_11" 10 "IdleMinutes_10" 9 "IdleMinutes_9" 8 "IdleMinutes_8" 7 "IdleMinutes_7" 6 "IdleMinutes_6" 5 "IdleMinutes_5" 4 "IdleMinutes_4" 3 "IdleMinutes_3" 2 "IdleMinutes_2" 1 "IdleMinute_1" 0 "Null" ;
VAL_ 1087 DcacFaltMsgTxt_D2_Rq 35 "NotUsed_1" 34 "FrontTrnkPlgWarnDertExceed" 33 "FrontTrnkPlgWarnDerate" 32 "FrontTrnkPlgWarnFullPw" 31 "IpcPlugWarnDrive" 30 "DcacbOvercurrentLp" 29 "DcacbService" 28 "DcacbNotAvailable" 27 "DcacbAcOnOutput" 26 "DcacbTemperature" 25 "DcacbGfci" 24 "DcacbOvercurrent" 23 "PpoUsageWhenVehlsCharging" 22 "RpsNewKeyCycleWarning" 21 "LowSocRpsWarning" 20 "RpsResetWarn_ChngDrvToPark" 19 "RpsResetWarning" 18 "FirstRpsWarning" 63 "NotUsed_29" 17 "PowerTakeoff" 16 "HevDerate" 15 "HvacOn" 14 "OvercurrentLP" 13 "EngineRun" 12 "Service" 11 "NotAvailable" 10 "PlugWarn" 9 "PlugWarnDrive" 8 "BreakerC" 7 "BreakerB" 6 "BreakerA" 5 "FuelLow" 4 "AcOnOutput" 3 "Temperature" 2 "Gfci" 1 "Overcurrent" 0 "Ok" ;
VAL_ 1087 ClimtCool_D_RqPt 3 "NotUsed_2" 2 "NotUsed_1" 1 "On" 0 "Off" ;
VAL_ 1087 StrtInGearMsgTxt_D_Rq 15 "Message15" 14 "Message14" 13 "Message13" 12 "Message12" 11 "Message11" 10 "Message10" 9 "Message9" 8 "Message8" 7 "Message7" 6 "Message6" 5 "Message5" 4 "Message4" 3 "Message3" 2 "Message2" 1 "Message1" 0 "NoMessage" ;
VAL_ 1087 IgnOffInhbt_B_Stat 1 "Yes" 0 "No" ;
VAL_ 1087 BtsiShifInhbt_B_RqPt 1 "Yes" 0 "No" ;
VAL_ 1087 FapLcInhbt_B_Rq 1 "Yes" 0 "No" ;
VAL_ 1087 FapLcStopHold_B_Rq 1 "Yes" 0 "No" ;
VAL_ 1087 FapLcPrchgBrk_B_Rq 1 "Yes" 0 "No" ;
VAL_ 1087 FapLcObstcl_B_Stat 1 "Yes" 0 "No" ;
VAL_ 1087 FapLcMaxGrdInhbt_B_Stat 1 "Yes" 0 "No" ;
VAL_ 1087 FapLcMaxGrdAbrt_B_Stat 1 "Yes" 0 "No" ;
VAL_ 1087 FapLcActv_B_Stat 1 "Yes" 0 "No" ;
VAL_ 1087 AdasLcObtclAbrt_B_Stat 1 "Yes" 0 "No" ;
VAL_ 1076 AutoRgen_D_Rq 3 "NotUsed" 2 "AutExhFilterCleanOFF" 1 "AutExhFilterCleanON" 0 "No_Mode_Selected" ;
VAL_ 1076 W2S_LAMP_OK 1 "Yes" 0 "No" ;
VAL_ 1076 OdoTripRx_B_Actl 1 "Yes" 0 "No" ;
VAL_ 1076 DrvSlipCtlMde_B_RqMyKey 1 "On" 0 "Off" ;
VAL_ 1076 FuelLvlWarn_D_Actl 3 "NotUsed" 2 "VeryLow" 1 "Low" 0 "OK" ;
VAL_ 1076 FuelSecndActv_B_Actl 1 "Yes" 0 "No" ;
VAL_ 1076 HILL_DESC_SW 1 "On" 0 "Off" ;
VAL_ 1076 FUEL_SENSOR_NUM 1 "Dual_Sensors" 0 "Single_Sensor" ;
VAL_ 1076 TirePReset_B_Rq 1 "Reset" 0 "Null" ;
VAL_ 1238 TjaCanclMsgTxt_D_Dsply 15 "NotUsed_9" 14 "NotUsed_8" 13 "NotUsed_7" 12 "NotUsed_6" 11 "NotUsed_5" 10 "NotUsed_4" 9 "NotUsed_3" 8 "NotUsed_2" 7 "NotUsed_1" 6 "DriverNotSeen2" 5 "DriverNotSeen1" 4 "HandsFreeUnavailInThisArea" 3 "HandsFreeUnavailForMaxSpd" 2 "CancelledForLaneConditions" 1 "CancelledForRoadCurvature" 0 "NoMessage" ;
VAL_ 1238 GfhbMnu_D_Rq 3 "EnableADB" 2 "EnableGFHB" 1 "Disable" 0 "Null" ;
VAL_ 1238 AhbcMnu_D_Rq 3 "NotUsed" 2 "Enable" 1 "Disable" 0 "Null" ;
VAL_ 1238 TjaLaneBias_D_Stat 7 "NotUsed" 6 "ElBiasRight" 5 "ElBiasLeft" 4 "SystemBiasRight" 3 "SystemBiasLeft" 2 "ManualBiasRight" 1 "ManualBiasLeft" 0 "NoBias" ;
VAL_ 1238 TjaLaneBiasEnbl_D_Stat 3 "NotUsed" 0 "Inactive" 2 "Enable" 1 "Disable" ;
VAL_ 1238 IaccVAdjReas_D_Dsply 15 "NotUsed_21" 11 "NotUsed_1" 10 "SpeedSign" 9 "LeftRamp" 8 "RightRamp" 7 "Roundabout_CCW" 6 "Roundabout_CW" 5 "LeftCurve" 4 "RightCurve" 3 "LeftTurnIntersection" 2 "RightTurnIntersection" 1 "RoadGeometryUnavailable" 0 "NoDisplay" ;
VAL_ 1072 DrvSlipCtlMde_D_Rq 3 "App_Specific_Off_Mode_3" 2 "App_Specific_Off_Mode_2" 1 "App_Specific_Off_Mode_1" 0 "Default_Mode" ;
VAL_ 1072 EngIdlShutDown_B_RqDrv 1 "Inhibit" 0 "No_Inibit" ;
VAL_ 1072 HsaMde_D_Rq 3 "Undefined" 2 "Manual" 1 "Automatic" 0 "Off" ;
VAL_ 1072 NtrlTowMdeEnbl_B_RqDrv 1 "Yes" 0 "No" ;
VAL_ 1072 LscmbbStat_B_Actl 1 "On" 0 "Off" ;
VAL_ 1072 BulbChkActv_B_Stat 1 "Active" 0 "Inactive" ;
VAL_ 1072 ParkDetect_Stat 1 "Park" 0 "Not_Park" ;
VAL_ 1072 ReducedGuard_D_Rq 3 "NotUsed" 2 "On" 1 "Off" 0 "Null" ;
VAL_ 1072 TrlrBrkMde_D_Rq 1 "ElectricOverHydraulic" 0 "Electric" ;
VAL_ 1072 TRLR_SWAY_CONFIG_CMD 1 "On" 0 "Off" ;
VAL_ 1072 TRAILER_BRAKE_CONFIG 1 "Yes" 0 "No" ;
VAL_ 1072 Power_Liftgate_Mode_Cmd 1 "Enable" 0 "Disable" ;
VAL_ 1072 AccEnbl_B_RqDrv 1 "Adaptive_Cruise" 0 "Normal_Cruise" ;
VAL_ 1072 OdometerMasterValue 16777215 "Invalid" ;
VAL_ 1072 EngOilLife_B_RqReset 1 "Yes" 0 "No" ;
VAL_ 1072 MetricActvTe_B_Actl 1 "Active" 0 "Inactive" ;
VAL_ 1072 AccDeny_B_RqIpc 1 "Yes" 0 "No" ;
VAL_ 1072 ePRNDL_MODE 1 "On" 0 "Off" ;
VAL_ 1072 HaDsplyCpblty_B_Stat 1 "Available" 0 "NotAvailable" ;
VAL_ 1072 DrvSlipCtlMde_B_Rq2 1 "Pressed" 0 "Not_Pressed" ;
VAL_ 1072 MetricActv_B_Actl 1 "Active" 0 "Inactive" ;
VAL_ 1072 KeyTypeChngMykey_D_Rq 3 "Search_PE_BackupSlot" 2 "Clear_All_MyKeys" 1 "Request_New_MyKey" 0 "None" ;
VAL_ 1072 ManRgen_D_Rq 3 "NotUsed2" 2 "NotUsed1" 1 "CustInitManExhFilterClean" 0 "No_Customer_Request" ;
VAL_ 981 AdbBrdrTop_An_Rq 255 "Faulty" 254 "NoDataExists" ;
VAL_ 981 AdbBrdrRight_L_Stat 511 "Faulty" 510 "NoDataExists" ;
VAL_ 981 AdbBrdrRight_An_Rq 1023 "Faulty" 1022 "NoDataExists" ;
VAL_ 981 AdbBrdrLeft_L_Stat 511 "Faulty" 510 "NoDataExists" ;
VAL_ 981 AdbBrdrLeft_An_Rq 1023 "Faulty" 1022 "NoDataExists" ;
VAL_ 981 AdbBrdrBottom_An_Rq 63 "Faulty" 62 "NoDataExists" ;
VAL_ 981 AdbBeam_D_Rq 7 "NotUsed_3" 6 "NotUsed_2" 5 "NotUsed_1" 4 "FullHighBeam" 3 "Spot_BothSide" 2 "Spot_OnlyRightSide" 1 "Spot_OnlyLeftSide" 0 "NoHighBeam" ;
VAL_ 76 PassRstrnInd_Req 3 "ABOnNotIllum_OffNotIllum" 2 "AirbagOnNot_Illum_OffIllum" 1 "AirbagOn_Illum_OffNotIllum" 0 "AirbagOn_Illum_Off_Illum" ;
VAL_ 76 SecondRowBucklePsngr 3 "Unknown" 2 "Unbelted" 1 "Belted" 0 "Faulty" ;
VAL_ 76 SecondRowBuckleMid 3 "Unknown" 2 "Unbelted" 1 "Belted" 0 "Faulty" ;
VAL_ 76 SecondRowBuckleDriver 3 "Unknown" 2 "Unbelted" 1 "Belted" 0 "Faulty" ;
VAL_ 76 RILReq 3 "Not_Used" 2 "Plant_Mode" 1 "On" 0 "Off" ;
VAL_ 76 PsngrFmidDetct_D_Actl 3 "Unknown" 2 "Empty" 1 "Occupied" 0 "Fault" ;
VAL_ 76 FirstRowBuckleMid 3 "Unknown" 2 "Unbelted" 1 "Belted" 0 "Faulty" ;
VAL_ 76 FirstRowBuckleDriver 3 "Unknown" 2 "Unbelted" 1 "Belted" 0 "Faulty" ;
VAL_ 76 FirstRowBucklePsngr 3 "Unknown" 2 "Unbelted" 1 "Belted" 0 "Faulty" ;
VAL_ 76 RstrnImpactEvntStatus 7 "Invalid" 6 "Not_Used_4" 5 "Threshold_2_Exceeded" 4 "Not_Used_3" 3 "Threshold_1_Exceeded" 2 "Not_Used_2" 1 "Not_Used_1" 0 "Normal" ;
VAL_ 76 EDRTriggerEvntSync 1 "Threshold_Exceeded" 0 "Normal" ;
VAL_ 1056 SelDrvMdeHmi03_D_Rq 31 "Faulty" 30 "SelDrvMde31" 29 "SelDrvMde30" 28 "SelDrvMde29" 27 "SelDrvMde28" 26 "SelDrvMde27" 25 "SelDrvMde26" 24 "SelDrvMde25" 23 "SelDrvMde24" 22 "SelDrvMde23" 21 "SelDrvMde22" 20 "SelDrvMde21" 19 "SelDrvMde20" 18 "SelDrvMde19" 17 "SelDrvMde18" 16 "SelDrvMde17" 15 "SelDrvMde16" 14 "SelDrvMde15" 13 "SelDrvMde14" 12 "SelDrvMde13" 11 "SelDrvMde12" 10 "SelDrvMde11" 9 "SelDrvMde10" 8 "SelDrvMde09" 7 "SelDrvMde08" 6 "SelDrvMde07" 5 "SelDrvMde06" 4 "SelDrvMde05" 3 "SelDrvMde04" 2 "SelDrvMde03" 1 "SelDrvMde02" 0 "SelDrvMde01" ;
VAL_ 1056 AutoEpbButtnOn_B_Stat 1 "On" 0 "Off" ;
VAL_ 1056 AutoEpbMsgTxt_D_Rq 7 "Message7" 6 "Message6" 5 "Message5" 4 "Message4" 3 "Message3" 2 "Message2" 1 "Message1" 0 "NoMessage" ;
VAL_ 1056 SelDrvMdePos12_B_Avail 1 "Available" 0 "NotAvailable" ;
VAL_ 1056 SelDrvMdePos11_B_Avail 1 "Available" 0 "NotAvailable" ;
VAL_ 1056 SelDrvMdePos10_B_Avail 1 "Available" 0 "NotAvailable" ;
VAL_ 1056 SelDrvMdePos09_B_Avail 1 "Available" 0 "NotAvailable" ;
VAL_ 1056 SelDrvMdePos08_B_Avail 1 "Available" 0 "NotAvailable" ;
VAL_ 1056 SelDrvMdePos07_B_Avail 1 "Available" 0 "NotAvailable" ;
VAL_ 1056 SelDrvMdePos06_B_Avail 1 "Available" 0 "NotAvailable" ;
VAL_ 1056 SelDrvMdePos05_B_Avail 1 "Available" 0 "NotAvailable" ;
VAL_ 1056 SelDrvMdePos04_B_Avail 1 "Available" 0 "NotAvailable" ;
VAL_ 1056 SelDrvMdePos03_B_Avail 1 "Available" 0 "NotAvailable" ;
VAL_ 1056 SelDrvMdePos02_B_Avail 1 "Available" 0 "NotAvailable" ;
VAL_ 1056 SelDrvMdePos01_B_Avail 1 "Available" 0 "NotAvailable" ;
VAL_ 1056 ActvDrvMde_D2_Stat 31 "Faulty" 30 "SelDrvMde31" 29 "SelDrvMde30" 28 "SelDrvMde29" 27 "SelDrvMde28" 26 "SelDrvMde27" 25 "SelDrvMde26" 24 "SelDrvMde25" 23 "SelDrvMde24" 22 "SelDrvMde23" 21 "SelDrvMde22" 20 "SelDrvMde21" 19 "SelDrvMde20" 18 "SelDrvMde19" 17 "SelDrvMde18" 16 "SelDrvMde17" 15 "SelDrvMde16" 14 "SelDrvMde15" 13 "SelDrvMde14" 12 "SelDrvMde13" 11 "SelDrvMde12" 10 "SelDrvMde11" 9 "SelDrvMde10" 8 "SelDrvMde09" 7 "SelDrvMde08" 6 "SelDrvMde07" 5 "SelDrvMde06" 4 "SelDrvMde05" 3 "SelDrvMde04" 2 "SelDrvMde03" 1 "SelDrvMde02" 0 "SelDrvMde01" ;
VAL_ 1056 SelDrvMde_D2_Rq 31 "Faulty" 30 "SelDrvMde31" 29 "SelDrvMde30" 28 "SelDrvMde29" 27 "SelDrvMde28" 26 "SelDrvMde27" 25 "SelDrvMde26" 24 "SelDrvMde25" 23 "SelDrvMde24" 22 "SelDrvMde23" 21 "SelDrvMde22" 20 "SelDrvMde21" 19 "SelDrvMde20" 18 "SelDrvMde19" 17 "SelDrvMde18" 16 "SelDrvMde17" 15 "SelDrvMde16" 14 "SelDrvMde15" 13 "SelDrvMde14" 12 "SelDrvMde13" 11 "SelDrvMde12" 10 "SelDrvMde11" 9 "SelDrvMde10" 8 "SelDrvMde09" 7 "SelDrvMde08" 6 "SelDrvMde07" 5 "SelDrvMde06" 4 "SelDrvMde05" 3 "SelDrvMde04" 2 "SelDrvMde03" 1 "SelDrvMde02" 0 "SelDrvMde01" ;
VAL_ 1056 SelDrvMdePt_D_Rq 31 "Faulty" 30 "NotUsed15" 29 "NotUsed14" 28 "NotUsed13" 27 "NotUsed12" 26 "NotUsed11" 25 "NotUsed10" 24 "NotUsed9" 23 "NotUsed8" 22 "NotUsed7" 21 "CustomMode" 20 "TrackMode" 19 "OnePedalDrive" 18 "EvLaterChargerMode" 17 "EvNowMode" 16 "DragMode" 15 "HighSpeedDesertMode_Baja" 14 "SportAdaptiveMode" 13 "NotAvailable_13" 12 "NotAvailable_12" 11 "NotAvailable_11" 10 "NotAvailable_10" 9 "RockCrawlMode" 8 "MudRutsMode" 7 "SandMode" 6 "EconomyMode" 5 "GrassGravelSnow" 4 "NotAvailable_04" 3 "TowHaulMode" 2 "NotAvailable_02" 1 "SportMode" 0 "NormalMode" ;
VAL_ 1056 SelDrvMdeMsgTxt_D_Rq 15 "Message15" 14 "Message14" 13 "Message13" 12 "Message12" 11 "Message11" 10 "Message10" 9 "Message9" 8 "Message8" 7 "Message7" 6 "Message6" 5 "Message5" 4 "Message4" 3 "Message3" 2 "Message2" 1 "Message1" 0 "NoMessage" ;
VAL_ 1056 SelDrvMde_D_Stat 3 "NotUsed" 2 "DriveModeChangeRequest" 1 "DriveModeChangeSelection" 0 "NoDriveModeChangeRequest" ;
VAL_ 1056 AwdMde_D_RqBrk 7 "Faulty" 6 "NotUsed2" 5 "NoRequest" 4 "Neutral" 3 "FourByFourLow" 2 "FourByFourHigh" 1 "FourByFourAuto" 0 "FourByTwo" ;
VAL_ 1056 AutoEpbDsply_D_Stat 3 "NotUsed" 2 "GreyedOut" 1 "Available" 0 "NotAvailable" ;
